VERSION ""

NS_ :

BS_:

BU_: CHUD_LS VKM_LS RCRM_LS MSM_RR_LS MSM_LR_LS CGM_LS BSM_LS VPM_LS ISRVM_LS DCAC_LS TouchPad_LS RSC_LS LVMPC_LS EOCM2B_K1_LS EOCM2A_K1_LS LCM_LS TIM_B_LS V2V_LS TCP_LS CSM_LS EOCM2B_K2_LS EOCM2A_K2_LS TIM_A_LS LVMNav_LS HFP_LS EDI_LS ARB_LS RSE_LS Dummy_LS VIS2_LS ICS_LS FCM_LS EOCM_F_LS VICM_LS AGC_LS MSM_P_LS OTIM_LS HVSM_R_LS HVSM_F_LS DVB_T_LS SBZA_R_LS PSD_R_LS PSD_L_LS UHP_Low UPA_LS STC_LS SBZA_L_LS PTM_LS ONSTAR_LS APA_LS TestTool_LS PHS_LS PDIM_LS CHM_LS RSA_LS AMP_LS HUD_LS MSM_LS HBSM_LS SCL_LS ECC_LS RadioHead_LS PEPS_LS IPC_LS AOS_LS SDM_LS TIM_LS BCM_LS

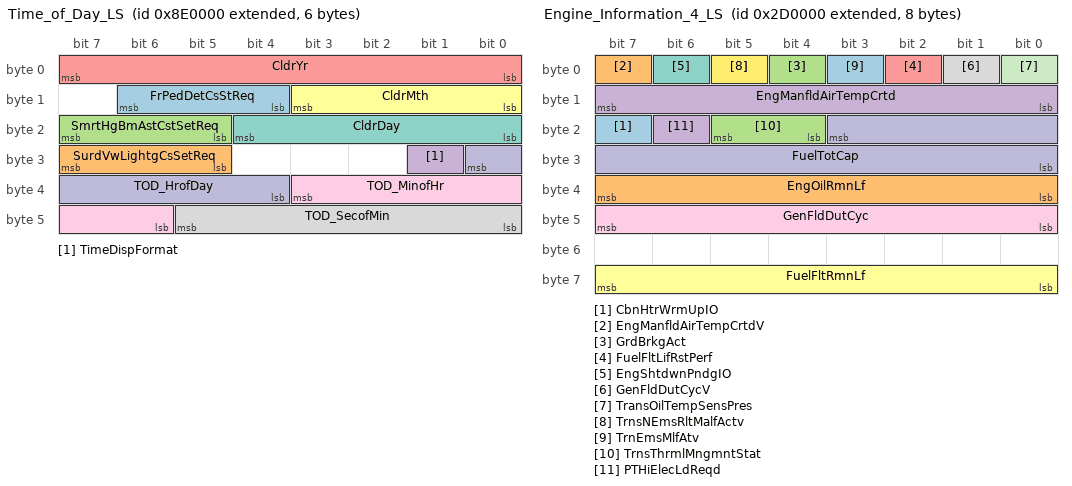
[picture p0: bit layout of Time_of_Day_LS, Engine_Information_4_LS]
BO_ 2156789760 Time_of_Day_LS: 6 RadioHead_LS
 SG_ FrPedDetCsStReq : 14|3@0+ (1,0) [0|7] ""  EOCM2B_K1_LS,EOCM2A_K1_LS,EOCM_F_LS,FCM_LS
 SG_ SurdVwLightgCsSetReq : 31|3@0+ (1,0) [0|7] ""  VPM_LS
 SG_ SmrtHgBmAstCstSetReq : 23|3@0+ (1,0) [0|7] ""  EOCM2A_K2_LS,FCM_LS,VIS2_LS
 SG_ TimeDispFormat : 25|1@0+ (1,0) [0|1] ""  RSE_LS,EOCM2B_K1_LS,EOCM2A_K1_LS,VPM_LS,LVMPC_LS,LVMNav_LS,EDI_LS,BSM_LS,VICM_LS,CHUD_LS,HUD_LS
 SG_ CldrYr : 7|8@0+ (1,2000) [2000|2255] "year"  RSE_LS,EOCM2B_K1_LS,EOCM2A_K1_LS,VPM_LS,LVMPC_LS,LVMNav_LS,EDI_LS,FCM_LS,BSM_LS,VICM_LS,EOCM_F_LS,UHP_Low,BCM_LS,CHUD_LS,HUD_LS
 SG_ CldrMth : 11|4@0+ (1,0) [0|15] ""  RSE_LS,EOCM2B_K1_LS,EOCM2A_K1_LS,VPM_LS,LVMPC_LS,LVMNav_LS,EDI_LS,FCM_LS,ECC_LS,BSM_LS,VICM_LS,EOCM_F_LS,UHP_Low,BCM_LS,CHUD_LS,HUD_LS
 SG_ CldrDay : 20|5@0+ (1,0) [0|31] "days"  RSE_LS,EOCM2B_K1_LS,EOCM2A_K1_LS,VPM_LS,LVMPC_LS,LVMNav_LS,EDI_LS,FCM_LS,ECC_LS,BSM_LS,VICM_LS,EOCM_F_LS,UHP_Low,BCM_LS,CHUD_LS,HUD_LS
 SG_ TOD_SecofMin : 45|6@0+ (1,0) [0|63] "s"  RSE_LS,EOCM2B_K1_LS,EOCM2A_K1_LS,VPM_LS,VIS2_LS,LVMPC_LS,FCM_LS,EDI_LS,LVMNav_LS,BSM_LS,VICM_LS,ECC_LS,UHP_Low,CHUD_LS,HUD_LS,BCM_LS
 SG_ TOD_MinofHr : 35|6@0+ (1,0) [0|63] "min"  RSE_LS,EOCM2B_K1_LS,EOCM2A_K1_LS,VPM_LS,VIS2_LS,LVMPC_LS,FCM_LS,EDI_LS,LVMNav_LS,BSM_LS,VICM_LS,ECC_LS,UHP_Low,CHUD_LS,HUD_LS,BCM_LS
 SG_ TOD_HrofDay : 24|5@0+ (1,0) [0|31] "hr"  RSE_LS,EOCM2B_K1_LS,EOCM2A_K1_LS,VPM_LS,VIS2_LS,LVMPC_LS,FCM_LS,EDI_LS,LVMNav_LS,BSM_LS,VICM_LS,ECC_LS,UHP_Low,CHUD_LS,HUD_LS,BCM_LS

BO_ 2155020288 Language_Selection_LS: 1 RadioHead_LS
 SG_ ChVolRq2 : 7|2@0+ (1,0) [0|3] ""  CGM_LS,CHM_LS,AMP_LS,RadioHead_LS
 SG_ LngSelExt : 5|6@0+ (1,0) [0|63] ""  CGM_LS,RSE_LS,TCP_LS,VPM_LS,RSC_LS,LVMNav_LS,RSA_LS,PDIM_LS,OTIM_LS,LVMPC_LS,UHP_Low,ONSTAR_LS,CHUD_LS,HUD_LS

BO_ 2150432768 Engine_Information_4_LS: 8 BCM_LS
 SG_ CbnHtrWrmUpIO : 23|1@0+ (1,0) [0|1] ""  IPC_LS,CGM_LS
 SG_ EngManfldAirTempCrtdV : 7|1@0+ (1,0) [0|1] ""  CGM_LS,ECC_LS
 SG_ GrdBrkgAct : 4|1@0+ (1,0) [0|1] ""  CSM_LS,RadioHead_LS,CGM_LS,IPC_LS
 SG_ EngManfldAirTempCrtd : 15|8@0+ (1,-40) [-40|215] "deg C"  CGM_LS,ECC_LS
 SG_ FuelFltLifRstPerf : 2|1@0+ (1,0) [0|1] ""  CSM_LS,CGM_LS,RadioHead_LS,IPC_LS
 SG_ FuelFltRmnLf : 63|8@0+ (0.392157,0) [0|100.000035] "%"  CSM_LS,CGM_LS,RadioHead_LS,IPC_LS
 SG_ EngShtdwnPndgIO : 6|1@0+ (1,0) [0|1] ""  CSM_LS,CGM_LS,RadioHead_LS,IPC_LS
 SG_ GenFldDutCycV : 1|1@0+ (1,0) [0|1] ""  CSM_LS,CGM_LS,RadioHead_LS,ECC_LS
 SG_ GenFldDutCyc : 47|8@0+ (0.392157,0) [0|100.000035] "%"  CSM_LS,CGM_LS,RadioHead_LS,ECC_LS
 SG_ FuelTotCap : 19|12@0+ (0.125,0) [0|511.875] "liters"  TCP_LS,CGM_LS,CSM_LS,RadioHead_LS,IPC_LS,ONSTAR_LS
 SG_ TransOilTempSensPres : 0|1@0+ (1,0) [0|1] ""  CSM_LS,CGM_LS,RadioHead_LS,IPC_LS
 SG_ TrnsNEmsRltMalfActv : 5|1@0+ (1,0) [0|1] ""  CSM_LS,CGM_LS,RadioHead_LS,IPC_LS
 SG_ TrnEmsMlfAtv : 3|1@0+ (1,0) [0|1] ""  CSM_LS,CGM_LS,RadioHead_LS,IPC_LS
 SG_ EngOilRmnLf : 39|8@0+ (0.392157,0) [0|100.000035] "%"  CSM_LS,TCP_LS,CGM_LS,RadioHead_LS,ONSTAR_LS,IPC_LS
 SG_ TrnsThrmlMngmntStat : 21|2@0+ (1,0) [0|3] ""  CSM_LS,TCP_LS,CGM_LS,RadioHead_LS,ONSTAR_LS,IPC_LS
 SG_ PTHiElecLdReqd : 22|1@0+ (1,0) [0|1] ""  CSM_LS,CGM_LS,RadioHead_LS,IPC_LS,ECC_LS

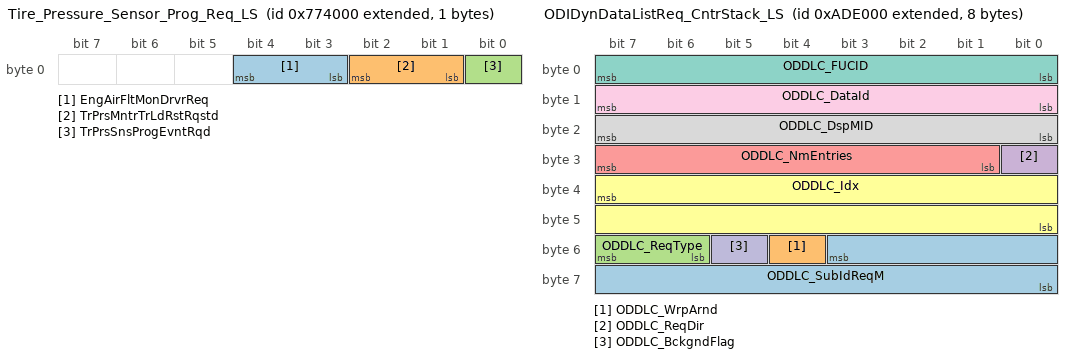
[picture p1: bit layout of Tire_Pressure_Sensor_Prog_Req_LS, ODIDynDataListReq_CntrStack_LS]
BO_ 2155298816 Tire_Pressure_Sensor_Prog_Req_LS: 1 IPC_LS
 SG_ EngAirFltMonDrvrReq : 4|2@0+ (1,0) [0|3] ""  BCM_LS
 SG_ TrPrsMntrTrLdRstRqstd : 2|2@0+ (1,0) [0|3] ""  BCM_LS
 SG_ TrPrsSnsProgEvntRqd : 0|1@0+ (1,0) [0|1] ""  BCM_LS

BO_ 2158878720 ODIDynDataListReq_CntrStack_LS: 8 RadioHead_LS
 SG_ ODDLC_SubIdReqM : 51|12@0+ (1,0) [0|4095] ""  BCM_LS,TCP_LS,VIS2_LS,FCM_LS,PDIM_LS,UHP_Low,ONSTAR_LS
 SG_ ODDLC_WrpArnd : 52|1@0+ (1,0) [0|1] ""  BCM_LS,TCP_LS,VIS2_LS,FCM_LS,PDIM_LS,UHP_Low,ONSTAR_LS
 SG_ ODDLC_ReqType : 55|2@0+ (1,0) [0|3] ""  BCM_LS,TCP_LS,VIS2_LS,FCM_LS,PDIM_LS,UHP_Low,ONSTAR_LS
 SG_ ODDLC_ReqDir : 24|1@0+ (1,0) [0|1] ""  BCM_LS,TCP_LS,VIS2_LS,FCM_LS,PDIM_LS,UHP_Low,ONSTAR_LS
 SG_ ODDLC_NmEntries : 31|7@0+ (1,0) [0|127] ""  BCM_LS,TCP_LS,VIS2_LS,FCM_LS,PDIM_LS,UHP_Low,ONSTAR_LS
 SG_ ODDLC_Idx : 39|16@0+ (1,0) [0|65535] ""  BCM_LS,TCP_LS,VIS2_LS,FCM_LS,PDIM_LS,UHP_Low,ONSTAR_LS
 SG_ ODDLC_FUCID : 7|8@0+ (1,0) [0|255] ""  BCM_LS,TCP_LS,VIS2_LS,FCM_LS,PDIM_LS,UHP_Low,ONSTAR_LS
 SG_ ODDLC_DspMID : 23|8@0+ (1,0) [0|255] ""  BCM_LS,TCP_LS,VIS2_LS,FCM_LS,PDIM_LS,UHP_Low,ONSTAR_LS
 SG_ ODDLC_DataId : 15|8@0+ (1,0) [0|255] ""  BCM_LS,TCP_LS,VIS2_LS,FCM_LS,PDIM_LS,UHP_Low,ONSTAR_LS
 SG_ ODDLC_BckgndFlag : 53|1@0+ (1,0) [0|1] ""  BCM_LS,TCP_LS,VIS2_LS,FCM_LS,PDIM_LS,UHP_Low,ONSTAR_LS

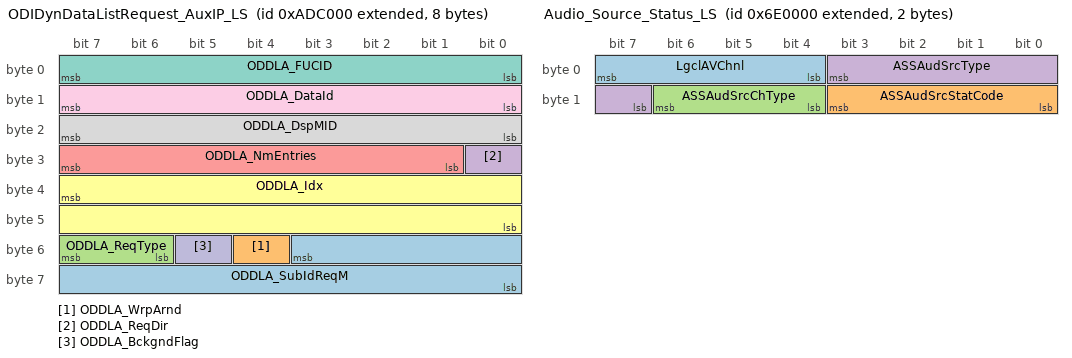
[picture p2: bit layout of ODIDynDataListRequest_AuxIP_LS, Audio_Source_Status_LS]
BO_ 2158870528 ODIDynDataListRequest_AuxIP_LS: 8 HUD_LS
 SG_ ODDLA_SubIdReqM : 51|12@0+ (1,0) [0|4095] ""  IPC_LS,VIS2_LS,FCM_LS,RadioHead_LS,UHP_Low,ONSTAR_LS
 SG_ ODDLA_WrpArnd : 52|1@0+ (1,0) [0|1] ""  IPC_LS,VIS2_LS,FCM_LS,RadioHead_LS,UHP_Low,ONSTAR_LS
 SG_ ODDLA_ReqType : 55|2@0+ (1,0) [0|3] ""  IPC_LS,VIS2_LS,FCM_LS,RadioHead_LS,UHP_Low,ONSTAR_LS
 SG_ ODDLA_ReqDir : 24|1@0+ (1,0) [0|1] ""  IPC_LS,VIS2_LS,FCM_LS,RadioHead_LS,UHP_Low,ONSTAR_LS
 SG_ ODDLA_NmEntries : 31|7@0+ (1,0) [0|127] ""  IPC_LS,VIS2_LS,FCM_LS,RadioHead_LS,UHP_Low,ONSTAR_LS
 SG_ ODDLA_Idx : 39|16@0+ (1,0) [0|65535] ""  IPC_LS,VIS2_LS,FCM_LS,RadioHead_LS,UHP_Low,ONSTAR_LS
 SG_ ODDLA_FUCID : 7|8@0+ (1,0) [0|255] ""  IPC_LS,VIS2_LS,FCM_LS,RadioHead_LS,UHP_Low,ONSTAR_LS
 SG_ ODDLA_DspMID : 23|8@0+ (1,0) [0|255] ""  IPC_LS,VIS2_LS,FCM_LS,RadioHead_LS,UHP_Low,ONSTAR_LS
 SG_ ODDLA_DataId : 15|8@0+ (1,0) [0|255] ""  IPC_LS,VIS2_LS,FCM_LS,RadioHead_LS,UHP_Low,ONSTAR_LS
 SG_ ODDLA_BckgndFlag : 53|1@0+ (1,0) [0|1] ""  IPC_LS,VIS2_LS,FCM_LS,RadioHead_LS,UHP_Low,ONSTAR_LS

BO_ 2154692608 Audio_Source_Status_LS: 2 ONSTAR_LS
 SG_ LgclAVChnl : 7|4@0+ (1,0) [0|15] ""  V2V_LS,CSM_LS,LVMNav_LS,RadioHead_LS,ISRVM_LS,HBSM_LS
 SG_ ASSAudSrcStatCode : 11|4@0+ (1,0) [0|15] ""  CSM_LS,OTIM_LS,RadioHead_LS,ECC_LS
 SG_ ASSAudSrcChType : 14|3@0+ (1,0) [0|7] ""  CSM_LS,OTIM_LS,RadioHead_LS,ECC_LS
 SG_ ASSAudSrcType : 3|5@0+ (1,0) [0|31] ""  CSM_LS,OTIM_LS,RadioHead_LS,ECC_LS

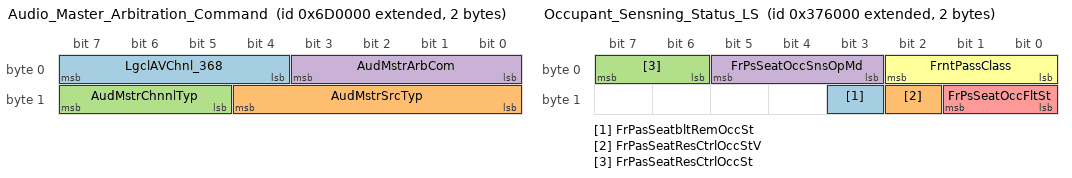
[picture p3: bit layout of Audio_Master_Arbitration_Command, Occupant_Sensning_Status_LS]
BO_ 2154627072 Audio_Master_Arbitration_Command: 2 RadioHead_LS
 SG_ LgclAVChnl_368 : 7|4@0+ (1,0) [0|15] ""  CGM_LS,TCP_LS,DVB_T_LS,UHP_Low,ONSTAR_LS
 SG_ AudMstrSrcTyp : 12|5@0+ (1,0) [0|31] ""  CGM_LS,LVMNav_LS,TCP_LS,DVB_T_LS,UHP_Low,ONSTAR_LS
 SG_ AudMstrChnnlTyp : 15|3@0+ (1,0) [0|7] ""  CGM_LS,LVMNav_LS,TCP_LS,DVB_T_LS,UHP_Low,ONSTAR_LS
 SG_ AudMstrArbCom : 3|4@0+ (1,0) [0|15] ""  CGM_LS,LVMNav_LS,TCP_LS,DVB_T_LS,UHP_Low,ONSTAR_LS

BO_ 2151112704 Occupant_Sensning_Status_LS: 2 AOS_LS
 SG_ FrPasSeatbltRemOccSt : 11|1@0+ (1,0) [0|1] ""  BCM_LS,CSM_LS,CGM_LS,RadioHead_LS,SDM_LS
 SG_ FrPasSeatResCtrlOccStV : 10|1@0+ (1,0) [0|1] ""  CSM_LS,CGM_LS,RadioHead_LS,ECC_LS,SDM_LS
 SG_ FrPasSeatResCtrlOccSt : 7|2@0+ (1,0) [0|3] ""  CSM_LS,CGM_LS,RadioHead_LS,ECC_LS,SDM_LS
 SG_ FrPsSeatOccSnsOpMd : 5|3@0+ (1,0) [0|7] "N/A"  CGM_LS,SDM_LS
 SG_ FrPsSeatOccFltSt : 9|2@0+ (1,0) [0|3] "N/A"  CSM_LS,MSM_P_LS,MSM_LS,CGM_LS,RadioHead_LS,SDM_LS
 SG_ FrntPassClass : 2|3@0+ (1,0) [0|7] ""  CSM_LS,MSM_P_LS,MSM_LS,CGM_LS,RadioHead_LS,SDM_LS

BO_ 2153938944 Remote_Reflash_Req_LS: 1 RadioHead_LS
 SG_ RmtRflshMdReqtd : 7|1@0+ (1,0) [0|1] ""  BCM_LS

BO_ 2028 USDT_Resp_From_VICM_LS: 8 VICM_LS
 SG_ DgnInf : 7|64@0+ (1,0) [0|1.84467440737096E+019] ""  CSM_LS,CGM_LS,TCP_LS,ONSTAR_LS,TestTool_LS

BO_ 2159239168 ODI_TEL_2_OTIM_LS: 8 ONSTAR_LS
 SG_ ODI_TEL2OTIM : 7|64@0+ (1,0) [0|1.84467440737096E+019] ""  CGM_LS,OTIM_LS

BO_ 2159230976 ODI_OTIM_2_TEL_LS: 8 OTIM_LS
 SG_ ODI_OTIM2TEL : 7|64@0+ (1,0) [0|1.84467440737096E+019] ""  CGM_LS,TCP_LS,ONSTAR_LS

BO_ 2159222784 ODI_PDIM_2_CenterStack_LS: 8 PDIM_LS
 SG_ ODI_PDIM2CntrStck : 7|64@0+ (1,0) [0|1.84467440737096E+019] ""  CGM_LS,CSM_LS,RadioHead_LS

BO_ 2159214592 ODI_CenterStack_2_PDIM_LS: 8 RadioHead_LS
 SG_ ODI_CntrStck2PDIM : 7|64@0+ (1,0) [0|1.84467440737096E+019] ""  CGM_LS,PDIM_LS

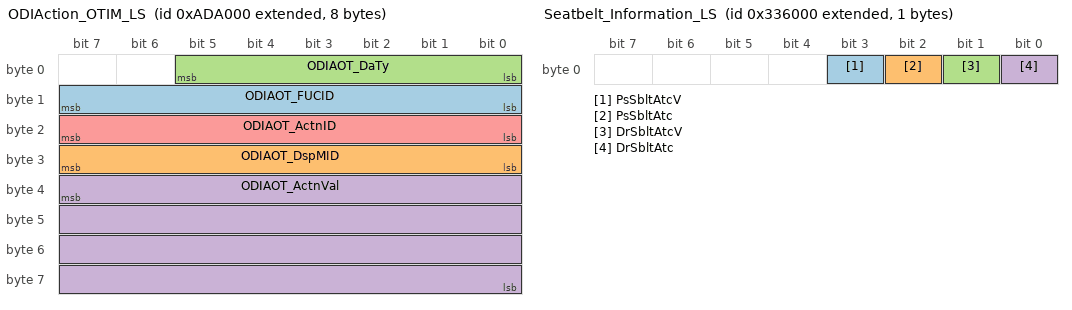
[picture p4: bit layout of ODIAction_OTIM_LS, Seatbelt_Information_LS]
BO_ 2158862336 ODIAction_OTIM_LS: 8 OTIM_LS
 SG_ ODIAOT_FUCID : 15|8@0+ (1,0) [0|255] ""  CGM_LS,TCP_LS,ONSTAR_LS
 SG_ ODIAOT_DspMID : 31|8@0+ (1,0) [0|255] ""  CGM_LS,TCP_LS,ONSTAR_LS
 SG_ ODIAOT_DaTy : 5|6@0+ (1,0) [0|63] ""  CGM_LS,TCP_LS,ONSTAR_LS
 SG_ ODIAOT_ActnVal : 39|32@0+ (1,0) [0|4294967295] ""  CGM_LS,TCP_LS,ONSTAR_LS
 SG_ ODIAOT_ActnID : 23|8@0+ (1,0) [0|255] ""  CGM_LS,TCP_LS,ONSTAR_LS

BO_ 2150662144 Environment_Id_Resp_3_LS: 3 IPC_LS
 SG_ EnvIdRsp3 : 7|16@0+ (1,0) [0|65535] ""  BCM_LS
 SG_ EnvIdRspSt3 : 17|2@0+ (1,0) [0|3] ""  BCM_LS

BO_ 2150653952 Environment_Id_Resp_2_LS: 3 ECC_LS
 SG_ EnvIdRspSt2 : 17|2@0+ (1,0) [0|3] ""  CGM_LS,BCM_LS
 SG_ EnvIdRsp2 : 7|16@0+ (1,0) [0|65535] ""  CGM_LS,BCM_LS

BO_ 2150850560 Seatbelt_Information_LS: 1 SDM_LS
 SG_ PsSbltAtcV : 3|1@0+ (1,0) [0|1] ""  EOCM2B_K1_LS,EOCM2A_K1_LS,CSM_LS,TCP_LS,V2V_LS,CGM_LS,ECC_LS,RadioHead_LS,BCM_LS,ONSTAR_LS,AOS_LS
 SG_ PsSbltAtc : 2|1@0+ (1,0) [0|1] ""  EOCM2B_K1_LS,EOCM2A_K1_LS,CSM_LS,TCP_LS,V2V_LS,CGM_LS,ECC_LS,RadioHead_LS,BCM_LS,ONSTAR_LS,AOS_LS
 SG_ DrSbltAtcV : 1|1@0+ (1,0) [0|1] ""  EOCM2B_K1_LS,EOCM2A_K1_LS,CSM_LS,TCP_LS,FCM_LS,V2V_LS,CGM_LS,RadioHead_LS,EOCM_F_LS,ONSTAR_LS,BCM_LS
 SG_ DrSbltAtc : 0|1@0+ (1,0) [0|1] ""  EOCM2B_K1_LS,EOCM2A_K1_LS,CSM_LS,TCP_LS,FCM_LS,V2V_LS,CGM_LS,RadioHead_LS,EOCM_F_LS,ONSTAR_LS,BCM_LS

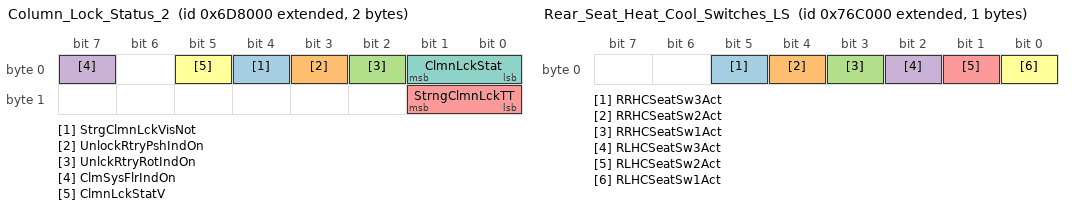
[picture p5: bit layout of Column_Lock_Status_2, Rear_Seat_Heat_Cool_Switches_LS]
BO_ 2154659840 Column_Lock_Status_2: 2 SCL_LS
 SG_ StrgClmnLckVisNot : 4|1@0+ (1,0) [0|1] ""  CGM_LS,IPC_LS
 SG_ UnlockRtryPshIndOn : 3|1@0+ (1,0) [0|1] ""  CGM_LS,IPC_LS
 SG_ UnlckRtryRotIndOn : 2|1@0+ (1,0) [0|1] ""  CGM_LS,IPC_LS
 SG_ ClmSysFlrIndOn : 7|1@0+ (1,0) [0|1] ""  CGM_LS,IPC_LS
 SG_ StrngClmnLckTT : 9|2@0+ (1,0) [0|3] ""  CGM_LS,IPC_LS
 SG_ ClmnLckStatV : 5|1@0+ (1,0) [0|1] ""  CGM_LS,BCM_LS
 SG_ ClmnLckStat : 1|2@0+ (1,0) [0|3] ""  CGM_LS,BCM_LS

BO_ 2154938368 Fob_Programming_Mode_Status_LS: 1 BCM_LS
 SG_ FobProgMdStat : 1|2@0+ (1,0) [0|3] ""  CGM_LS,IPC_LS

BO_ 2155266048 Rear_Seat_Heat_Cool_Switches_LS: 1 CGM_LS
 SG_ RRHCSeatSw3Act : 5|1@0+ (1,0) [0|1] ""  BCM_LS,HVSM_R_LS
 SG_ RRHCSeatSw2Act : 4|1@0+ (1,0) [0|1] ""  BCM_LS,HVSM_R_LS
 SG_ RRHCSeatSw1Act : 3|1@0+ (1,0) [0|1] ""  BCM_LS,HVSM_R_LS
 SG_ RLHCSeatSw3Act : 2|1@0+ (1,0) [0|1] ""  BCM_LS,HVSM_R_LS
 SG_ RLHCSeatSw2Act : 1|1@0+ (1,0) [0|1] ""  BCM_LS,HVSM_R_LS
 SG_ RLHCSeatSw1Act : 0|1@0+ (1,0) [0|1] ""  BCM_LS,HVSM_R_LS

BO_ 2155249664 Rear_Seat_Heat_Cool_Control_LS: 4 HVSM_R_LS
 SG_ RRHCSMInd3 : 8|1@0+ (1,0) [0|1] ""  CGM_LS,RSC_LS,RSA_LS,ECC_LS,BCM_LS
 SG_ RRHCSMInd2 : 9|1@0+ (1,0) [0|1] ""  CGM_LS,RSC_LS,RSA_LS,ECC_LS,BCM_LS
 SG_ RRHCSMInd1 : 10|1@0+ (1,0) [0|1] ""  CGM_LS,RSC_LS,RSA_LS,ECC_LS,BCM_LS
 SG_ RRHCSMIndReq : 12|2@0+ (1,0) [0|3] ""  CGM_LS,RSC_LS,RSA_LS,ECC_LS,BCM_LS
 SG_ RRHCSLSeatLev5 : 24|1@0+ (1,0) [0|1] ""  CGM_LS,IPC_LS,RSC_LS,RSA_LS,ECC_LS,BCM_LS
 SG_ RRHCSLSeatLev4 : 25|1@0+ (1,0) [0|1] ""  CGM_LS,IPC_LS,RSC_LS,RSA_LS,ECC_LS,BCM_LS
 SG_ RRHCSLSeatLev3 : 26|1@0+ (1,0) [0|1] ""  CGM_LS,IPC_LS,RSC_LS,RSA_LS,ECC_LS,BCM_LS
 SG_ RRHCSLSeatLev2 : 27|1@0+ (1,0) [0|1] ""  CGM_LS,IPC_LS,RSC_LS,RSA_LS,ECC_LS,BCM_LS
 SG_ RRHCSLSeatLev1 : 28|1@0+ (1,0) [0|1] ""  CGM_LS,IPC_LS,RSC_LS,RSA_LS,ECC_LS,BCM_LS
 SG_ RRHCSLIndReq : 30|2@0+ (1,0) [0|3] ""  CGM_LS,IPC_LS,RSC_LS,RSA_LS,ECC_LS,BCM_LS
 SG_ RLHCSMInd3 : 0|1@0+ (1,0) [0|1] ""  CGM_LS,RSC_LS,RSA_LS,ECC_LS,BCM_LS
 SG_ RLHCSMInd2 : 1|1@0+ (1,0) [0|1] ""  CGM_LS,RSC_LS,RSA_LS,ECC_LS,BCM_LS
 SG_ RLHCSMInd1 : 2|1@0+ (1,0) [0|1] ""  CGM_LS,RSC_LS,RSA_LS,ECC_LS,BCM_LS
 SG_ RLHCSMIndReq : 4|2@0+ (1,0) [0|3] ""  CGM_LS,RSC_LS,RSA_LS,ECC_LS,BCM_LS
 SG_ RLHCSLSeatLev5 : 16|1@0+ (1,0) [0|1] ""  CGM_LS,IPC_LS,RSC_LS,RSA_LS,ECC_LS,BCM_LS
 SG_ RLHCSLSeatLev4 : 17|1@0+ (1,0) [0|1] ""  CGM_LS,IPC_LS,RSC_LS,RSA_LS,ECC_LS,BCM_LS
 SG_ RLHCSLSeatLev3 : 18|1@0+ (1,0) [0|1] ""  CGM_LS,IPC_LS,RSC_LS,RSA_LS,ECC_LS,BCM_LS
 SG_ RLHCSLSeatLev2 : 19|1@0+ (1,0) [0|1] ""  CGM_LS,IPC_LS,RSC_LS,RSA_LS,ECC_LS,BCM_LS
 SG_ RLHCSLSeatLev1 : 20|1@0+ (1,0) [0|1] ""  CGM_LS,IPC_LS,RSC_LS,RSA_LS,ECC_LS,BCM_LS
 SG_ RLHCSLIndReq : 22|2@0+ (1,0) [0|3] ""  CGM_LS,IPC_LS,RSC_LS,RSA_LS,ECC_LS,BCM_LS

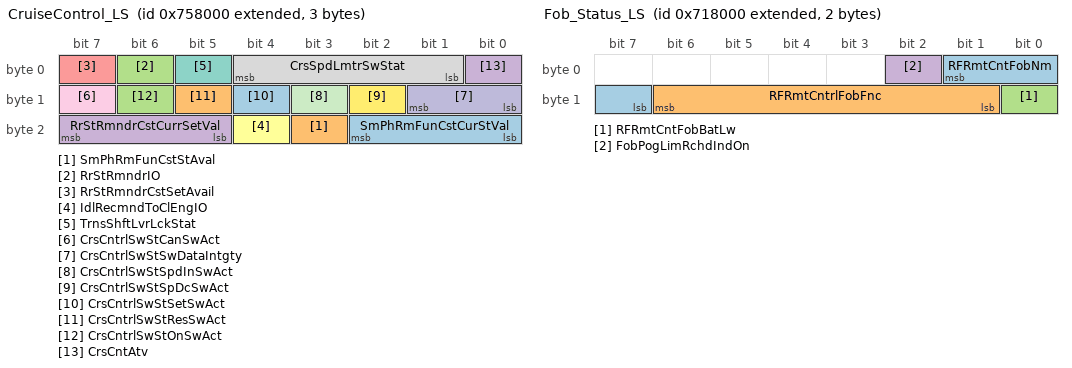
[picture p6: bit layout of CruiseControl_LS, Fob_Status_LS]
BO_ 2155184128 CruiseControl_LS: 3 BCM_LS
 SG_ SmPhRmFunCstCurStVal : 18|3@0+ (1,0) [0|7] ""  CGM_LS,CSM_LS,RadioHead_LS
 SG_ SmPhRmFunCstStAval : 19|1@0+ (1,0) [0|1] ""  CGM_LS,CSM_LS,RadioHead_LS
 SG_ RrStRmndrIO : 6|1@0+ (1,0) [0|1] ""  IPC_LS,CGM_LS
 SG_ RrStRmndrCstCurrSetVal : 23|3@0+ (1,0) [0|7] ""  CGM_LS,CSM_LS,RadioHead_LS
 SG_ RrStRmndrCstSetAvail : 7|1@0+ (1,0) [0|1] ""  CGM_LS,CSM_LS,RadioHead_LS
 SG_ IdlRecmndToClEngIO : 20|1@0+ (1,0) [0|1] ""  IPC_LS,CGM_LS
 SG_ TrnsShftLvrLckStat : 5|1@0+ (1,0) [0|1] ""  CGM_LS,CSM_LS,RadioHead_LS
 SG_ CrsSpdLmtrSwStat : 4|4@0+ (1,0) [0|15] ""  CSM_LS,CGM_LS,RadioHead_LS,SDM_LS,IPC_LS
 SG_ CrsCntrlSwStCanSwAct : 15|1@0+ (1,0) [0|1] ""  CSM_LS,CGM_LS,RadioHead_LS,FCM_LS,VPM_LS,IPC_LS,SDM_LS
 SG_ CrsCntrlSwStSwDataIntgty : 9|2@0+ (1,0) [0|3] ""  CSM_LS,CGM_LS,RadioHead_LS,FCM_LS,VPM_LS,IPC_LS,SDM_LS
 SG_ CrsCntrlSwStSpdInSwAct : 11|1@0+ (1,0) [0|1] ""  CSM_LS,CGM_LS,RadioHead_LS,FCM_LS,VPM_LS,IPC_LS,SDM_LS
 SG_ CrsCntrlSwStSpDcSwAct : 10|1@0+ (1,0) [0|1] ""  CSM_LS,CGM_LS,RadioHead_LS,FCM_LS,VPM_LS,IPC_LS,SDM_LS
 SG_ CrsCntrlSwStSetSwAct : 12|1@0+ (1,0) [0|1] ""  CSM_LS,CGM_LS,RadioHead_LS,FCM_LS,VPM_LS,IPC_LS,SDM_LS
 SG_ CrsCntrlSwStResSwAct : 13|1@0+ (1,0) [0|1] ""  CSM_LS,CGM_LS,RadioHead_LS,FCM_LS,VPM_LS,IPC_LS,SDM_LS
 SG_ CrsCntrlSwStOnSwAct : 14|1@0+ (1,0) [0|1] ""  CSM_LS,CGM_LS,RadioHead_LS,FCM_LS,VPM_LS,IPC_LS,SDM_LS
 SG_ CrsCntAtv : 0|1@0+ (1,0) [0|1] ""  CSM_LS,CGM_LS,RadioHead_LS,VIS2_LS,FCM_LS,IPC_LS,SDM_LS

BO_ 2155167744 Power_Mode_Info_LS: 3 BCM_LS
 SG_ ClsEngCmprtmtToStrtVehIO : 23|1@0+ (1,0) [0|1] ""  IPC_LS,CGM_LS
 SG_ PrsCltchPrsStrtAgnIO : 22|1@0+ (1,0) [0|1] ""  CGM_LS,IPC_LS
 SG_ PrsStrtAgnIO : 21|1@0+ (1,0) [0|1] ""  CGM_LS,IPC_LS
 SG_ AutoShtdwnDsblIO : 11|1@0+ (1,0) [0|1] ""  CGM_LS,IPC_LS
 SG_ ShftToNtrlIO : 1|1@0+ (1,0) [0|1] ""  IPC_LS,CGM_LS
 SG_ AppPrkBrkIO : 12|1@0+ (1,0) [0|1] ""  IPC_LS,CGM_LS
 SG_ NRmtDtctdRstrtAllwd : 20|1@0+ (1,0) [0|1] ""  CGM_LS,IPC_LS
 SG_ NRmtDtdPsCluRstIO : 13|1@0+ (1,0) [0|1] ""  CGM_LS,IPC_LS
 SG_ SecPwrMdPshBtnAtv : 3|1@0+ (1,0) [0|1] ""  VKM_LS,CGM_LS,PEPS_LS
 SG_ TSLgMdPwrCtOWAtv : 19|1@0+ (1,0) [0|1] ""  CGM_LS
 SG_ PrsBtnAgnTTrnEngOffIO : 18|1@0+ (1,0) [0|1] ""  CGM_LS,IPC_LS
 SG_ NRmtDtdPsBrkRstIO : 17|1@0+ (1,0) [0|1] ""  CGM_LS,IPC_LS
 SG_ NoReDetInOn : 16|1@0+ (1,0) [0|1] ""  CGM_LS,IPC_LS
 SG_ ApplyCltPdlIO : 15|1@0+ (1,0) [0|1] ""  CGM_LS,IPC_LS
 SG_ VehMovState : 10|3@0+ (1,0) [0|7] ""  RCRM_LS,PEPS_LS,ICS_LS,MSM_RR_LS,MSM_LR_LS,EOCM_F_LS,CGM_LS,VIS2_LS,VPM_LS,ISRVM_LS,LVMNav_LS,FCM_LS,SBZA_R_LS,PSD_R_LS,PSD_L_LS,SBZA_L_LS,RadioHead_LS,MSM_P_LS,MSM_LS,TCP_LS,ONSTAR_LS,UPA_LS,APA_LS
 SG_ TrStLgMdAtv : 7|1@0+ (1,0) [0|1] ""  CGM_LS,CHUD_LS,VKM_LS,RCRM_LS,MSM_RR_LS,MSM_LR_LS,VPM_LS,ISRVM_LS,DCAC_LS,TouchPad_LS,RSC_LS,LVMPC_LS,LCM_LS,TIM_B_LS,V2V_LS,TCP_LS,TIM_A_LS,LVMNav_LS,HFP_LS,ARB_LS,VIS2_LS,ICS_LS,FCM_LS,AGC_LS,MSM_P_LS,OTIM_LS,HVSM_R_LS,HVSM_F_LS,DVB_T_LS,SBZA_R_LS,PSD_R_LS,PSD_L_LS,UHP_Low,UPA_LS,STC_LS,SBZA_L_LS,PTM_LS,ONSTAR_LS,APA_LS,PDIM_LS,CHM_LS,RSA_LS,AMP_LS,HUD_LS,MSM_LS,HBSM_LS,SCL_LS,PEPS_LS,IPC_LS,AOS_LS,SDM_LS,TIM_LS,PHS_LS,ECC_LS,RadioHead_LS
 SG_ TransModInactIO : 5|1@0+ (1,0) [0|1] ""  CGM_LS,IPC_LS
 SG_ TransModActIO : 4|1@0+ (1,0) [0|1] ""  CGM_LS,IPC_LS
 SG_ ApplyBrkPdlIO : 14|1@0+ (1,0) [0|1] ""  CGM_LS,IPC_LS
 SG_ Ky_IdDevPr : 2|1@0+ (1,0) [0|1] ""  ONSTAR_LS,TCP_LS,CGM_LS,STC_LS,IPC_LS,SCL_LS,CHUD_LS,HUD_LS,MSM_P_LS,MSM_LS,RadioHead_LS
 SG_ KylsStrtUseTxPckIO : 6|1@0+ (1,0) [0|1] ""  CGM_LS,IPC_LS
 SG_ ShftPrkIO : 0|1@0+ (1,0) [0|1] ""  CGM_LS,IPC_LS

BO_ 2154921984 Fob_Status_LS: 2 BCM_LS
 SG_ RFRmtCntFobNm : 1|3@0+ (1,0) [0|7] ""  TCP_LS,CGM_LS,ARB_LS,ONSTAR_LS,PEPS_LS,PSD_R_LS,PSD_L_LS,BSM_LS,VICM_LS,STC_LS,CHUD_LS,HUD_LS,MSM_P_LS,MSM_LS,LCM_LS,PTM_LS,IPC_LS
 SG_ RFRmtCntrlFobFnc : 14|6@0+ (1,0) [0|63] ""  TCP_LS,CGM_LS,ARB_LS,ONSTAR_LS,PEPS_LS,PSD_R_LS,PSD_L_LS,BSM_LS,VICM_LS,STC_LS,CHUD_LS,HUD_LS,MSM_P_LS,MSM_LS,LCM_LS,PTM_LS,IPC_LS
 SG_ RFRmtCntFobBatLw : 8|1@0+ (1,0) [0|1] ""  TCP_LS,CGM_LS,ARB_LS,ONSTAR_LS,PEPS_LS,PSD_R_LS,PSD_L_LS,BSM_LS,VICM_LS,STC_LS,CHUD_LS,HUD_LS,MSM_P_LS,MSM_LS,LCM_LS,PTM_LS,IPC_LS
 SG_ FobPogLimRchdIndOn : 2|1@0+ (1,0) [0|1] ""  CGM_LS,IPC_LS

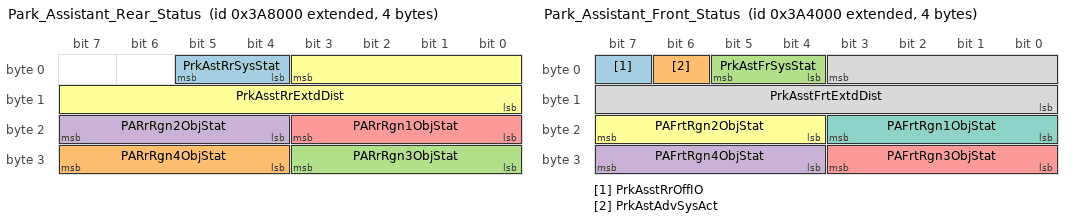
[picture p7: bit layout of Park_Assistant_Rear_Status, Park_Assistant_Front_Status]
BO_ 2151317504 Park_Assistant_Rear_Status: 4 APA_LS
 SG_ PrkAstRrSysStat : 5|2@0+ (1,0) [0|3] ""  TCP_LS,CGM_LS,VPM_LS,IPC_LS,SBZA_R_LS,SBZA_L_LS,ONSTAR_LS,CSM_LS,RadioHead_LS
 SG_ PARrRgn4ObjStat : 31|4@0+ (1,0) [0|15] ""  CGM_LS,VPM_LS,SBZA_R_LS,SBZA_L_LS,IPC_LS,CSM_LS,RadioHead_LS
 SG_ PARrRgn3ObjStat : 27|4@0+ (1,0) [0|15] ""  CGM_LS,VPM_LS,SBZA_R_LS,SBZA_L_LS,IPC_LS,CSM_LS,RadioHead_LS
 SG_ PARrRgn2ObjStat : 23|4@0+ (1,0) [0|15] ""  CGM_LS,VPM_LS,SBZA_R_LS,SBZA_L_LS,IPC_LS,CSM_LS,RadioHead_LS
 SG_ PARrRgn1ObjStat : 19|4@0+ (1,0) [0|15] ""  CGM_LS,VPM_LS,SBZA_R_LS,SBZA_L_LS,IPC_LS,CSM_LS,RadioHead_LS
 SG_ PrkAsstRrExtdDist : 3|12@0+ (0.01,0) [0|40.95] "m"  CGM_LS,SBZA_R_LS,SBZA_L_LS,IPC_LS,CSM_LS,RadioHead_LS

BO_ 2151301120 Park_Assistant_Front_Status: 4 APA_LS
 SG_ PrkAsstRrOffIO : 7|1@0+ (1,0) [0|1] ""  CGM_LS,IPC_LS
 SG_ PrkAstAdvSysAct : 6|1@0+ (1,0) [0|1] ""  FCM_LS,EOCM2B_K2_LS,EOCM2A_K2_LS,CGM_LS,BCM_LS,EOCM_F_LS
 SG_ PrkAstFrSysStat : 5|2@0+ (1,0) [0|3] ""  TCP_LS,EOCM2B_K2_LS,EOCM2A_K2_LS,CGM_LS,ONSTAR_LS,CSM_LS,RadioHead_LS,IPC_LS
 SG_ PAFrtRgn4ObjStat : 31|4@0+ (1,0) [0|15] ""  EOCM2B_K2_LS,EOCM2A_K2_LS,CGM_LS,IPC_LS,CSM_LS,RadioHead_LS
 SG_ PAFrtRgn3ObjStat : 27|4@0+ (1,0) [0|15] ""  EOCM2B_K2_LS,EOCM2A_K2_LS,CGM_LS,IPC_LS,CSM_LS,RadioHead_LS
 SG_ PAFrtRgn2ObjStat : 23|4@0+ (1,0) [0|15] ""  EOCM2B_K2_LS,EOCM2A_K2_LS,CGM_LS,IPC_LS,CSM_LS,RadioHead_LS
 SG_ PAFrtRgn1ObjStat : 19|4@0+ (1,0) [0|15] ""  EOCM2B_K2_LS,EOCM2A_K2_LS,CGM_LS,IPC_LS,CSM_LS,RadioHead_LS
 SG_ PrkAsstFrtExtdDist : 3|12@0+ (0.01,0) [0|40.95] "m"  EOCM2B_K2_LS,EOCM2A_K2_LS,CGM_LS,VPM_LS,IPC_LS,CSM_LS,RadioHead_LS

BO_ 2159083520 ODI_TEL_2_IPC_LS: 8 ONSTAR_LS
 SG_ ODI_TEL2IPC : 7|64@0+ (1,0) [0|1.84467440737096E+019] ""  CGM_LS

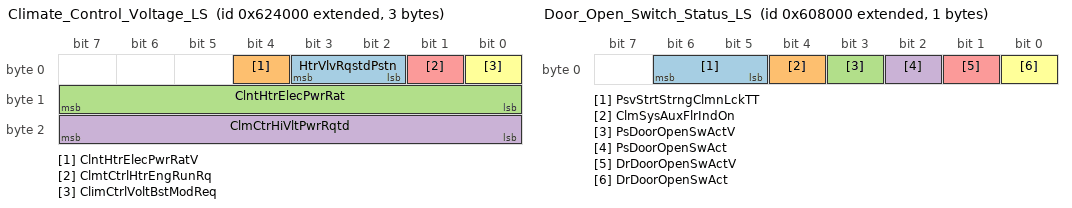
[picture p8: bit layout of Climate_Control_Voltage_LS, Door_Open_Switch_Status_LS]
BO_ 2153922560 Climate_Control_Voltage_LS: 3 ECC_LS
 SG_ HtrVlvRqstdPstn : 3|2@0+ (1,0) [0|3] ""  CGM_LS,BSM_LS,VICM_LS
 SG_ ClntHtrElecPwrRatV : 4|1@0+ (1,0) [0|1] ""  CGM_LS,BSM_LS,VICM_LS,CSM_LS,RadioHead_LS
 SG_ ClntHtrElecPwrRat : 15|8@0+ (0.04,0) [0|10.2] "kW"  CGM_LS,BSM_LS,VICM_LS,CSM_LS,RadioHead_LS
 SG_ ClmCtrHiVltPwrRqtd : 23|8@0+ (0.1,0) [0|25.5] "kW"  CGM_LS,BSM_LS,VICM_LS
 SG_ ClmtCtrlHtrEngRunRq : 1|1@0+ (1,0) [0|1] ""  CGM_LS,BCM_LS
 SG_ ClimCtrlVoltBstModReq : 0|1@0+ (1,0) [0|1] ""  CGM_LS,BCM_LS

BO_ 2153807872 Door_Open_Switch_Status_LS: 1 PEPS_LS
 SG_ PsvStrtStrngClmnLckTT : 6|2@0+ (1,0) [0|3] ""  CGM_LS,IPC_LS
 SG_ ClmSysAuxFlrIndOn : 4|1@0+ (1,0) [0|1] ""  CGM_LS,IPC_LS
 SG_ PsDoorOpenSwActV : 3|1@0+ (1,0) [0|1] ""  V2V_LS,CGM_LS,ARB_LS,BCM_LS,SCL_LS
 SG_ PsDoorOpenSwAct : 2|1@0+ (1,0) [0|1] ""  V2V_LS,CGM_LS,ARB_LS,SCL_LS,BCM_LS
 SG_ DrDoorOpenSwActV : 1|1@0+ (1,0) [0|1] ""  V2V_LS,FCM_LS,EOCM_F_LS,CGM_LS,ARB_LS,SCL_LS,BCM_LS
 SG_ DrDoorOpenSwAct : 0|1@0+ (1,0) [0|1] ""  V2V_LS,FCM_LS,EOCM_F_LS,CGM_LS,ARB_LS,SCL_LS,BCM_LS

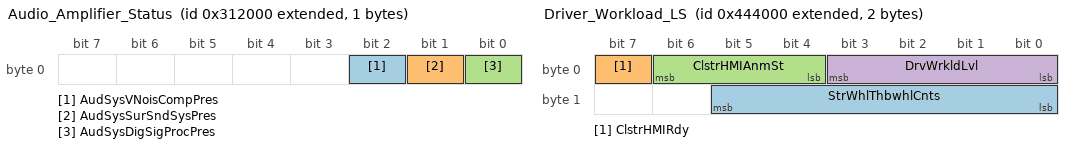
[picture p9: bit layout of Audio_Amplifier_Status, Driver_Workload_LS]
BO_ 2150703104 Audio_Amplifier_Status: 1 AMP_LS
 SG_ AudSysVNoisCompPres : 2|1@0+ (1,0) [0|1] ""  CGM_LS,RadioHead_LS
 SG_ AudSysSurSndSysPres : 1|1@0+ (1,0) [0|1] ""  CGM_LS,RadioHead_LS
 SG_ AudSysDigSigProcPres : 0|1@0+ (1,0) [0|1] ""  CGM_LS,RadioHead_LS

BO_ 2151399424 Wash_Level_LS: 1 IPC_LS
 SG_ VhlFlRngLwIO : 1|1@0+ (1,0) [0|1] "" Vector__XXX
 SG_ WshFldLw : 0|1@0+ (1,0) [0|1] ""  TCP_LS,RadioHead_LS,ONSTAR_LS,BCM_LS

BO_ 2151956480 Driver_Workload_LS: 2 IPC_LS
 SG_ StrWhlThbwhlCnts : 13|6@0- (1,0) [-32|31] "counts"  CGM_LS,RadioHead_LS
 SG_ ClstrHMIRdy : 7|1@0+ (1,0) [0|1] ""  CGM_LS
 SG_ ClstrHMIAnmSt : 6|3@0+ (1,0) [0|7] ""  CGM_LS
 SG_ DrvWrkldLvl : 3|4@0+ (1,0) [0|15] ""  CGM_LS,RadioHead_LS,CHUD_LS,HUD_LS

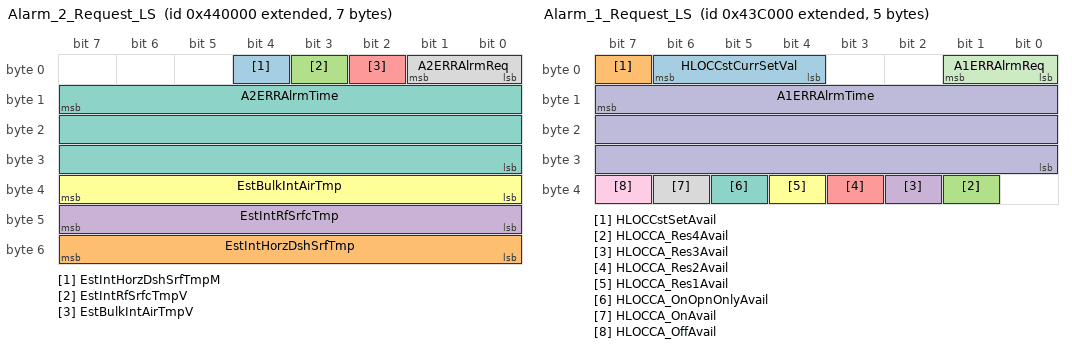
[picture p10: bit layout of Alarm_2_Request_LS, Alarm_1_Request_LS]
BO_ 2151940096 Alarm_2_Request_LS: 7 ECC_LS
 SG_ EstIntHorzDshSrfTmpM : 4|1@0+ (1,0) [0|1] ""  CGM_LS,BCM_LS
 SG_ EstIntHorzDshSrfTmp : 55|8@0+ (1,-40) [-40|215] "deg C"  CGM_LS,BCM_LS
 SG_ EstIntRfSrfcTmpV : 3|1@0+ (1,0) [0|1] ""  CGM_LS,CSM_LS,RadioHead_LS
 SG_ EstIntRfSrfcTmp : 47|8@0+ (0.5,-40) [-40|87.5] "deg C"  CGM_LS,CSM_LS,RadioHead_LS
 SG_ EstBulkIntAirTmpV : 2|1@0+ (1,0) [0|1] ""  CGM_LS,CSM_LS,RadioHead_LS
 SG_ EstBulkIntAirTmp : 39|8@0+ (0.5,-40) [-40|87.5] "deg C"  CGM_LS,CSM_LS,RadioHead_LS
 SG_ A2ERRAlrmTime : 15|24@0+ (1,0) [0|16777215] "min"  CGM_LS,BCM_LS
 SG_ A2ERRAlrmReq : 1|2@0+ (1,0) [0|3] ""  CGM_LS,BCM_LS

BO_ 2151923712 Alarm_1_Request_LS: 5 PTM_LS
 SG_ HLOCCstCurrSetVal : 6|3@0+ (1,0) [0|7] ""  PEPS_LS,CSM_LS,RadioHead_LS,CGM_LS
 SG_ HLOCCstSetAvail : 7|1@0+ (1,0) [0|1] ""  CSM_LS,RadioHead_LS,CGM_LS
 SG_ HLOCCA_Res4Avail : 33|1@0+ (1,0) [0|1] ""  CSM_LS,RadioHead_LS,CGM_LS
 SG_ HLOCCA_Res3Avail : 34|1@0+ (1,0) [0|1] ""  CSM_LS,RadioHead_LS,CGM_LS
 SG_ HLOCCA_Res2Avail : 35|1@0+ (1,0) [0|1] ""  CSM_LS,RadioHead_LS,CGM_LS
 SG_ HLOCCA_Res1Avail : 36|1@0+ (1,0) [0|1] ""  CSM_LS,RadioHead_LS,CGM_LS
 SG_ HLOCCA_OnOpnOnlyAvail : 37|1@0+ (1,0) [0|1] ""  CSM_LS,RadioHead_LS,CGM_LS
 SG_ HLOCCA_OnAvail : 38|1@0+ (1,0) [0|1] ""  CSM_LS,RadioHead_LS,CGM_LS
 SG_ HLOCCA_OffAvail : 39|1@0+ (1,0) [0|1] ""  CSM_LS,RadioHead_LS,CGM_LS
 SG_ A1ERRAlrmTime : 15|24@0+ (1,0) [0|16777215] "min"  CGM_LS,BCM_LS
 SG_ A1ERRAlrmReq : 1|2@0+ (1,0) [0|3] ""  CGM_LS,BCM_LS

BO_ 2150645760 Environment_Id_Resp_1_LS: 3 SDM_LS
 SG_ EnvIdRspSt1 : 17|2@0+ (1,0) [0|3] ""  CGM_LS,BCM_LS
 SG_ EnvIdRsp1 : 7|16@0+ (1,0) [0|65535] ""  CGM_LS,BCM_LS

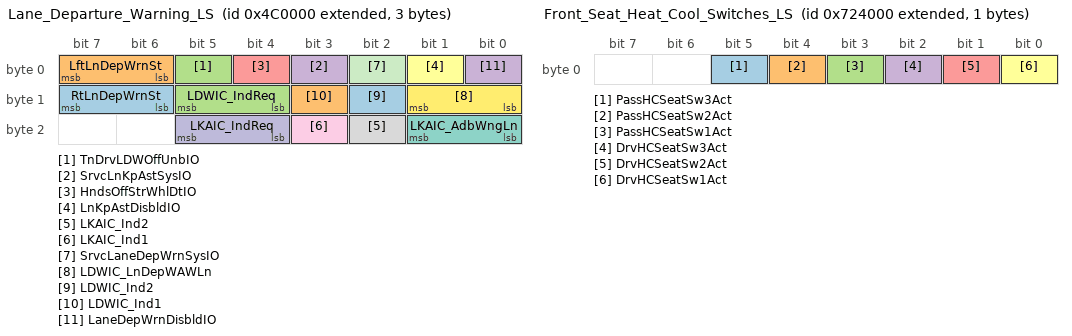
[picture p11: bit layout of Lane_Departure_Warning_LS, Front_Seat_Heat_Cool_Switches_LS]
BO_ 2152464384 Lane_Departure_Warning_LS: 3 FCM_LS
 SG_ RtLnDepWrnSt : 15|2@0+ (1,0) [0|3] ""  CSM_LS,RadioHead_LS,CGM_LS,IPC_LS
 SG_ LftLnDepWrnSt : 7|2@0+ (1,0) [0|3] ""  CSM_LS,RadioHead_LS,CGM_LS,IPC_LS
 SG_ TnDrvLDWOffUnbIO : 5|1@0+ (1,0) [0|1] ""  CGM_LS,IPC_LS
 SG_ SrvcLnKpAstSysIO : 3|1@0+ (1,0) [0|1] ""  CGM_LS,BCM_LS,IPC_LS
 SG_ HndsOffStrWhlDtIO : 4|1@0+ (1,0) [0|1] ""  CGM_LS,IPC_LS
 SG_ LnKpAstDisbldIO : 1|1@0+ (1,0) [0|1] ""  CGM_LS,IPC_LS
 SG_ LKAIC_AdbWngLn : 17|2@0+ (1,0) [0|3] ""  CSM_LS,RadioHead_LS,CGM_LS,BCM_LS,IPC_LS
 SG_ LKAIC_Ind2 : 18|1@0+ (1,0) [0|1] ""  CSM_LS,RadioHead_LS,CGM_LS,BCM_LS,IPC_LS
 SG_ LKAIC_Ind1 : 19|1@0+ (1,0) [0|1] ""  CSM_LS,RadioHead_LS,CGM_LS,BCM_LS,IPC_LS
 SG_ LKAIC_IndReq : 21|2@0+ (1,0) [0|3] ""  CSM_LS,RadioHead_LS,CGM_LS,BCM_LS,IPC_LS
 SG_ SrvcLaneDepWrnSysIO : 2|1@0+ (1,0) [0|1] ""  CGM_LS,BCM_LS,IPC_LS
 SG_ LDWIC_LnDepWAWLn : 9|2@0+ (1,0) [0|3] ""  CSM_LS,RadioHead_LS,CGM_LS,BCM_LS,IPC_LS
 SG_ LDWIC_Ind2 : 10|1@0+ (1,0) [0|1] ""  CSM_LS,RadioHead_LS,CGM_LS,BCM_LS,IPC_LS
 SG_ LDWIC_Ind1 : 11|1@0+ (1,0) [0|1] ""  CSM_LS,RadioHead_LS,CGM_LS,BCM_LS,IPC_LS
 SG_ LDWIC_IndReq : 13|2@0+ (1,0) [0|3] ""  CSM_LS,RadioHead_LS,CGM_LS,BCM_LS,IPC_LS
 SG_ LaneDepWrnDisbldIO : 0|1@0+ (1,0) [0|1] ""  CGM_LS,IPC_LS

BO_ 2154971136 Front_Seat_Heat_Cool_Switches_LS: 1 ECC_LS
 SG_ PassHCSeatSw3Act : 5|1@0+ (1,0) [0|1] ""  BCM_LS,MSM_P_LS,HVSM_F_LS,MSM_LS
 SG_ PassHCSeatSw2Act : 4|1@0+ (1,0) [0|1] ""  BCM_LS,MSM_P_LS,HVSM_F_LS,MSM_LS
 SG_ PassHCSeatSw1Act : 3|1@0+ (1,0) [0|1] ""  BCM_LS,MSM_P_LS,HVSM_F_LS,MSM_LS
 SG_ DrvHCSeatSw3Act : 2|1@0+ (1,0) [0|1] ""  BCM_LS,MSM_P_LS,HVSM_F_LS,MSM_LS
 SG_ DrvHCSeatSw2Act : 1|1@0+ (1,0) [0|1] ""  BCM_LS,MSM_P_LS,HVSM_F_LS,MSM_LS
 SG_ DrvHCSeatSw1Act : 0|1@0+ (1,0) [0|1] ""  BCM_LS,MSM_P_LS,HVSM_F_LS,MSM_LS

BO_ 2154962944 Front_Seat_Heat_Cool_Control_LS: 4 MSM_LS
 SG_ PassHCSMInd3 : 8|1@0+ (1,0) [0|1] ""  CSM_LS,ONSTAR_LS,CGM_LS,ICS_LS,ECC_LS
 SG_ PassHCSMInd2 : 9|1@0+ (1,0) [0|1] ""  CSM_LS,ONSTAR_LS,CGM_LS,ICS_LS,ECC_LS
 SG_ PassHCSMInd1 : 10|1@0+ (1,0) [0|1] ""  CSM_LS,ONSTAR_LS,CGM_LS,ICS_LS,ECC_LS
 SG_ PassHCSMIndReq : 12|2@0+ (1,0) [0|3] ""  CSM_LS,ONSTAR_LS,CGM_LS,ICS_LS,ECC_LS
 SG_ PassHCSLSeatLev5 : 24|1@0+ (1,0) [0|1] ""  CSM_LS,ONSTAR_LS,CGM_LS,IPC_LS,ICS_LS,ECC_LS
 SG_ PassHCSLSeatLev4 : 25|1@0+ (1,0) [0|1] ""  CSM_LS,ONSTAR_LS,CGM_LS,IPC_LS,ICS_LS,ECC_LS
 SG_ PassHCSLSeatLev3 : 26|1@0+ (1,0) [0|1] ""  CSM_LS,ONSTAR_LS,CGM_LS,IPC_LS,ICS_LS,ECC_LS
 SG_ PassHCSLSeatLev2 : 27|1@0+ (1,0) [0|1] ""  CSM_LS,ONSTAR_LS,CGM_LS,IPC_LS,ICS_LS,ECC_LS
 SG_ PassHCSLSeatLev1 : 28|1@0+ (1,0) [0|1] ""  CSM_LS,ONSTAR_LS,CGM_LS,IPC_LS,ICS_LS,ECC_LS
 SG_ PassHCSLIndReq : 30|2@0+ (1,0) [0|3] ""  CSM_LS,ONSTAR_LS,CGM_LS,IPC_LS,ICS_LS,ECC_LS
 SG_ DrvHCSMInd1 : 2|1@0+ (1,0) [0|1] ""  CSM_LS,ONSTAR_LS,CGM_LS,ICS_LS,ECC_LS
 SG_ DrvHCSMIndReq : 4|2@0+ (1,0) [0|3] ""  CSM_LS,ONSTAR_LS,CGM_LS,ICS_LS,ECC_LS
 SG_ DrvHCSMInd3 : 0|1@0+ (1,0) [0|1] ""  CSM_LS,ONSTAR_LS,CGM_LS,ICS_LS,ECC_LS
 SG_ DrvHCSMInd2 : 1|1@0+ (1,0) [0|1] ""  CSM_LS,ONSTAR_LS,CGM_LS,ICS_LS,ECC_LS
 SG_ DrvHCSLSeatLev5 : 16|1@0+ (1,0) [0|1] ""  CSM_LS,ONSTAR_LS,CGM_LS,IPC_LS,ICS_LS,ECC_LS
 SG_ DrvHCSLSeatLev4 : 17|1@0+ (1,0) [0|1] ""  CSM_LS,ONSTAR_LS,CGM_LS,IPC_LS,ICS_LS,ECC_LS
 SG_ DrvHCSLSeatLev3 : 18|1@0+ (1,0) [0|1] ""  CSM_LS,ONSTAR_LS,CGM_LS,IPC_LS,ICS_LS,ECC_LS
 SG_ DrvHCSLSeatLev2 : 19|1@0+ (1,0) [0|1] ""  CSM_LS,ONSTAR_LS,CGM_LS,IPC_LS,ICS_LS,ECC_LS
 SG_ DrvHCSLSeatLev1 : 20|1@0+ (1,0) [0|1] ""  CSM_LS,ONSTAR_LS,CGM_LS,IPC_LS,ICS_LS,ECC_LS
 SG_ DrvHCSLIndReq : 22|2@0+ (1,0) [0|3] ""  CSM_LS,ONSTAR_LS,CGM_LS,IPC_LS,ICS_LS,ECC_LS

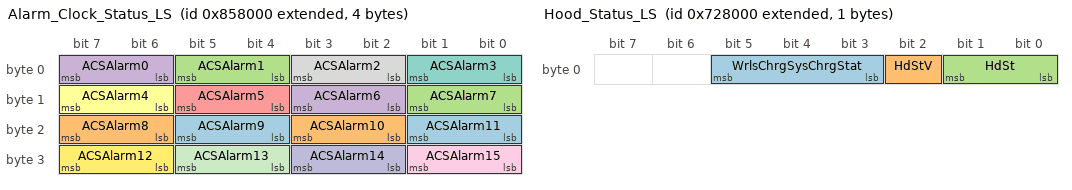
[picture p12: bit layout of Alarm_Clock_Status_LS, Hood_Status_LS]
BO_ 2156232704 Alarm_Clock_Status_LS: 4 BCM_LS
 SG_ ACSAlarm9 : 21|2@0+ (1,0) [0|3] ""  CGM_LS,ECC_LS,LCM_LS,PTM_LS
 SG_ ACSAlarm8 : 23|2@0+ (1,0) [0|3] ""  CGM_LS,ECC_LS,LCM_LS,PTM_LS
 SG_ ACSAlarm7 : 9|2@0+ (1,0) [0|3] ""  CGM_LS,ECC_LS,LCM_LS,PTM_LS
 SG_ ACSAlarm6 : 11|2@0+ (1,0) [0|3] ""  CGM_LS,ECC_LS,LCM_LS,PTM_LS
 SG_ ACSAlarm5 : 13|2@0+ (1,0) [0|3] ""  CGM_LS,ECC_LS,LCM_LS,PTM_LS
 SG_ ACSAlarm4 : 15|2@0+ (1,0) [0|3] ""  CGM_LS,ECC_LS,LCM_LS,PTM_LS
 SG_ ACSAlarm3 : 1|2@0+ (1,0) [0|3] ""  CGM_LS,ECC_LS,LCM_LS,PTM_LS
 SG_ ACSAlarm2 : 3|2@0+ (1,0) [0|3] ""  CGM_LS,ECC_LS,LCM_LS,PTM_LS
 SG_ ACSAlarm15 : 25|2@0+ (1,0) [0|3] ""  CGM_LS,ECC_LS,LCM_LS,PTM_LS
 SG_ ACSAlarm14 : 27|2@0+ (1,0) [0|3] ""  CGM_LS,ECC_LS,LCM_LS,PTM_LS
 SG_ ACSAlarm13 : 29|2@0+ (1,0) [0|3] ""  CGM_LS,ECC_LS,LCM_LS,PTM_LS
 SG_ ACSAlarm12 : 31|2@0+ (1,0) [0|3] ""  CGM_LS,ECC_LS,LCM_LS,PTM_LS
 SG_ ACSAlarm11 : 17|2@0+ (1,0) [0|3] ""  CGM_LS,ECC_LS,LCM_LS,PTM_LS
 SG_ ACSAlarm10 : 19|2@0+ (1,0) [0|3] ""  CGM_LS,ECC_LS,LCM_LS,PTM_LS
 SG_ ACSAlarm1 : 5|2@0+ (1,0) [0|3] ""  CGM_LS,ECC_LS,LCM_LS,PTM_LS
 SG_ ACSAlarm0 : 7|2@0+ (1,0) [0|3] ""  CGM_LS,ECC_LS,LCM_LS,PTM_LS

BO_ 2154987520 Hood_Status_LS: 1 BCM_LS
 SG_ WrlsChrgSysChrgStat : 5|3@0+ (1,0) [0|7] ""  CGM_LS,CSM_LS,RadioHead_LS
 SG_ HdStV : 2|1@0+ (1,0) [0|1] ""  CSM_LS,V2V_LS,CGM_LS,RadioHead_LS,IPC_LS
 SG_ HdSt : 1|2@0+ (1,0) [0|3] ""  VKM_LS,CSM_LS,V2V_LS,CGM_LS,VPM_LS,RadioHead_LS,IPC_LS

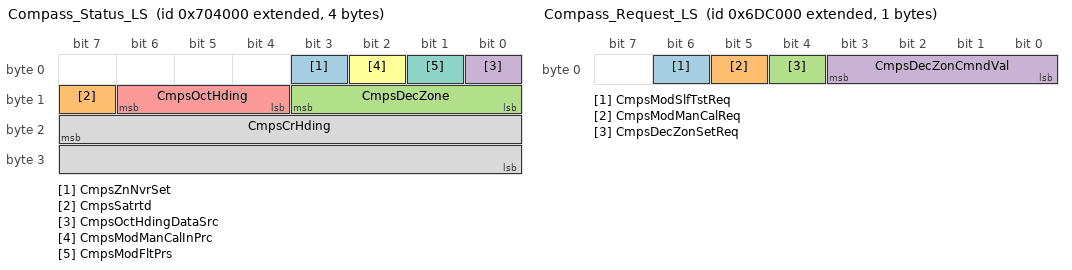
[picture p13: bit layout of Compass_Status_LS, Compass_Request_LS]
BO_ 2154840064 Compass_Status_LS: 4 BCM_LS
 SG_ CmpsZnNvrSet : 3|1@0+ (1,0) [0|1] ""  CGM_LS,ISRVM_LS,RadioHead_LS
 SG_ CmpsSatrtd : 15|1@0+ (1,0) [0|1] ""  CGM_LS,ISRVM_LS,RadioHead_LS
 SG_ CmpsDecZone : 11|4@0+ (1,0) [0|15] ""  CGM_LS,ISRVM_LS,RadioHead_LS
 SG_ CmpsOctHdingDataSrc : 0|1@0+ (1,0) [0|1] ""  CGM_LS,ISRVM_LS,RadioHead_LS
 SG_ CmpsOctHding : 14|3@0+ (1,0) [0|7] ""  CGM_LS,ISRVM_LS,RadioHead_LS
 SG_ CmpsModManCalInPrc : 2|1@0+ (1,0) [0|1] ""  CGM_LS,ISRVM_LS,RadioHead_LS
 SG_ CmpsModFltPrs : 1|1@0+ (1,0) [0|1] ""  CGM_LS,ISRVM_LS,RadioHead_LS
 SG_ CmpsCrHding : 23|16@0+ (0.0054932,0) [0|359.996862] "deg"  CGM_LS,ISRVM_LS,RadioHead_LS

BO_ 2154676224 Compass_Request_LS: 1 IPC_LS
 SG_ CmpsModSlfTstReq : 6|1@0+ (1,0) [0|1] ""  BCM_LS
 SG_ CmpsModManCalReq : 5|1@0+ (1,0) [0|1] ""  BCM_LS
 SG_ CmpsDecZonSetReq : 4|1@0+ (1,0) [0|1] ""  BCM_LS
 SG_ CmpsDecZonCmndVal : 3|4@0+ (1,0) [0|15] ""  BCM_LS

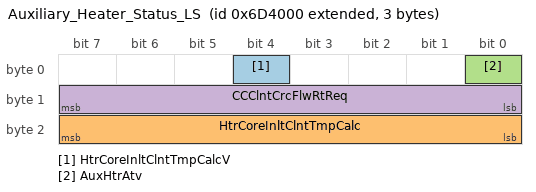
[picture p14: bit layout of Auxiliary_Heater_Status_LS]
BO_ 2154643456 Auxiliary_Heater_Status_LS: 3 ECC_LS
 SG_ HtrCoreInltClntTmpCalcV : 4|1@0+ (1,0) [0|1] ""  CSM_LS,CGM_LS,RadioHead_LS,BSM_LS,VICM_LS
 SG_ HtrCoreInltClntTmpCalc : 23|8@0+ (1,-40) [-40|215] "deg C"  CSM_LS,CGM_LS,RadioHead_LS,BSM_LS,VICM_LS
 SG_ AuxHtrAtv : 0|1@0+ (1,0) [0|1] ""  CSM_LS,CGM_LS,RadioHead_LS,BCM_LS,ECC_LS
 SG_ CCClntCrcFlwRtReq : 15|8@0+ (0.392157,0) [0|100.000035] "%"  CGM_LS,BSM_LS,VICM_LS,BCM_LS

BO_TX_BU_ 2156789760 : CGM_LS,CSM_LS,RadioHead_LS;
BO_TX_BU_ 2155020288 : CSM_LS,RadioHead_LS;
BO_TX_BU_ 2155298816 : CGM_LS,IPC_LS;
BO_TX_BU_ 2158878720 : CSM_LS,CGM_LS,RadioHead_LS;
BO_TX_BU_ 2158870528 : CGM_LS,CHUD_LS,HUD_LS;
BO_TX_BU_ 2154692608 : CGM_LS,TCP_LS,DVB_T_LS,UHP_Low,ONSTAR_LS;
BO_TX_BU_ 2154627072 : CSM_LS,RadioHead_LS;
BO_TX_BU_ 2153938944 : CGM_LS,CSM_LS,RadioHead_LS;
BO_TX_BU_ 2028 : BSM_LS,VICM_LS;
BO_TX_BU_ 2159239168 : TCP_LS,ONSTAR_LS;
BO_TX_BU_ 2159214592 : CSM_LS,RadioHead_LS;
BO_TX_BU_ 2150662144 : CGM_LS,IPC_LS;
BO_TX_BU_ 2155266048 : CGM_LS,BCM_LS,RSC_LS,RSA_LS,ECC_LS;
BO_TX_BU_ 2155249664 : BCM_LS,HVSM_R_LS;
BO_TX_BU_ 2151317504 : EOCM2A_K2_LS,EOCM_F_LS,UPA_LS,APA_LS;
BO_TX_BU_ 2151301120 : UPA_LS,APA_LS;
BO_TX_BU_ 2159083520 : CSM_LS,TCP_LS,RadioHead_LS,UHP_Low,ONSTAR_LS;
BO_TX_BU_ 2151399424 : CGM_LS,IPC_LS;
BO_TX_BU_ 2151923712 : LCM_LS,PTM_LS;
BO_TX_BU_ 2152464384 : EOCM2A_K2_LS,EOCM_F_LS,FCM_LS;
BO_TX_BU_ 2154971136 : CGM_LS,ICS_LS,ECC_LS;
BO_TX_BU_ 2154962944 : BCM_LS,MSM_P_LS,HVSM_F_LS,MSM_LS;
BO_TX_BU_ 2154840064 : TCP_LS,CSM_LS,CGM_LS,ONSTAR_LS,BCM_LS;
BO_TX_BU_ 2154676224 : CGM_LS,IPC_LS;
CM_ BO_ 2158878720 "LAP: Signalerna är inte riktigt kodade!!!        ODI";
CM_ SG_ 2158878720 ODDLC_SubIdReqM "ODI-The number of list entries, starting at the Index, to send";
CM_ SG_ 2158878720 ODDLC_WrpArnd "ODI-Boolean that shall be set to true if the list shall wrap around.";
CM_ SG_ 2158878720 ODDLC_ReqType "ODI - Type of Request";
CM_ SG_ 2158878720 ODDLC_ReqDir "ODI-Boolean that shall be set to true if req down, set to false if set to up";
CM_ SG_ 2158878720 ODDLC_NmEntries "ODI-The number of list entries, starting at the Index, to send";
CM_ SG_ 2158878720 ODDLC_Idx "ODI-The index within the remote FU’s list at which to start sending data";
CM_ SG_ 2158878720 ODDLC_FUCID "ODI - Primary ID of Functional Unit in FU Database";
CM_ SG_ 2158878720 ODDLC_DspMID "ODI - ID that identifies the display requesting the data.  See detailed requirements in ODI GMLAN Protocol.";
CM_ SG_ 2158878720 ODDLC_DataId "ODI-Data Id for the dynamic list";
CM_ SG_ 2158878720 ODDLC_BckgndFlag "ODI-Informs FU as to priority of response.
Applies to all DataIds in the message.
$0=Immediate response required
$1=Background response";
CM_ SG_ 2158870528 ODDLA_SubIdReqM "ODI-The number of list entries, starting at the Index, to send";
CM_ SG_ 2158870528 ODDLA_WrpArnd "ODI-Boolean that shall be set to true if the list shall wrap around.";
CM_ SG_ 2158870528 ODDLA_ReqType "ODI - Type of Request";
CM_ SG_ 2158870528 ODDLA_ReqDir "ODI-Boolean that shall be set to true if req down, set to false if set to up";
CM_ SG_ 2158870528 ODDLA_NmEntries "ODI-The number of list entries, starting at the Index, to send";
CM_ SG_ 2158870528 ODDLA_Idx "ODI-The index within the remote FU’s list at which to start sending data";
CM_ SG_ 2158870528 ODDLA_FUCID "ODI - Primary ID of Functional Unit in FU Database";
CM_ SG_ 2158870528 ODDLA_DspMID "ODI - ID that identifies the display requesting the data.  See detailed requirements in ODI GMLAN Protocol.";
CM_ SG_ 2158870528 ODDLA_DataId "ODI-Data Id for the dynamic list";
CM_ SG_ 2158870528 ODDLA_BckgndFlag "ODI-Informs FU as to priority of response.
Applies to all DataIds in the message.
$0=Immediate response required
$1=Background response";
CM_ SG_ 2151112704 FrPsSeatOccSnsOpMd "TBD";
CM_ SG_ 2151112704 FrPsSeatOccFltSt "TBD";
CM_ SG_ 2158862336 ODIAOT_FUCID "ODI - Primary ID of Functional Unit in FU Database";
CM_ SG_ 2158862336 ODIAOT_DspMID "ODI - ID that identifies the display requesting the data.  See detailed requirements in ODI GMLAN Protocol.";
CM_ SG_ 2158862336 ODIAOT_ActnVal "ODI-Integer value for Actions with values.
FUDatabase definition of Action includes ActionDataType that defines whether or not Action has a value. 
For Actions without a value, this field is always sent as 0.";
CM_ SG_ 2158862336 ODIAOT_ActnID "ODI-ActionId within the FUClass";
CM_ SG_ 2155167744 NRmtDtdPsBrkRstIO "Used to display notification to the driver that they do not have the fob in the vehicle when they pressed the off button.  Gives the driver a chance to obtain the fob before shutting off the car.";
CM_ SG_ 2151317504 PARrRgn4ObjStat "Regions are segments across the width of the vehicle (X coordinate).  Zones are distances from the vehicle (Y coordinate).";
CM_ SG_ 2151317504 PARrRgn3ObjStat "Regions are segments across the width of the vehicle (X coordinate).  Zones are distances from the vehicle (Y coordinate).";
CM_ SG_ 2151317504 PARrRgn2ObjStat "Regions are segments across the width of the vehicle (X coordinate).  Zones are distances from the vehicle (Y coordinate).";
CM_ SG_ 2151317504 PARrRgn1ObjStat "Regions are segments across the width of the vehicle (X coordinate).  Zones are distances from the vehicle (Y coordinate).";
CM_ SG_ 2151301120 PAFrtRgn4ObjStat "Regions are segments across the width of the vehicle (X coordinate).  Zones are distances from the vehicle (Y coordinate).";
CM_ SG_ 2151301120 PAFrtRgn3ObjStat "Regions are segments across the width of the vehicle (X coordinate).  Zones are distances from the vehicle (Y coordinate).";
CM_ SG_ 2151301120 PAFrtRgn2ObjStat "Regions are segments across the width of the vehicle (X coordinate).  Zones are distances from the vehicle (Y coordinate).";
CM_ SG_ 2151301120 PAFrtRgn1ObjStat "Regions are segments across the width of the vehicle (X coordinate).  Zones are distances from the vehicle (Y coordinate).";
CM_ BO_ 2153807872 "LAP: Open Switch ???";
CM_ BO_ 2154987520 "LAP: Är det rätt Tx??? passar i frame0x130??";
CM_ SG_ 2154840064 CmpsCrHding "i.e., adjusted for declination zone, hysterisis, and filtering)";
CM_ SG_ 2154643456 AuxHtrAtv "Auxiliary Heater shall be used to denote a heater function that uses some kind of power, electrical or mechanical,  that was generated by the engine.";
BA_DEF_ SG_  "VNSigPrimaryTriggering" ENUM  "No","Yes","DLCLS","DLCHS","DLCCE","DLCFO";
BA_DEF_ SG_  "VNSigRemoteDiagnostics" ENUM  "No","Yes","DLCLS","DLCHS","DLCCE","DLCFO";
BA_DEF_ SG_  "VNSigInfotainment" ENUM  "No","Yes","DLCLS","DLCHS","DLCCE","DLCFO";
BA_DEF_ SG_  "VNSigParkedVehicle" ENUM  "No","Yes","DLCLS","DLCHS","DLCCE","DLCFO";
BA_DEF_ SG_  "VNSigIntermediate" ENUM  "No","Yes","DLCLS","DLCHS","DLCCE","DLCFO";
BA_DEF_ SG_  "VNSigUnused_4" ENUM  "No","Yes","DLCLS","DLCHS","DLCCE","DLCFO";
BA_DEF_ SG_  "SignalType" STRING ;
BA_DEF_ SG_  "PacketOrder" INT 0 65535;
BA_DEF_ SG_  "SignalLongName" STRING ;
BA_DEF_ SG_  "GenSigStartValue" INT 0 65535;
BA_DEF_ SG_  "VNSigDiagnostic" ENUM  "No","Yes","DLCLS","DLCHS","DLCCE","DLCFO";
BA_DEF_ SG_  "VNSigAllNodes" ENUM  "No","Yes","DLCLS","DLCHS","DLCCE","DLCFO";
BA_DEF_ SG_  "GenSigDeltaValue" INT 0 0;
BA_DEF_ SG_  "GenSigInactiveValue" INT 0 0;
BA_DEF_ SG_  "GenSigSendType" ENUM  "not used","not used","not used","not used","not used","not used","not used","NoSigSendType","not used","not used","OnAnyChange","OnChangeIfActive","OnDelta","DLCLS","DLCHS","DLCCE","DLCFO";
BA_DEF_ SG_  "GenSigSendOnInit" ENUM  "Not Initialized","Application","Handler","DLCLS","DLCHS","DLCCE","DLCFO";
BA_DEF_ BO_  "AppGenMsgCycleTime" INT 0 0;
BA_DEF_ BO_  "TpTxIndex" INT 0 99;
BA_DEF_ BO_  "GenMsgILSupport" ENUM  "No","Yes","DLCLS","DLCHS","DLCCE","DLCFO";
BA_DEF_ BO_  "TpApplType" STRING ;
BA_DEF_ BO_  "Prio" INT 0 7;
BA_DEF_ BO_  "MessageSubnet" ENUM  "LS","MS","HS","CE","PE","HV","FO","S1","HE","LE","HE2","DLCLS","DLCHS","DLCCE","DLCFO";
BA_DEF_ BO_  "GenMsgMandatoryToSupervision" ENUM  "No","Yes","DLCLS","DLCHS","DLCCE","DLCFO";
BA_DEF_ BO_  "DiagState" ENUM  "No","Yes","DLCLS","DLCHS","DLCCE","DLCFO";
BA_DEF_ BO_  "GenMsgStartDelayTime" INT 0 100000;
BA_DEF_ BO_  "GenMsgDelayTime" INT 0 100000;
BA_DEF_ BO_  "GenMsgCycleTime" INT 0 100000;
BA_DEF_ BO_  "GenMsgSendType" ENUM  "cyclicX","spontanX","cyclicIfActiveX","spontanWithDelay","cyclicAndSpontanX","cyclicAndSpontanWithDelay","spontanWithRepitition","cyclicIfActiveAndSpontanWD","DLCLS","DLCHS","DLCCE","DLCFO";
BA_DEF_ BO_  "DiagResponse" ENUM  "No","Yes","DLCLS","DLCHS","DLCCE","DLCFO";
BA_DEF_ BO_  "DiagRequest" ENUM  "No","Yes","DLCLS","DLCHS","DLCCE","DLCFO";
BA_DEF_ BO_  "NmMessage" ENUM  "No","Yes","DLCLS","DLCHS","DLCCE","DLCFO";
BA_DEF_REL_ BU_SG_REL_  "GenSigSuprvRespComment" STRING ;
BA_DEF_REL_ BU_SG_REL_  "GenSigVBitResp" ENUM  "No","Yes","DLCLS","DLCHS","DLCCE","DLCFO";
BA_DEF_REL_ BU_SG_REL_  "GenSigVBitRespComment" STRING ;
BA_DEF_REL_ BU_SG_REL_  "GenSigVDAFailComment" STRING ;
BA_DEF_REL_ BU_SG_REL_  "GenSigVDAFailResp" ENUM  "No","Yes","DLCLS","DLCHS","DLCCE","DLCFO";
BA_DEF_REL_ BU_SG_REL_  "GenSigRxStartValue" STRING ;
BA_DEF_REL_ BU_SG_REL_  "GenSigSuprvRespSubValue" INT 0 65535;
BA_DEF_REL_ BU_SG_REL_  "GenSigSuprvResp" ENUM  "None","Notify App","Substitute Default","DLCLS","DLCHS","DLCCE","DLCFO";
BA_DEF_REL_ BU_SG_REL_  "GenSigTimeoutMsg" HEX -2147483648 268435455;
BA_DEF_REL_ BU_SG_REL_  "GenSigTimeoutTime" INT 0 15000;
BA_DEF_DEF_  "VNSigPrimaryTriggering" "No";
BA_DEF_DEF_  "VNSigRemoteDiagnostics" "No";
BA_DEF_DEF_  "VNSigInfotainment" "No";
BA_DEF_DEF_  "VNSigParkedVehicle" "No";
BA_DEF_DEF_  "VNSigIntermediate" "No";
BA_DEF_DEF_  "VNSigUnused_4" "No";
BA_DEF_DEF_  "SignalType" "";
BA_DEF_DEF_  "PacketOrder" 0;
BA_DEF_DEF_  "SignalLongName" "";
BA_DEF_DEF_  "GenSigStartValue" 0;
BA_DEF_DEF_  "VNSigDiagnostic" "No";
BA_DEF_DEF_  "VNSigAllNodes" "No";
BA_DEF_DEF_  "GenSigDeltaValue" 0;
BA_DEF_DEF_  "GenSigInactiveValue" 0;
BA_DEF_DEF_  "GenSigSendType" "NoSigSendType";
BA_DEF_DEF_  "GenSigSendOnInit" "Not Initialized";
BA_DEF_DEF_  "AppGenMsgCycleTime" 0;
BA_DEF_DEF_  "TpTxIndex" 0;
BA_DEF_DEF_  "GenMsgILSupport" "Yes";
BA_DEF_DEF_  "TpApplType" "";
BA_DEF_DEF_  "Prio" 4;
BA_DEF_DEF_  "MessageSubnet" "FO";
BA_DEF_DEF_  "GenMsgMandatoryToSupervision" "No";
BA_DEF_DEF_  "DiagState" "No";
BA_DEF_DEF_  "GenMsgStartDelayTime" 0;
BA_DEF_DEF_  "GenMsgDelayTime" 0;
BA_DEF_DEF_  "GenMsgCycleTime" 0;
BA_DEF_DEF_  "GenMsgSendType" "spontanX";
BA_DEF_DEF_  "DiagResponse" "No";
BA_DEF_DEF_  "DiagRequest" "No";
BA_DEF_DEF_  "NmMessage" "No";
BA_DEF_DEF_REL_ "GenSigSuprvRespComment" "";
BA_DEF_DEF_REL_ "GenSigVBitResp" "No";
BA_DEF_DEF_REL_ "GenSigVBitRespComment" "";
BA_DEF_DEF_REL_ "GenSigVDAFailComment" "";
BA_DEF_DEF_REL_ "GenSigVDAFailResp" "No";
BA_DEF_DEF_REL_ "GenSigRxStartValue" "";
BA_DEF_DEF_REL_ "GenSigSuprvRespSubValue" 0;
BA_DEF_DEF_REL_ "GenSigSuprvResp" "None";
BA_DEF_DEF_REL_ "GenSigTimeoutMsg" 0;
BA_DEF_DEF_REL_ "GenSigTimeoutTime" 0;
BA_ "MessageSubnet" BO_ 2156789760 0;
BA_ "GenMsgDelayTime" BO_ 2156789760 100;
BA_ "MessageSubnet" BO_ 2155020288 0;
BA_ "GenMsgDelayTime" BO_ 2155020288 100;
BA_ "MessageSubnet" BO_ 2150432768 0;
BA_ "GenMsgStartDelayTime" BO_ 2150432768 150;
BA_ "GenMsgCycleTime" BO_ 2150432768 500;
BA_ "GenMsgSendType" BO_ 2150432768 0;
BA_ "MessageSubnet" BO_ 2155298816 0;
BA_ "GenMsgDelayTime" BO_ 2155298816 100;
BA_ "MessageSubnet" BO_ 2158878720 0;
BA_ "GenMsgDelayTime" BO_ 2158878720 20;
BA_ "MessageSubnet" BO_ 2158870528 0;
BA_ "GenMsgDelayTime" BO_ 2158870528 20;
BA_ "MessageSubnet" BO_ 2154692608 0;
BA_ "GenMsgDelayTime" BO_ 2154692608 10;
BA_ "GenMsgCycleTime" BO_ 2154692608 1200;
BA_ "GenMsgSendType" BO_ 2154692608 0;
BA_ "MessageSubnet" BO_ 2154627072 0;
BA_ "GenMsgDelayTime" BO_ 2154627072 100;
BA_ "GenMsgCycleTime" BO_ 2154627072 1200;
BA_ "GenMsgSendType" BO_ 2154627072 0;
BA_ "MessageSubnet" BO_ 2151112704 0;
BA_ "GenMsgDelayTime" BO_ 2151112704 100;
BA_ "MessageSubnet" BO_ 2153938944 0;
BA_ "GenMsgDelayTime" BO_ 2153938944 100;
BA_ "Prio" BO_ 2028 0;
BA_ "MessageSubnet" BO_ 2028 0;
BA_ "DiagResponse" BO_ 2028 1;
BA_ "MessageSubnet" BO_ 2159239168 0;
BA_ "GenMsgDelayTime" BO_ 2159239168 10;
BA_ "MessageSubnet" BO_ 2159230976 0;
BA_ "GenMsgDelayTime" BO_ 2159230976 10;
BA_ "MessageSubnet" BO_ 2159222784 0;
BA_ "GenMsgDelayTime" BO_ 2159222784 10;
BA_ "MessageSubnet" BO_ 2159214592 0;
BA_ "GenMsgDelayTime" BO_ 2159214592 10;
BA_ "MessageSubnet" BO_ 2158862336 0;
BA_ "GenMsgDelayTime" BO_ 2158862336 20;
BA_ "MessageSubnet" BO_ 2150662144 0;
BA_ "GenMsgDelayTime" BO_ 2150662144 100;
BA_ "MessageSubnet" BO_ 2150653952 0;
BA_ "GenMsgDelayTime" BO_ 2150653952 100;
BA_ "MessageSubnet" BO_ 2150850560 0;
BA_ "GenMsgDelayTime" BO_ 2150850560 100;
BA_ "MessageSubnet" BO_ 2154659840 0;
BA_ "GenMsgDelayTime" BO_ 2154659840 100;
BA_ "MessageSubnet" BO_ 2154938368 0;
BA_ "GenMsgDelayTime" BO_ 2154938368 100;
BA_ "MessageSubnet" BO_ 2155266048 0;
BA_ "GenMsgDelayTime" BO_ 2155266048 100;
BA_ "MessageSubnet" BO_ 2155249664 0;
BA_ "GenMsgDelayTime" BO_ 2155249664 100;
BA_ "MessageSubnet" BO_ 2155184128 0;
BA_ "GenMsgDelayTime" BO_ 2155184128 100;
BA_ "MessageSubnet" BO_ 2155167744 0;
BA_ "GenMsgDelayTime" BO_ 2155167744 100;
BA_ "Prio" BO_ 2154921984 3;
BA_ "MessageSubnet" BO_ 2154921984 0;
BA_ "GenMsgDelayTime" BO_ 2154921984 100;
BA_ "MessageSubnet" BO_ 2151317504 0;
BA_ "GenMsgDelayTime" BO_ 2151317504 100;
BA_ "MessageSubnet" BO_ 2151301120 0;
BA_ "GenMsgDelayTime" BO_ 2151301120 100;
BA_ "MessageSubnet" BO_ 2159083520 0;
BA_ "GenMsgDelayTime" BO_ 2159083520 10;
BA_ "MessageSubnet" BO_ 2153922560 0;
BA_ "GenMsgDelayTime" BO_ 2153922560 100;
BA_ "Prio" BO_ 2153807872 3;
BA_ "MessageSubnet" BO_ 2153807872 0;
BA_ "GenMsgDelayTime" BO_ 2153807872 100;
BA_ "MessageSubnet" BO_ 2150703104 0;
BA_ "GenMsgDelayTime" BO_ 2150703104 100;
BA_ "MessageSubnet" BO_ 2151399424 0;
BA_ "GenMsgDelayTime" BO_ 2151399424 100;
BA_ "MessageSubnet" BO_ 2151956480 0;
BA_ "GenMsgDelayTime" BO_ 2151956480 20;
BA_ "MessageSubnet" BO_ 2151940096 0;
BA_ "GenMsgDelayTime" BO_ 2151940096 100;
BA_ "MessageSubnet" BO_ 2151923712 0;
BA_ "GenMsgDelayTime" BO_ 2151923712 100;
BA_ "MessageSubnet" BO_ 2150645760 0;
BA_ "GenMsgDelayTime" BO_ 2150645760 100;
BA_ "MessageSubnet" BO_ 2152464384 0;
BA_ "GenMsgDelayTime" BO_ 2152464384 100;
BA_ "MessageSubnet" BO_ 2154971136 0;
BA_ "GenMsgDelayTime" BO_ 2154971136 100;
BA_ "MessageSubnet" BO_ 2154962944 0;
BA_ "GenMsgDelayTime" BO_ 2154962944 100;
BA_ "MessageSubnet" BO_ 2156232704 0;
BA_ "GenMsgDelayTime" BO_ 2156232704 100;
BA_ "MessageSubnet" BO_ 2154987520 0;
BA_ "GenMsgDelayTime" BO_ 2154987520 100;
BA_ "MessageSubnet" BO_ 2154840064 0;
BA_ "GenMsgDelayTime" BO_ 2154840064 100;
BA_ "MessageSubnet" BO_ 2154676224 0;
BA_ "GenMsgDelayTime" BO_ 2154676224 100;
BA_ "MessageSubnet" BO_ 2154643456 0;
BA_ "GenMsgDelayTime" BO_ 2154643456 100;
BA_ "GenSigSendType" SG_ 2156789760 FrPedDetCsStReq 10;
BA_ "SignalType" SG_ 2156789760 FrPedDetCsStReq "ENM";
BA_ "SignalLongName" SG_ 2156789760 FrPedDetCsStReq "Front Pedestrian Detection Customization Setting Request";
BA_ "VNSigAllNodes" SG_ 2156789760 FrPedDetCsStReq 1;
BA_ "GenSigSendType" SG_ 2156789760 SurdVwLightgCsSetReq 10;
BA_ "SignalType" SG_ 2156789760 SurdVwLightgCsSetReq "ENM";
BA_ "SignalLongName" SG_ 2156789760 SurdVwLightgCsSetReq "Surround View Lighting Customization Setting Request";
BA_ "VNSigAllNodes" SG_ 2156789760 SurdVwLightgCsSetReq 1;
BA_ "GenSigSendType" SG_ 2156789760 SmrtHgBmAstCstSetReq 10;
BA_ "SignalType" SG_ 2156789760 SmrtHgBmAstCstSetReq "ENM";
BA_ "SignalLongName" SG_ 2156789760 SmrtHgBmAstCstSetReq "Smart High Beam Assist Customization Setting Request";
BA_ "VNSigAllNodes" SG_ 2156789760 SmrtHgBmAstCstSetReq 1;
BA_ "GenSigSendType" SG_ 2156789760 TimeDispFormat 10;
BA_ "GenSigSendOnInit" SG_ 2156789760 TimeDispFormat 1;
BA_ "VNSigInfotainment" SG_ 2156789760 TimeDispFormat 1;
BA_ "SignalType" SG_ 2156789760 TimeDispFormat "ENM";
BA_ "SignalLongName" SG_ 2156789760 TimeDispFormat "Time Display Format";
BA_ "VNSigAllNodes" SG_ 2156789760 TimeDispFormat 1;
BA_ "GenSigDeltaValue" SG_ 2156789760 CldrYr 1;
BA_ "GenSigSendType" SG_ 2156789760 CldrYr 12;
BA_ "GenSigSendOnInit" SG_ 2156789760 CldrYr 1;
BA_ "VNSigInfotainment" SG_ 2156789760 CldrYr 1;
BA_ "SignalType" SG_ 2156789760 CldrYr "UNM";
BA_ "SignalLongName" SG_ 2156789760 CldrYr "Calendar Year";
BA_ "VNSigAllNodes" SG_ 2156789760 CldrYr 1;
BA_ "GenSigSendType" SG_ 2156789760 CldrMth 10;
BA_ "GenSigSendOnInit" SG_ 2156789760 CldrMth 1;
BA_ "VNSigInfotainment" SG_ 2156789760 CldrMth 1;
BA_ "SignalType" SG_ 2156789760 CldrMth "ENM";
BA_ "SignalLongName" SG_ 2156789760 CldrMth "Calendar Month";
BA_ "VNSigAllNodes" SG_ 2156789760 CldrMth 1;
BA_ "GenSigDeltaValue" SG_ 2156789760 CldrDay 1;
BA_ "GenSigSendType" SG_ 2156789760 CldrDay 12;
BA_ "GenSigSendOnInit" SG_ 2156789760 CldrDay 1;
BA_ "VNSigInfotainment" SG_ 2156789760 CldrDay 1;
BA_ "SignalType" SG_ 2156789760 CldrDay "UNM";
BA_ "SignalLongName" SG_ 2156789760 CldrDay "Calendar Day";
BA_ "VNSigAllNodes" SG_ 2156789760 CldrDay 1;
BA_ "GenSigDeltaValue" SG_ 2156789760 TOD_SecofMin 1;
BA_ "GenSigSendType" SG_ 2156789760 TOD_SecofMin 12;
BA_ "GenSigSendOnInit" SG_ 2156789760 TOD_SecofMin 1;
BA_ "VNSigInfotainment" SG_ 2156789760 TOD_SecofMin 1;
BA_ "SignalType" SG_ 2156789760 TOD_SecofMin "UNM";
BA_ "PacketOrder" SG_ 2156789760 TOD_SecofMin 3;
BA_ "SignalLongName" SG_ 2156789760 TOD_SecofMin "Time of Day : Seconds of Minute";
BA_ "VNSigAllNodes" SG_ 2156789760 TOD_SecofMin 1;
BA_ "GenSigDeltaValue" SG_ 2156789760 TOD_MinofHr 1;
BA_ "GenSigSendType" SG_ 2156789760 TOD_MinofHr 12;
BA_ "GenSigSendOnInit" SG_ 2156789760 TOD_MinofHr 1;
BA_ "VNSigInfotainment" SG_ 2156789760 TOD_MinofHr 1;
BA_ "SignalType" SG_ 2156789760 TOD_MinofHr "UNM";
BA_ "PacketOrder" SG_ 2156789760 TOD_MinofHr 2;
BA_ "SignalLongName" SG_ 2156789760 TOD_MinofHr "Time of Day : Minute of Hour";
BA_ "VNSigAllNodes" SG_ 2156789760 TOD_MinofHr 1;
BA_ "GenSigDeltaValue" SG_ 2156789760 TOD_HrofDay 1;
BA_ "GenSigSendType" SG_ 2156789760 TOD_HrofDay 12;
BA_ "GenSigSendOnInit" SG_ 2156789760 TOD_HrofDay 1;
BA_ "VNSigInfotainment" SG_ 2156789760 TOD_HrofDay 1;
BA_ "SignalType" SG_ 2156789760 TOD_HrofDay "UNM";
BA_ "PacketOrder" SG_ 2156789760 TOD_HrofDay 1;
BA_ "SignalLongName" SG_ 2156789760 TOD_HrofDay "Time of Day : Hour of Day";
BA_ "VNSigAllNodes" SG_ 2156789760 TOD_HrofDay 1;
BA_ "GenSigSendType" SG_ 2155020288 ChVolRq2 10;
BA_ "SignalType" SG_ 2155020288 ChVolRq2 "ENM";
BA_ "SignalLongName" SG_ 2155020288 ChVolRq2 "Chime Volume Request 2";
BA_ "VNSigAllNodes" SG_ 2155020288 ChVolRq2 1;
BA_ "GenSigSendType" SG_ 2155020288 LngSelExt 10;
BA_ "GenSigSendOnInit" SG_ 2155020288 LngSelExt 1;
BA_ "VNSigInfotainment" SG_ 2155020288 LngSelExt 1;
BA_ "SignalType" SG_ 2155020288 LngSelExt "ENM";
BA_ "SignalLongName" SG_ 2155020288 LngSelExt "Language Selection Extended";
BA_ "VNSigAllNodes" SG_ 2155020288 LngSelExt 1;
BA_ "SignalType" SG_ 2150432768 CbnHtrWrmUpIO "BLN";
BA_ "SignalLongName" SG_ 2150432768 CbnHtrWrmUpIO "Cabin Heater Warm Up Indication On";
BA_ "VNSigAllNodes" SG_ 2150432768 CbnHtrWrmUpIO 1;
BA_ "SignalType" SG_ 2150432768 EngManfldAirTempCrtdV "ENM";
BA_ "SignalLongName" SG_ 2150432768 EngManfldAirTempCrtdV "Engine Manifold Air Temperature Corrected Validity";
BA_ "VNSigAllNodes" SG_ 2150432768 EngManfldAirTempCrtdV 1;
BA_ "SignalType" SG_ 2150432768 GrdBrkgAct "BLN";
BA_ "SignalLongName" SG_ 2150432768 GrdBrkgAct "Grade Braking Active";
BA_ "VNSigAllNodes" SG_ 2150432768 GrdBrkgAct 1;
BA_ "SignalType" SG_ 2150432768 EngManfldAirTempCrtd "UNM";
BA_ "SignalLongName" SG_ 2150432768 EngManfldAirTempCrtd "Engine Manifold Air Temperature Corrected";
BA_ "VNSigAllNodes" SG_ 2150432768 EngManfldAirTempCrtd 1;
BA_ "SignalType" SG_ 2150432768 FuelFltLifRstPerf "BLN";
BA_ "SignalLongName" SG_ 2150432768 FuelFltLifRstPerf "Fuel Filter Life Reset Performed";
BA_ "VNSigAllNodes" SG_ 2150432768 FuelFltLifRstPerf 1;
BA_ "SignalType" SG_ 2150432768 FuelFltRmnLf "UNM";
BA_ "SignalLongName" SG_ 2150432768 FuelFltRmnLf "Fuel Filter Remaining Life";
BA_ "VNSigAllNodes" SG_ 2150432768 FuelFltRmnLf 1;
BA_ "SignalType" SG_ 2150432768 EngShtdwnPndgIO "BLN";
BA_ "SignalLongName" SG_ 2150432768 EngShtdwnPndgIO "Engine Shutdown Pending Indication On";
BA_ "VNSigAllNodes" SG_ 2150432768 EngShtdwnPndgIO 1;
BA_ "SignalType" SG_ 2150432768 GenFldDutCycV "ENM";
BA_ "SignalLongName" SG_ 2150432768 GenFldDutCycV "Generator Field Duty Cycle Validity";
BA_ "VNSigAllNodes" SG_ 2150432768 GenFldDutCycV 1;
BA_ "SignalType" SG_ 2150432768 GenFldDutCyc "UNM";
BA_ "SignalLongName" SG_ 2150432768 GenFldDutCyc "Generator Field Duty Cycle";
BA_ "VNSigAllNodes" SG_ 2150432768 GenFldDutCyc 1;
BA_ "GenSigSendOnInit" SG_ 2150432768 FuelTotCap 1;
BA_ "SignalType" SG_ 2150432768 FuelTotCap "UNM";
BA_ "SignalLongName" SG_ 2150432768 FuelTotCap "Fuel Total Capacity";
BA_ "VNSigAllNodes" SG_ 2150432768 FuelTotCap 1;
BA_ "SignalType" SG_ 2150432768 TransOilTempSensPres "BLN";
BA_ "SignalLongName" SG_ 2150432768 TransOilTempSensPres "Transmission Oil Temperature Sensor Present";
BA_ "VNSigAllNodes" SG_ 2150432768 TransOilTempSensPres 1;
BA_ "SignalType" SG_ 2150432768 TrnsNEmsRltMalfActv "BLN";
BA_ "SignalLongName" SG_ 2150432768 TrnsNEmsRltMalfActv "Transmission Non Emissions Related Malfunction Active";
BA_ "VNSigAllNodes" SG_ 2150432768 TrnsNEmsRltMalfActv 1;
BA_ "SignalType" SG_ 2150432768 TrnEmsMlfAtv "BLN";
BA_ "SignalLongName" SG_ 2150432768 TrnEmsMlfAtv "Transmission Emissions Related Malfunction Active";
BA_ "VNSigAllNodes" SG_ 2150432768 TrnEmsMlfAtv 1;
BA_ "SignalType" SG_ 2150432768 EngOilRmnLf "UNM";
BA_ "SignalLongName" SG_ 2150432768 EngOilRmnLf "Engine Oil Remaining Life";
BA_ "VNSigAllNodes" SG_ 2150432768 EngOilRmnLf 1;
BA_ "SignalType" SG_ 2150432768 TrnsThrmlMngmntStat "ENM";
BA_ "SignalLongName" SG_ 2150432768 TrnsThrmlMngmntStat "Transmission Thermal Management Status";
BA_ "VNSigAllNodes" SG_ 2150432768 TrnsThrmlMngmntStat 1;
BA_ "SignalType" SG_ 2150432768 PTHiElecLdReqd "BLN";
BA_ "SignalLongName" SG_ 2150432768 PTHiElecLdReqd "Powertrain High Electrical Load Requested";
BA_ "VNSigAllNodes" SG_ 2150432768 PTHiElecLdReqd 1;
BA_ "GenSigSendType" SG_ 2155298816 EngAirFltMonDrvrReq 10;
BA_ "SignalType" SG_ 2155298816 EngAirFltMonDrvrReq "ENM";
BA_ "SignalLongName" SG_ 2155298816 EngAirFltMonDrvrReq "Engine Air Filter Monitor Driver Request";
BA_ "VNSigAllNodes" SG_ 2155298816 EngAirFltMonDrvrReq 1;
BA_ "GenSigSendType" SG_ 2155298816 TrPrsMntrTrLdRstRqstd 10;
BA_ "SignalType" SG_ 2155298816 TrPrsMntrTrLdRstRqstd "ENM";
BA_ "SignalLongName" SG_ 2155298816 TrPrsMntrTrLdRstRqstd "Tire Pressure Monitoring Tire Loading Reset Requested";
BA_ "VNSigAllNodes" SG_ 2155298816 TrPrsMntrTrLdRstRqstd 1;
BA_ "GenSigSendType" SG_ 2155298816 TrPrsSnsProgEvntRqd 10;
BA_ "GenSigSendOnInit" SG_ 2155298816 TrPrsSnsProgEvntRqd 2;
BA_ "SignalType" SG_ 2155298816 TrPrsSnsProgEvntRqd "BLN";
BA_ "SignalLongName" SG_ 2155298816 TrPrsSnsProgEvntRqd "Tire Pressure Sensor Programming Event Requested";
BA_ "VNSigAllNodes" SG_ 2155298816 TrPrsSnsProgEvntRqd 1;
BA_ "GenSigDeltaValue" SG_ 2158878720 ODDLC_SubIdReqM 1;
BA_ "GenSigSendType" SG_ 2158878720 ODDLC_SubIdReqM 12;
BA_ "VNSigInfotainment" SG_ 2158878720 ODDLC_SubIdReqM 1;
BA_ "SignalType" SG_ 2158878720 ODDLC_SubIdReqM "UNM";
BA_ "PacketOrder" SG_ 2158878720 ODDLC_SubIdReqM 10;
BA_ "SignalLongName" SG_ 2158878720 ODDLC_SubIdReqM "Open Display Interface Dynamic Data List Request CenterStack : Sub Id Request Mask";
BA_ "VNSigAllNodes" SG_ 2158878720 ODDLC_SubIdReqM 1;
BA_ "GenSigSendType" SG_ 2158878720 ODDLC_WrpArnd 10;
BA_ "VNSigInfotainment" SG_ 2158878720 ODDLC_WrpArnd 1;
BA_ "SignalType" SG_ 2158878720 ODDLC_WrpArnd "BLN";
BA_ "PacketOrder" SG_ 2158878720 ODDLC_WrpArnd 9;
BA_ "SignalLongName" SG_ 2158878720 ODDLC_WrpArnd "Open Display Interface Dynamic Data List Request CenterStack : Wrap Around";
BA_ "VNSigAllNodes" SG_ 2158878720 ODDLC_WrpArnd 1;
BA_ "GenSigSendType" SG_ 2158878720 ODDLC_ReqType 10;
BA_ "VNSigInfotainment" SG_ 2158878720 ODDLC_ReqType 1;
BA_ "SignalType" SG_ 2158878720 ODDLC_ReqType "ENM";
BA_ "PacketOrder" SG_ 2158878720 ODDLC_ReqType 7;
BA_ "SignalLongName" SG_ 2158878720 ODDLC_ReqType "Open Display Interface Dynamic Data List Request CenterStack : Request Type";
BA_ "VNSigAllNodes" SG_ 2158878720 ODDLC_ReqType 1;
BA_ "GenSigSendType" SG_ 2158878720 ODDLC_ReqDir 10;
BA_ "VNSigInfotainment" SG_ 2158878720 ODDLC_ReqDir 1;
BA_ "SignalType" SG_ 2158878720 ODDLC_ReqDir "BLN";
BA_ "PacketOrder" SG_ 2158878720 ODDLC_ReqDir 5;
BA_ "SignalLongName" SG_ 2158878720 ODDLC_ReqDir "Open Display Interface Dynamic Data List Request CenterStack : Req Direction";
BA_ "VNSigAllNodes" SG_ 2158878720 ODDLC_ReqDir 1;
BA_ "GenSigDeltaValue" SG_ 2158878720 ODDLC_NmEntries 1;
BA_ "GenSigSendType" SG_ 2158878720 ODDLC_NmEntries 12;
BA_ "VNSigInfotainment" SG_ 2158878720 ODDLC_NmEntries 1;
BA_ "SignalType" SG_ 2158878720 ODDLC_NmEntries "UNM";
BA_ "PacketOrder" SG_ 2158878720 ODDLC_NmEntries 4;
BA_ "SignalLongName" SG_ 2158878720 ODDLC_NmEntries "Open Display Interface Dynamic Data List Request CenterStack : Num Entries";
BA_ "VNSigAllNodes" SG_ 2158878720 ODDLC_NmEntries 1;
BA_ "GenSigDeltaValue" SG_ 2158878720 ODDLC_Idx 1;
BA_ "GenSigSendType" SG_ 2158878720 ODDLC_Idx 12;
BA_ "VNSigInfotainment" SG_ 2158878720 ODDLC_Idx 1;
BA_ "SignalType" SG_ 2158878720 ODDLC_Idx "UNM";
BA_ "PacketOrder" SG_ 2158878720 ODDLC_Idx 6;
BA_ "SignalLongName" SG_ 2158878720 ODDLC_Idx "Open Display Interface Dynamic Data List Request CenterStack : Index";
BA_ "VNSigAllNodes" SG_ 2158878720 ODDLC_Idx 1;
BA_ "GenSigDeltaValue" SG_ 2158878720 ODDLC_FUCID 1;
BA_ "GenSigSendType" SG_ 2158878720 ODDLC_FUCID 12;
BA_ "VNSigInfotainment" SG_ 2158878720 ODDLC_FUCID 1;
BA_ "SignalType" SG_ 2158878720 ODDLC_FUCID "UNM";
BA_ "PacketOrder" SG_ 2158878720 ODDLC_FUCID 1;
BA_ "SignalLongName" SG_ 2158878720 ODDLC_FUCID "Open Display Interface Dynamic Data List Request CenterStack : Functional Unit Class ID";
BA_ "VNSigAllNodes" SG_ 2158878720 ODDLC_FUCID 1;
BA_ "GenSigSendType" SG_ 2158878720 ODDLC_DspMID 10;
BA_ "VNSigInfotainment" SG_ 2158878720 ODDLC_DspMID 1;
BA_ "SignalType" SG_ 2158878720 ODDLC_DspMID "ENM";
BA_ "PacketOrder" SG_ 2158878720 ODDLC_DspMID 3;
BA_ "SignalLongName" SG_ 2158878720 ODDLC_DspMID "Open Display Interface Dynamic Data List Request CenterStack : Display Mask Id";
BA_ "VNSigAllNodes" SG_ 2158878720 ODDLC_DspMID 1;
BA_ "GenSigDeltaValue" SG_ 2158878720 ODDLC_DataId 1;
BA_ "GenSigSendType" SG_ 2158878720 ODDLC_DataId 12;
BA_ "VNSigInfotainment" SG_ 2158878720 ODDLC_DataId 1;
BA_ "SignalType" SG_ 2158878720 ODDLC_DataId "UNM";
BA_ "PacketOrder" SG_ 2158878720 ODDLC_DataId 2;
BA_ "SignalLongName" SG_ 2158878720 ODDLC_DataId "Open Display Interface Dynamic Data List Request CenterStack : Data Id";
BA_ "VNSigAllNodes" SG_ 2158878720 ODDLC_DataId 1;
BA_ "GenSigSendType" SG_ 2158878720 ODDLC_BckgndFlag 10;
BA_ "VNSigInfotainment" SG_ 2158878720 ODDLC_BckgndFlag 1;
BA_ "SignalType" SG_ 2158878720 ODDLC_BckgndFlag "ENM";
BA_ "PacketOrder" SG_ 2158878720 ODDLC_BckgndFlag 8;
BA_ "SignalLongName" SG_ 2158878720 ODDLC_BckgndFlag "Open Display Interface Dynamic Data List Request CenterStack : Background Flag";
BA_ "VNSigAllNodes" SG_ 2158878720 ODDLC_BckgndFlag 1;
BA_ "GenSigDeltaValue" SG_ 2158870528 ODDLA_SubIdReqM 1;
BA_ "GenSigSendType" SG_ 2158870528 ODDLA_SubIdReqM 12;
BA_ "VNSigInfotainment" SG_ 2158870528 ODDLA_SubIdReqM 1;
BA_ "SignalType" SG_ 2158870528 ODDLA_SubIdReqM "UNM";
BA_ "PacketOrder" SG_ 2158870528 ODDLA_SubIdReqM 10;
BA_ "SignalLongName" SG_ 2158870528 ODDLA_SubIdReqM "Open Display Interface Dynamic Data List Request Auxiliary IP : Sub Id Request Mask";
BA_ "VNSigAllNodes" SG_ 2158870528 ODDLA_SubIdReqM 1;
BA_ "GenSigSendType" SG_ 2158870528 ODDLA_WrpArnd 10;
BA_ "VNSigInfotainment" SG_ 2158870528 ODDLA_WrpArnd 1;
BA_ "SignalType" SG_ 2158870528 ODDLA_WrpArnd "BLN";
BA_ "PacketOrder" SG_ 2158870528 ODDLA_WrpArnd 9;
BA_ "SignalLongName" SG_ 2158870528 ODDLA_WrpArnd "Open Display Interface Dynamic Data List Request Auxiliary IP : Wrap Around";
BA_ "VNSigAllNodes" SG_ 2158870528 ODDLA_WrpArnd 1;
BA_ "GenSigSendType" SG_ 2158870528 ODDLA_ReqType 10;
BA_ "VNSigInfotainment" SG_ 2158870528 ODDLA_ReqType 1;
BA_ "SignalType" SG_ 2158870528 ODDLA_ReqType "ENM";
BA_ "PacketOrder" SG_ 2158870528 ODDLA_ReqType 7;
BA_ "SignalLongName" SG_ 2158870528 ODDLA_ReqType "Open Display Interface Dynamic Data List Request Auxiliary IP : Request Type";
BA_ "VNSigAllNodes" SG_ 2158870528 ODDLA_ReqType 1;
BA_ "GenSigSendType" SG_ 2158870528 ODDLA_ReqDir 10;
BA_ "VNSigInfotainment" SG_ 2158870528 ODDLA_ReqDir 1;
BA_ "SignalType" SG_ 2158870528 ODDLA_ReqDir "BLN";
BA_ "PacketOrder" SG_ 2158870528 ODDLA_ReqDir 5;
BA_ "SignalLongName" SG_ 2158870528 ODDLA_ReqDir "Open Display Interface Dynamic Data List Request Auxiliary IP : Req Direction";
BA_ "VNSigAllNodes" SG_ 2158870528 ODDLA_ReqDir 1;
BA_ "GenSigDeltaValue" SG_ 2158870528 ODDLA_NmEntries 1;
BA_ "GenSigSendType" SG_ 2158870528 ODDLA_NmEntries 12;
BA_ "VNSigInfotainment" SG_ 2158870528 ODDLA_NmEntries 1;
BA_ "SignalType" SG_ 2158870528 ODDLA_NmEntries "UNM";
BA_ "PacketOrder" SG_ 2158870528 ODDLA_NmEntries 4;
BA_ "SignalLongName" SG_ 2158870528 ODDLA_NmEntries "Open Display Interface Dynamic Data List Request Auxiliary IP : Num Entries";
BA_ "VNSigAllNodes" SG_ 2158870528 ODDLA_NmEntries 1;
BA_ "GenSigDeltaValue" SG_ 2158870528 ODDLA_Idx 1;
BA_ "GenSigSendType" SG_ 2158870528 ODDLA_Idx 12;
BA_ "VNSigInfotainment" SG_ 2158870528 ODDLA_Idx 1;
BA_ "SignalType" SG_ 2158870528 ODDLA_Idx "UNM";
BA_ "PacketOrder" SG_ 2158870528 ODDLA_Idx 6;
BA_ "SignalLongName" SG_ 2158870528 ODDLA_Idx "Open Display Interface Dynamic Data List Request Auxiliary IP : Index";
BA_ "VNSigAllNodes" SG_ 2158870528 ODDLA_Idx 1;
BA_ "GenSigDeltaValue" SG_ 2158870528 ODDLA_FUCID 1;
BA_ "GenSigSendType" SG_ 2158870528 ODDLA_FUCID 12;
BA_ "VNSigInfotainment" SG_ 2158870528 ODDLA_FUCID 1;
BA_ "SignalType" SG_ 2158870528 ODDLA_FUCID "UNM";
BA_ "PacketOrder" SG_ 2158870528 ODDLA_FUCID 1;
BA_ "SignalLongName" SG_ 2158870528 ODDLA_FUCID "Open Display Interface Dynamic Data List Request Auxiliary IP : Functional Unit Class ID";
BA_ "VNSigAllNodes" SG_ 2158870528 ODDLA_FUCID 1;
BA_ "GenSigSendType" SG_ 2158870528 ODDLA_DspMID 10;
BA_ "VNSigInfotainment" SG_ 2158870528 ODDLA_DspMID 1;
BA_ "SignalType" SG_ 2158870528 ODDLA_DspMID "ENM";
BA_ "PacketOrder" SG_ 2158870528 ODDLA_DspMID 3;
BA_ "SignalLongName" SG_ 2158870528 ODDLA_DspMID "Open Display Interface Dynamic Data List Request Auxiliary IP : Display Mask Id";
BA_ "VNSigAllNodes" SG_ 2158870528 ODDLA_DspMID 1;
BA_ "GenSigDeltaValue" SG_ 2158870528 ODDLA_DataId 1;
BA_ "GenSigSendType" SG_ 2158870528 ODDLA_DataId 12;
BA_ "VNSigInfotainment" SG_ 2158870528 ODDLA_DataId 1;
BA_ "SignalType" SG_ 2158870528 ODDLA_DataId "UNM";
BA_ "PacketOrder" SG_ 2158870528 ODDLA_DataId 2;
BA_ "SignalLongName" SG_ 2158870528 ODDLA_DataId "Open Display Interface Dynamic Data List Request Auxiliary IP : Data Id";
BA_ "VNSigAllNodes" SG_ 2158870528 ODDLA_DataId 1;
BA_ "GenSigSendType" SG_ 2158870528 ODDLA_BckgndFlag 10;
BA_ "VNSigInfotainment" SG_ 2158870528 ODDLA_BckgndFlag 1;
BA_ "SignalType" SG_ 2158870528 ODDLA_BckgndFlag "ENM";
BA_ "PacketOrder" SG_ 2158870528 ODDLA_BckgndFlag 8;
BA_ "SignalLongName" SG_ 2158870528 ODDLA_BckgndFlag "Open Display Interface Dynamic Data List Request Auxiliary IP : Background Flag";
BA_ "VNSigAllNodes" SG_ 2158870528 ODDLA_BckgndFlag 1;
BA_ "GenSigSendType" SG_ 2154692608 LgclAVChnl 10;
BA_ "SignalType" SG_ 2154692608 LgclAVChnl "ENM";
BA_ "SignalLongName" SG_ 2154692608 LgclAVChnl "Logical AV Channel";
BA_ "VNSigAllNodes" SG_ 2154692608 LgclAVChnl 1;
BA_ "GenSigSendType" SG_ 2154692608 ASSAudSrcStatCode 10;
BA_ "VNSigInfotainment" SG_ 2154692608 ASSAudSrcStatCode 1;
BA_ "SignalType" SG_ 2154692608 ASSAudSrcStatCode "ENM";
BA_ "PacketOrder" SG_ 2154692608 ASSAudSrcStatCode 3;
BA_ "SignalLongName" SG_ 2154692608 ASSAudSrcStatCode "Audio Source Status : Audio Source Status Code";
BA_ "VNSigAllNodes" SG_ 2154692608 ASSAudSrcStatCode 1;
BA_ "GenSigSendType" SG_ 2154692608 ASSAudSrcChType 10;
BA_ "VNSigInfotainment" SG_ 2154692608 ASSAudSrcChType 1;
BA_ "SignalType" SG_ 2154692608 ASSAudSrcChType "ENM";
BA_ "PacketOrder" SG_ 2154692608 ASSAudSrcChType 2;
BA_ "SignalLongName" SG_ 2154692608 ASSAudSrcChType "Audio Source Status : Audio Source Channel Type";
BA_ "VNSigAllNodes" SG_ 2154692608 ASSAudSrcChType 1;
BA_ "GenSigSendType" SG_ 2154692608 ASSAudSrcType 10;
BA_ "VNSigInfotainment" SG_ 2154692608 ASSAudSrcType 1;
BA_ "SignalType" SG_ 2154692608 ASSAudSrcType "ENM";
BA_ "PacketOrder" SG_ 2154692608 ASSAudSrcType 1;
BA_ "SignalLongName" SG_ 2154692608 ASSAudSrcType "Audio Source Status : Audio Source Type";
BA_ "VNSigAllNodes" SG_ 2154692608 ASSAudSrcType 1;
BA_ "GenSigSendType" SG_ 2154627072 LgclAVChnl_368 10;
BA_ "SignalType" SG_ 2154627072 LgclAVChnl_368 "ENM";
BA_ "SignalLongName" SG_ 2154627072 LgclAVChnl_368 "Logical AV Channel";
BA_ "VNSigAllNodes" SG_ 2154627072 LgclAVChnl_368 1;
BA_ "GenSigSendType" SG_ 2154627072 AudMstrSrcTyp 10;
BA_ "VNSigInfotainment" SG_ 2154627072 AudMstrSrcTyp 1;
BA_ "SignalType" SG_ 2154627072 AudMstrSrcTyp "ENM";
BA_ "SignalLongName" SG_ 2154627072 AudMstrSrcTyp "Audio Master Source Type";
BA_ "VNSigAllNodes" SG_ 2154627072 AudMstrSrcTyp 1;
BA_ "GenSigSendType" SG_ 2154627072 AudMstrChnnlTyp 10;
BA_ "VNSigInfotainment" SG_ 2154627072 AudMstrChnnlTyp 1;
BA_ "SignalType" SG_ 2154627072 AudMstrChnnlTyp "ENM";
BA_ "SignalLongName" SG_ 2154627072 AudMstrChnnlTyp "Audio Master Channel Type";
BA_ "VNSigAllNodes" SG_ 2154627072 AudMstrChnnlTyp 1;
BA_ "GenSigSendType" SG_ 2154627072 AudMstrArbCom 10;
BA_ "VNSigInfotainment" SG_ 2154627072 AudMstrArbCom 1;
BA_ "SignalType" SG_ 2154627072 AudMstrArbCom "ENM";
BA_ "SignalLongName" SG_ 2154627072 AudMstrArbCom "Audio Master Arbitration Command";
BA_ "VNSigAllNodes" SG_ 2154627072 AudMstrArbCom 1;
BA_ "GenSigSendType" SG_ 2151112704 FrPasSeatbltRemOccSt 10;
BA_ "GenSigSendOnInit" SG_ 2151112704 FrPasSeatbltRemOccSt 2;
BA_ "SignalType" SG_ 2151112704 FrPasSeatbltRemOccSt "ENM";
BA_ "SignalLongName" SG_ 2151112704 FrPasSeatbltRemOccSt "Front Passenger Seatbelt Reminder Occupancy Status";
BA_ "VNSigAllNodes" SG_ 2151112704 FrPasSeatbltRemOccSt 1;
BA_ "GenSigSendType" SG_ 2151112704 FrPasSeatResCtrlOccStV 10;
BA_ "GenSigSendOnInit" SG_ 2151112704 FrPasSeatResCtrlOccStV 2;
BA_ "SignalType" SG_ 2151112704 FrPasSeatResCtrlOccStV "ENM";
BA_ "SignalLongName" SG_ 2151112704 FrPasSeatResCtrlOccStV "Front Passenger Seat Restraint Control Occupancy Status Validity";
BA_ "VNSigAllNodes" SG_ 2151112704 FrPasSeatResCtrlOccStV 1;
BA_ "GenSigSendType" SG_ 2151112704 FrPasSeatResCtrlOccSt 10;
BA_ "GenSigSendOnInit" SG_ 2151112704 FrPasSeatResCtrlOccSt 2;
BA_ "SignalType" SG_ 2151112704 FrPasSeatResCtrlOccSt "ENM";
BA_ "SignalLongName" SG_ 2151112704 FrPasSeatResCtrlOccSt "Front Passenger Seat Restraint Control Occupancy Status";
BA_ "VNSigAllNodes" SG_ 2151112704 FrPasSeatResCtrlOccSt 1;
BA_ "GenSigSendType" SG_ 2151112704 FrPsSeatOccSnsOpMd 10;
BA_ "GenSigSendOnInit" SG_ 2151112704 FrPsSeatOccSnsOpMd 2;
BA_ "SignalType" SG_ 2151112704 FrPsSeatOccSnsOpMd "ENM";
BA_ "SignalLongName" SG_ 2151112704 FrPsSeatOccSnsOpMd "Front Passenger Seat Occupancy Sensing Operating Mode";
BA_ "VNSigAllNodes" SG_ 2151112704 FrPsSeatOccSnsOpMd 1;
BA_ "GenSigSendType" SG_ 2151112704 FrPsSeatOccFltSt 10;
BA_ "GenSigSendOnInit" SG_ 2151112704 FrPsSeatOccFltSt 2;
BA_ "SignalType" SG_ 2151112704 FrPsSeatOccFltSt "ENM";
BA_ "SignalLongName" SG_ 2151112704 FrPsSeatOccFltSt "Front Passenger Seat Occupancy Fault Status";
BA_ "VNSigAllNodes" SG_ 2151112704 FrPsSeatOccFltSt 1;
BA_ "GenSigSendType" SG_ 2151112704 FrntPassClass 10;
BA_ "GenSigSendOnInit" SG_ 2151112704 FrntPassClass 2;
BA_ "SignalType" SG_ 2151112704 FrntPassClass "ENM";
BA_ "SignalLongName" SG_ 2151112704 FrntPassClass "Front Passenger Classification";
BA_ "VNSigAllNodes" SG_ 2151112704 FrntPassClass 1;
BA_ "GenSigSendType" SG_ 2153938944 RmtRflshMdReqtd 10;
BA_ "VNSigRemoteDiagnostics" SG_ 2153938944 RmtRflshMdReqtd 1;
BA_ "SignalType" SG_ 2153938944 RmtRflshMdReqtd "BLN";
BA_ "SignalLongName" SG_ 2153938944 RmtRflshMdReqtd "Remote Reflash Mode Requested";
BA_ "SignalType" SG_ 2028 DgnInf "UNM";
BA_ "SignalLongName" SG_ 2028 DgnInf "Diagnostic Information";
BA_ "VNSigDiagnostic" SG_ 2028 DgnInf 1;
BA_ "VNSigAllNodes" SG_ 2028 DgnInf 1;
BA_ "GenSigDeltaValue" SG_ 2159239168 ODI_TEL2OTIM 1;
BA_ "GenSigSendType" SG_ 2159239168 ODI_TEL2OTIM 12;
BA_ "VNSigInfotainment" SG_ 2159239168 ODI_TEL2OTIM 1;
BA_ "SignalType" SG_ 2159239168 ODI_TEL2OTIM "UNM";
BA_ "SignalLongName" SG_ 2159239168 ODI_TEL2OTIM "Open Display Interface TEL 2 OTIM";
BA_ "VNSigAllNodes" SG_ 2159239168 ODI_TEL2OTIM 1;
BA_ "GenSigDeltaValue" SG_ 2159230976 ODI_OTIM2TEL 1;
BA_ "GenSigSendType" SG_ 2159230976 ODI_OTIM2TEL 12;
BA_ "VNSigInfotainment" SG_ 2159230976 ODI_OTIM2TEL 1;
BA_ "SignalType" SG_ 2159230976 ODI_OTIM2TEL "UNM";
BA_ "SignalLongName" SG_ 2159230976 ODI_OTIM2TEL "Open Display Interface OTIM 2 TEL";
BA_ "VNSigAllNodes" SG_ 2159230976 ODI_OTIM2TEL 1;
BA_ "GenSigDeltaValue" SG_ 2159222784 ODI_PDIM2CntrStck 1;
BA_ "GenSigSendType" SG_ 2159222784 ODI_PDIM2CntrStck 12;
BA_ "VNSigInfotainment" SG_ 2159222784 ODI_PDIM2CntrStck 1;
BA_ "SignalType" SG_ 2159222784 ODI_PDIM2CntrStck "UNM";
BA_ "SignalLongName" SG_ 2159222784 ODI_PDIM2CntrStck "Open Display Interface PDIM 2 Centerstack";
BA_ "VNSigAllNodes" SG_ 2159222784 ODI_PDIM2CntrStck 1;
BA_ "GenSigDeltaValue" SG_ 2159214592 ODI_CntrStck2PDIM 1;
BA_ "GenSigSendType" SG_ 2159214592 ODI_CntrStck2PDIM 12;
BA_ "VNSigInfotainment" SG_ 2159214592 ODI_CntrStck2PDIM 1;
BA_ "SignalType" SG_ 2159214592 ODI_CntrStck2PDIM "UNM";
BA_ "SignalLongName" SG_ 2159214592 ODI_CntrStck2PDIM "Open Display Interface Centerstack 2 PDIM";
BA_ "VNSigAllNodes" SG_ 2159214592 ODI_CntrStck2PDIM 1;
BA_ "GenSigSendType" SG_ 2158862336 ODIAOT_FUCID 12;
BA_ "VNSigInfotainment" SG_ 2158862336 ODIAOT_FUCID 1;
BA_ "SignalType" SG_ 2158862336 ODIAOT_FUCID "UNM";
BA_ "PacketOrder" SG_ 2158862336 ODIAOT_FUCID 2;
BA_ "SignalLongName" SG_ 2158862336 ODIAOT_FUCID "Open Display Interface Action OTIM : FU Class ID";
BA_ "VNSigAllNodes" SG_ 2158862336 ODIAOT_FUCID 1;
BA_ "GenSigSendType" SG_ 2158862336 ODIAOT_DspMID 10;
BA_ "VNSigInfotainment" SG_ 2158862336 ODIAOT_DspMID 1;
BA_ "SignalType" SG_ 2158862336 ODIAOT_DspMID "ENM";
BA_ "PacketOrder" SG_ 2158862336 ODIAOT_DspMID 4;
BA_ "SignalLongName" SG_ 2158862336 ODIAOT_DspMID "Open Display Interface Action OTIM : Display Mask ID";
BA_ "VNSigAllNodes" SG_ 2158862336 ODIAOT_DspMID 1;
BA_ "GenSigSendType" SG_ 2158862336 ODIAOT_DaTy 10;
BA_ "VNSigInfotainment" SG_ 2158862336 ODIAOT_DaTy 1;
BA_ "SignalType" SG_ 2158862336 ODIAOT_DaTy "ENM";
BA_ "PacketOrder" SG_ 2158862336 ODIAOT_DaTy 1;
BA_ "SignalLongName" SG_ 2158862336 ODIAOT_DaTy "Open Display Interface Action OTIM : DataType";
BA_ "VNSigAllNodes" SG_ 2158862336 ODIAOT_DaTy 1;
BA_ "GenSigSendType" SG_ 2158862336 ODIAOT_ActnVal 12;
BA_ "VNSigInfotainment" SG_ 2158862336 ODIAOT_ActnVal 1;
BA_ "SignalType" SG_ 2158862336 ODIAOT_ActnVal "UNM";
BA_ "PacketOrder" SG_ 2158862336 ODIAOT_ActnVal 5;
BA_ "SignalLongName" SG_ 2158862336 ODIAOT_ActnVal "Open Display Interface Action OTIM : Action Value";
BA_ "VNSigAllNodes" SG_ 2158862336 ODIAOT_ActnVal 1;
BA_ "GenSigSendType" SG_ 2158862336 ODIAOT_ActnID 12;
BA_ "VNSigInfotainment" SG_ 2158862336 ODIAOT_ActnID 1;
BA_ "SignalType" SG_ 2158862336 ODIAOT_ActnID "UNM";
BA_ "PacketOrder" SG_ 2158862336 ODIAOT_ActnID 3;
BA_ "SignalLongName" SG_ 2158862336 ODIAOT_ActnID "Open Display Interface Action OTIM : Action ID";
BA_ "VNSigAllNodes" SG_ 2158862336 ODIAOT_ActnID 1;
BA_ "GenSigDeltaValue" SG_ 2150662144 EnvIdRsp3 1;
BA_ "GenSigSendType" SG_ 2150662144 EnvIdRsp3 12;
BA_ "SignalType" SG_ 2150662144 EnvIdRsp3 "UNM";
BA_ "SignalLongName" SG_ 2150662144 EnvIdRsp3 "Environment Identification Response 3";
BA_ "VNSigAllNodes" SG_ 2150662144 EnvIdRsp3 1;
BA_ "GenSigSendType" SG_ 2150662144 EnvIdRspSt3 10;
BA_ "SignalType" SG_ 2150662144 EnvIdRspSt3 "ENM";
BA_ "SignalLongName" SG_ 2150662144 EnvIdRspSt3 "Environment Identification Response Status 3";
BA_ "VNSigAllNodes" SG_ 2150662144 EnvIdRspSt3 1;
BA_ "GenSigSendType" SG_ 2150653952 EnvIdRspSt2 10;
BA_ "SignalType" SG_ 2150653952 EnvIdRspSt2 "ENM";
BA_ "SignalLongName" SG_ 2150653952 EnvIdRspSt2 "Environment Identification Response Status 2";
BA_ "VNSigAllNodes" SG_ 2150653952 EnvIdRspSt2 1;
BA_ "GenSigDeltaValue" SG_ 2150653952 EnvIdRsp2 1;
BA_ "GenSigSendType" SG_ 2150653952 EnvIdRsp2 12;
BA_ "SignalType" SG_ 2150653952 EnvIdRsp2 "UNM";
BA_ "SignalLongName" SG_ 2150653952 EnvIdRsp2 "Environment Identification Response 2";
BA_ "VNSigAllNodes" SG_ 2150653952 EnvIdRsp2 1;
BA_ "GenSigSendType" SG_ 2150850560 PsSbltAtcV 10;
BA_ "GenSigSendOnInit" SG_ 2150850560 PsSbltAtcV 2;
BA_ "SignalType" SG_ 2150850560 PsSbltAtcV "ENM";
BA_ "SignalLongName" SG_ 2150850560 PsSbltAtcV "Passenger Seatbelt Attached Validity";
BA_ "VNSigAllNodes" SG_ 2150850560 PsSbltAtcV 1;
BA_ "GenSigSendType" SG_ 2150850560 PsSbltAtc 10;
BA_ "GenSigSendOnInit" SG_ 2150850560 PsSbltAtc 2;
BA_ "SignalType" SG_ 2150850560 PsSbltAtc "BLN";
BA_ "SignalLongName" SG_ 2150850560 PsSbltAtc "Passenger Seatbelt Attached";
BA_ "VNSigAllNodes" SG_ 2150850560 PsSbltAtc 1;
BA_ "GenSigSendType" SG_ 2150850560 DrSbltAtcV 10;
BA_ "SignalType" SG_ 2150850560 DrSbltAtcV "ENM";
BA_ "SignalLongName" SG_ 2150850560 DrSbltAtcV "Driver Seatbelt Attached Validity";
BA_ "VNSigAllNodes" SG_ 2150850560 DrSbltAtcV 1;
BA_ "GenSigSendType" SG_ 2150850560 DrSbltAtc 10;
BA_ "SignalType" SG_ 2150850560 DrSbltAtc "BLN";
BA_ "SignalLongName" SG_ 2150850560 DrSbltAtc "Driver Seatbelt Attached";
BA_ "VNSigAllNodes" SG_ 2150850560 DrSbltAtc 1;
BA_ "GenSigSendType" SG_ 2154659840 StrgClmnLckVisNot 10;
BA_ "SignalType" SG_ 2154659840 StrgClmnLckVisNot "BLN";
BA_ "SignalLongName" SG_ 2154659840 StrgClmnLckVisNot "Steering Column Locked Visual Notify";
BA_ "VNSigAllNodes" SG_ 2154659840 StrgClmnLckVisNot 1;
BA_ "GenSigSendType" SG_ 2154659840 UnlockRtryPshIndOn 10;
BA_ "SignalType" SG_ 2154659840 UnlockRtryPshIndOn "BLN";
BA_ "SignalLongName" SG_ 2154659840 UnlockRtryPshIndOn "Unlock Retry Push Indication On";
BA_ "VNSigAllNodes" SG_ 2154659840 UnlockRtryPshIndOn 1;
BA_ "GenSigSendType" SG_ 2154659840 UnlckRtryRotIndOn 10;
BA_ "SignalType" SG_ 2154659840 UnlckRtryRotIndOn "BLN";
BA_ "SignalLongName" SG_ 2154659840 UnlckRtryRotIndOn "Unlock Retry Rotation Indication On";
BA_ "VNSigAllNodes" SG_ 2154659840 UnlckRtryRotIndOn 1;
BA_ "GenSigSendType" SG_ 2154659840 ClmSysFlrIndOn 10;
BA_ "SignalType" SG_ 2154659840 ClmSysFlrIndOn "BLN";
BA_ "SignalLongName" SG_ 2154659840 ClmSysFlrIndOn "Column System Failure Indication On";
BA_ "VNSigAllNodes" SG_ 2154659840 ClmSysFlrIndOn 1;
BA_ "GenSigSendType" SG_ 2154659840 StrngClmnLckTT 10;
BA_ "SignalType" SG_ 2154659840 StrngClmnLckTT "ENM";
BA_ "SignalLongName" SG_ 2154659840 StrngClmnLckTT "Steering Column Lock Telltale";
BA_ "VNSigAllNodes" SG_ 2154659840 StrngClmnLckTT 1;
BA_ "GenSigSendType" SG_ 2154659840 ClmnLckStatV 10;
BA_ "SignalType" SG_ 2154659840 ClmnLckStatV "ENM";
BA_ "SignalLongName" SG_ 2154659840 ClmnLckStatV "Column Lock Status Validity";
BA_ "VNSigAllNodes" SG_ 2154659840 ClmnLckStatV 1;
BA_ "GenSigSendType" SG_ 2154659840 ClmnLckStat 10;
BA_ "GenSigSendOnInit" SG_ 2154659840 ClmnLckStat 2;
BA_ "SignalType" SG_ 2154659840 ClmnLckStat "ENM";
BA_ "SignalLongName" SG_ 2154659840 ClmnLckStat "Column Lock Status";
BA_ "VNSigAllNodes" SG_ 2154659840 ClmnLckStat 1;
BA_ "GenSigSendType" SG_ 2154938368 FobProgMdStat 10;
BA_ "SignalType" SG_ 2154938368 FobProgMdStat "ENM";
BA_ "SignalLongName" SG_ 2154938368 FobProgMdStat "Fob Programming Mode Status";
BA_ "VNSigAllNodes" SG_ 2154938368 FobProgMdStat 1;
BA_ "GenSigSendType" SG_ 2155266048 RRHCSeatSw3Act 10;
BA_ "GenSigSendOnInit" SG_ 2155266048 RRHCSeatSw3Act 2;
BA_ "SignalType" SG_ 2155266048 RRHCSeatSw3Act "BLN";
BA_ "SignalLongName" SG_ 2155266048 RRHCSeatSw3Act "Rear Right Heated/Cooled Seat Switch #3 Active";
BA_ "VNSigAllNodes" SG_ 2155266048 RRHCSeatSw3Act 1;
BA_ "GenSigSendType" SG_ 2155266048 RRHCSeatSw2Act 10;
BA_ "GenSigSendOnInit" SG_ 2155266048 RRHCSeatSw2Act 2;
BA_ "SignalType" SG_ 2155266048 RRHCSeatSw2Act "BLN";
BA_ "SignalLongName" SG_ 2155266048 RRHCSeatSw2Act "Rear Right Heated/Cooled Seat Switch #2 Active";
BA_ "VNSigAllNodes" SG_ 2155266048 RRHCSeatSw2Act 1;
BA_ "GenSigSendType" SG_ 2155266048 RRHCSeatSw1Act 10;
BA_ "GenSigSendOnInit" SG_ 2155266048 RRHCSeatSw1Act 2;
BA_ "SignalType" SG_ 2155266048 RRHCSeatSw1Act "BLN";
BA_ "SignalLongName" SG_ 2155266048 RRHCSeatSw1Act "Rear Right Heated/Cooled Seat Switch #1 Active";
BA_ "VNSigAllNodes" SG_ 2155266048 RRHCSeatSw1Act 1;
BA_ "GenSigSendType" SG_ 2155266048 RLHCSeatSw3Act 10;
BA_ "GenSigSendOnInit" SG_ 2155266048 RLHCSeatSw3Act 2;
BA_ "SignalType" SG_ 2155266048 RLHCSeatSw3Act "BLN";
BA_ "SignalLongName" SG_ 2155266048 RLHCSeatSw3Act "Rear Left Heated/Cooled Seat Switch #3 Active";
BA_ "VNSigAllNodes" SG_ 2155266048 RLHCSeatSw3Act 1;
BA_ "GenSigSendType" SG_ 2155266048 RLHCSeatSw2Act 10;
BA_ "GenSigSendOnInit" SG_ 2155266048 RLHCSeatSw2Act 2;
BA_ "SignalType" SG_ 2155266048 RLHCSeatSw2Act "BLN";
BA_ "SignalLongName" SG_ 2155266048 RLHCSeatSw2Act "Rear Left Heated/Cooled Seat Switch #2 Active";
BA_ "VNSigAllNodes" SG_ 2155266048 RLHCSeatSw2Act 1;
BA_ "GenSigSendType" SG_ 2155266048 RLHCSeatSw1Act 10;
BA_ "GenSigSendOnInit" SG_ 2155266048 RLHCSeatSw1Act 2;
BA_ "SignalType" SG_ 2155266048 RLHCSeatSw1Act "BLN";
BA_ "SignalLongName" SG_ 2155266048 RLHCSeatSw1Act "Rear Left Heated/Cooled Seat Switch #1 Active";
BA_ "VNSigAllNodes" SG_ 2155266048 RLHCSeatSw1Act 1;
BA_ "GenSigSendType" SG_ 2155249664 RRHCSMInd3 10;
BA_ "GenSigSendOnInit" SG_ 2155249664 RRHCSMInd3 1;
BA_ "SignalType" SG_ 2155249664 RRHCSMInd3 "BLN";
BA_ "PacketOrder" SG_ 2155249664 RRHCSMInd3 4;
BA_ "SignalLongName" SG_ 2155249664 RRHCSMInd3 "Rear Right Heated/Cooled Seat Mode Indication Control : Seat Mode Indication 3";
BA_ "VNSigAllNodes" SG_ 2155249664 RRHCSMInd3 1;
BA_ "GenSigSendType" SG_ 2155249664 RRHCSMInd2 10;
BA_ "GenSigSendOnInit" SG_ 2155249664 RRHCSMInd2 1;
BA_ "SignalType" SG_ 2155249664 RRHCSMInd2 "BLN";
BA_ "PacketOrder" SG_ 2155249664 RRHCSMInd2 3;
BA_ "SignalLongName" SG_ 2155249664 RRHCSMInd2 "Rear Right Heated/Cooled Seat Mode Indication Control : Seat Mode Indication 2";
BA_ "VNSigAllNodes" SG_ 2155249664 RRHCSMInd2 1;
BA_ "GenSigSendType" SG_ 2155249664 RRHCSMInd1 10;
BA_ "GenSigSendOnInit" SG_ 2155249664 RRHCSMInd1 1;
BA_ "SignalType" SG_ 2155249664 RRHCSMInd1 "BLN";
BA_ "PacketOrder" SG_ 2155249664 RRHCSMInd1 2;
BA_ "SignalLongName" SG_ 2155249664 RRHCSMInd1 "Rear Right Heated/Cooled Seat Mode Indication Control : Seat Mode Indication 1";
BA_ "VNSigAllNodes" SG_ 2155249664 RRHCSMInd1 1;
BA_ "GenSigSendType" SG_ 2155249664 RRHCSMIndReq 10;
BA_ "GenSigSendOnInit" SG_ 2155249664 RRHCSMIndReq 1;
BA_ "SignalType" SG_ 2155249664 RRHCSMIndReq "ENM";
BA_ "PacketOrder" SG_ 2155249664 RRHCSMIndReq 1;
BA_ "SignalLongName" SG_ 2155249664 RRHCSMIndReq "Rear Right Heated/Cooled Seat Mode Indication Control : Indication Request";
BA_ "VNSigAllNodes" SG_ 2155249664 RRHCSMIndReq 1;
BA_ "GenSigSendType" SG_ 2155249664 RRHCSLSeatLev5 10;
BA_ "GenSigSendOnInit" SG_ 2155249664 RRHCSLSeatLev5 1;
BA_ "SignalType" SG_ 2155249664 RRHCSLSeatLev5 "BLN";
BA_ "PacketOrder" SG_ 2155249664 RRHCSLSeatLev5 6;
BA_ "SignalLongName" SG_ 2155249664 RRHCSLSeatLev5 "Rear Right Heated/Cooled Seat Level Indication Control : Seat Level 5";
BA_ "VNSigAllNodes" SG_ 2155249664 RRHCSLSeatLev5 1;
BA_ "GenSigSendType" SG_ 2155249664 RRHCSLSeatLev4 10;
BA_ "GenSigSendOnInit" SG_ 2155249664 RRHCSLSeatLev4 1;
BA_ "SignalType" SG_ 2155249664 RRHCSLSeatLev4 "BLN";
BA_ "PacketOrder" SG_ 2155249664 RRHCSLSeatLev4 5;
BA_ "SignalLongName" SG_ 2155249664 RRHCSLSeatLev4 "Rear Right Heated/Cooled Seat Level Indication Control : Seat Level 4";
BA_ "VNSigAllNodes" SG_ 2155249664 RRHCSLSeatLev4 1;
BA_ "GenSigSendType" SG_ 2155249664 RRHCSLSeatLev3 10;
BA_ "GenSigSendOnInit" SG_ 2155249664 RRHCSLSeatLev3 1;
BA_ "SignalType" SG_ 2155249664 RRHCSLSeatLev3 "BLN";
BA_ "PacketOrder" SG_ 2155249664 RRHCSLSeatLev3 4;
BA_ "SignalLongName" SG_ 2155249664 RRHCSLSeatLev3 "Rear Right Heated/Cooled Seat Level Indication Control : Seat Level 3";
BA_ "VNSigAllNodes" SG_ 2155249664 RRHCSLSeatLev3 1;
BA_ "GenSigSendType" SG_ 2155249664 RRHCSLSeatLev2 10;
BA_ "GenSigSendOnInit" SG_ 2155249664 RRHCSLSeatLev2 1;
BA_ "SignalType" SG_ 2155249664 RRHCSLSeatLev2 "BLN";
BA_ "PacketOrder" SG_ 2155249664 RRHCSLSeatLev2 3;
BA_ "SignalLongName" SG_ 2155249664 RRHCSLSeatLev2 "Rear Right Heated/Cooled Seat Level Indication Control : Seat Level 2";
BA_ "VNSigAllNodes" SG_ 2155249664 RRHCSLSeatLev2 1;
BA_ "GenSigSendType" SG_ 2155249664 RRHCSLSeatLev1 10;
BA_ "GenSigSendOnInit" SG_ 2155249664 RRHCSLSeatLev1 1;
BA_ "SignalType" SG_ 2155249664 RRHCSLSeatLev1 "BLN";
BA_ "PacketOrder" SG_ 2155249664 RRHCSLSeatLev1 2;
BA_ "SignalLongName" SG_ 2155249664 RRHCSLSeatLev1 "Rear Right Heated/Cooled Seat Level Indication Control : Seat Level 1";
BA_ "VNSigAllNodes" SG_ 2155249664 RRHCSLSeatLev1 1;
BA_ "GenSigSendType" SG_ 2155249664 RRHCSLIndReq 10;
BA_ "GenSigSendOnInit" SG_ 2155249664 RRHCSLIndReq 1;
BA_ "SignalType" SG_ 2155249664 RRHCSLIndReq "ENM";
BA_ "PacketOrder" SG_ 2155249664 RRHCSLIndReq 1;
BA_ "SignalLongName" SG_ 2155249664 RRHCSLIndReq "Rear Right Heated/Cooled Seat Level Indication Control : Indication Request";
BA_ "VNSigAllNodes" SG_ 2155249664 RRHCSLIndReq 1;
BA_ "GenSigSendType" SG_ 2155249664 RLHCSMInd3 10;
BA_ "GenSigSendOnInit" SG_ 2155249664 RLHCSMInd3 1;
BA_ "SignalType" SG_ 2155249664 RLHCSMInd3 "BLN";
BA_ "PacketOrder" SG_ 2155249664 RLHCSMInd3 4;
BA_ "SignalLongName" SG_ 2155249664 RLHCSMInd3 "Rear Left Heated/Cooled Seat Mode Indication Control : Seat Mode Indication 3";
BA_ "VNSigAllNodes" SG_ 2155249664 RLHCSMInd3 1;
BA_ "GenSigSendType" SG_ 2155249664 RLHCSMInd2 10;
BA_ "GenSigSendOnInit" SG_ 2155249664 RLHCSMInd2 1;
BA_ "SignalType" SG_ 2155249664 RLHCSMInd2 "BLN";
BA_ "PacketOrder" SG_ 2155249664 RLHCSMInd2 3;
BA_ "SignalLongName" SG_ 2155249664 RLHCSMInd2 "Rear Left Heated/Cooled Seat Mode Indication Control : Seat Mode Indication 2";
BA_ "VNSigAllNodes" SG_ 2155249664 RLHCSMInd2 1;
BA_ "GenSigSendType" SG_ 2155249664 RLHCSMInd1 10;
BA_ "GenSigSendOnInit" SG_ 2155249664 RLHCSMInd1 1;
BA_ "SignalType" SG_ 2155249664 RLHCSMInd1 "BLN";
BA_ "PacketOrder" SG_ 2155249664 RLHCSMInd1 2;
BA_ "SignalLongName" SG_ 2155249664 RLHCSMInd1 "Rear Left Heated/Cooled Seat Mode Indication Control : Seat Mode Indication 1";
BA_ "VNSigAllNodes" SG_ 2155249664 RLHCSMInd1 1;
BA_ "GenSigSendType" SG_ 2155249664 RLHCSMIndReq 10;
BA_ "GenSigSendOnInit" SG_ 2155249664 RLHCSMIndReq 1;
BA_ "SignalType" SG_ 2155249664 RLHCSMIndReq "ENM";
BA_ "PacketOrder" SG_ 2155249664 RLHCSMIndReq 1;
BA_ "SignalLongName" SG_ 2155249664 RLHCSMIndReq "Rear Left Heated/Cooled Seat Mode Indication Control : Indication Request";
BA_ "VNSigAllNodes" SG_ 2155249664 RLHCSMIndReq 1;
BA_ "GenSigSendType" SG_ 2155249664 RLHCSLSeatLev5 10;
BA_ "GenSigSendOnInit" SG_ 2155249664 RLHCSLSeatLev5 1;
BA_ "SignalType" SG_ 2155249664 RLHCSLSeatLev5 "BLN";
BA_ "PacketOrder" SG_ 2155249664 RLHCSLSeatLev5 6;
BA_ "SignalLongName" SG_ 2155249664 RLHCSLSeatLev5 "Rear Left Heated/Cooled Seat Level Indication Control : Seat Level 5";
BA_ "VNSigAllNodes" SG_ 2155249664 RLHCSLSeatLev5 1;
BA_ "GenSigSendType" SG_ 2155249664 RLHCSLSeatLev4 10;
BA_ "GenSigSendOnInit" SG_ 2155249664 RLHCSLSeatLev4 1;
BA_ "SignalType" SG_ 2155249664 RLHCSLSeatLev4 "BLN";
BA_ "PacketOrder" SG_ 2155249664 RLHCSLSeatLev4 5;
BA_ "SignalLongName" SG_ 2155249664 RLHCSLSeatLev4 "Rear Left Heated/Cooled Seat Level Indication Control : Seat Level 4";
BA_ "VNSigAllNodes" SG_ 2155249664 RLHCSLSeatLev4 1;
BA_ "GenSigSendType" SG_ 2155249664 RLHCSLSeatLev3 10;
BA_ "GenSigSendOnInit" SG_ 2155249664 RLHCSLSeatLev3 1;
BA_ "SignalType" SG_ 2155249664 RLHCSLSeatLev3 "BLN";
BA_ "PacketOrder" SG_ 2155249664 RLHCSLSeatLev3 4;
BA_ "SignalLongName" SG_ 2155249664 RLHCSLSeatLev3 "Rear Left Heated/Cooled Seat Level Indication Control : Seat Level 3";
BA_ "VNSigAllNodes" SG_ 2155249664 RLHCSLSeatLev3 1;
BA_ "GenSigSendType" SG_ 2155249664 RLHCSLSeatLev2 10;
BA_ "GenSigSendOnInit" SG_ 2155249664 RLHCSLSeatLev2 1;
BA_ "SignalType" SG_ 2155249664 RLHCSLSeatLev2 "BLN";
BA_ "PacketOrder" SG_ 2155249664 RLHCSLSeatLev2 3;
BA_ "SignalLongName" SG_ 2155249664 RLHCSLSeatLev2 "Rear Left Heated/Cooled Seat Level Indication Control : Seat Level 2";
BA_ "VNSigAllNodes" SG_ 2155249664 RLHCSLSeatLev2 1;
BA_ "GenSigSendType" SG_ 2155249664 RLHCSLSeatLev1 10;
BA_ "GenSigSendOnInit" SG_ 2155249664 RLHCSLSeatLev1 1;
BA_ "SignalType" SG_ 2155249664 RLHCSLSeatLev1 "BLN";
BA_ "PacketOrder" SG_ 2155249664 RLHCSLSeatLev1 2;
BA_ "SignalLongName" SG_ 2155249664 RLHCSLSeatLev1 "Rear Left Heated/Cooled Seat Level Indication Control : Seat Level 1";
BA_ "VNSigAllNodes" SG_ 2155249664 RLHCSLSeatLev1 1;
BA_ "GenSigSendType" SG_ 2155249664 RLHCSLIndReq 10;
BA_ "GenSigSendOnInit" SG_ 2155249664 RLHCSLIndReq 1;
BA_ "SignalType" SG_ 2155249664 RLHCSLIndReq "ENM";
BA_ "PacketOrder" SG_ 2155249664 RLHCSLIndReq 1;
BA_ "SignalLongName" SG_ 2155249664 RLHCSLIndReq "Rear Left Heated/Cooled Seat Level Indication Control : Indication Request";
BA_ "VNSigAllNodes" SG_ 2155249664 RLHCSLIndReq 1;
BA_ "GenSigSendType" SG_ 2155184128 SmPhRmFunCstCurStVal 10;
BA_ "GenSigSendOnInit" SG_ 2155184128 SmPhRmFunCstCurStVal 2;
BA_ "VNSigInfotainment" SG_ 2155184128 SmPhRmFunCstCurStVal 1;
BA_ "SignalType" SG_ 2155184128 SmPhRmFunCstCurStVal "ENM";
BA_ "SignalLongName" SG_ 2155184128 SmPhRmFunCstCurStVal "Smart Phone Remote Function Customization Current Setting Value";
BA_ "VNSigAllNodes" SG_ 2155184128 SmPhRmFunCstCurStVal 1;
BA_ "GenSigSendType" SG_ 2155184128 SmPhRmFunCstStAval 10;
BA_ "GenSigSendOnInit" SG_ 2155184128 SmPhRmFunCstStAval 2;
BA_ "VNSigInfotainment" SG_ 2155184128 SmPhRmFunCstStAval 1;
BA_ "SignalType" SG_ 2155184128 SmPhRmFunCstStAval "BLN";
BA_ "SignalLongName" SG_ 2155184128 SmPhRmFunCstStAval "Smart Phone Remote Function Customization Setting Available";
BA_ "VNSigAllNodes" SG_ 2155184128 SmPhRmFunCstStAval 1;
BA_ "GenSigSendType" SG_ 2155184128 RrStRmndrIO 10;
BA_ "GenSigSendOnInit" SG_ 2155184128 RrStRmndrIO 2;
BA_ "SignalType" SG_ 2155184128 RrStRmndrIO "BLN";
BA_ "SignalLongName" SG_ 2155184128 RrStRmndrIO "Rear Seat Reminder Indication On";
BA_ "VNSigAllNodes" SG_ 2155184128 RrStRmndrIO 1;
BA_ "GenSigSendType" SG_ 2155184128 RrStRmndrCstCurrSetVal 10;
BA_ "GenSigSendOnInit" SG_ 2155184128 RrStRmndrCstCurrSetVal 2;
BA_ "SignalType" SG_ 2155184128 RrStRmndrCstCurrSetVal "ENM";
BA_ "SignalLongName" SG_ 2155184128 RrStRmndrCstCurrSetVal "Rear Seat Reminder Customization Current Setting Value";
BA_ "VNSigAllNodes" SG_ 2155184128 RrStRmndrCstCurrSetVal 1;
BA_ "GenSigSendType" SG_ 2155184128 RrStRmndrCstSetAvail 10;
BA_ "GenSigSendOnInit" SG_ 2155184128 RrStRmndrCstSetAvail 2;
BA_ "SignalType" SG_ 2155184128 RrStRmndrCstSetAvail "BLN";
BA_ "SignalLongName" SG_ 2155184128 RrStRmndrCstSetAvail "Rear Seat Reminder Customization Setting Available";
BA_ "VNSigAllNodes" SG_ 2155184128 RrStRmndrCstSetAvail 1;
BA_ "GenSigSendType" SG_ 2155184128 IdlRecmndToClEngIO 10;
BA_ "SignalType" SG_ 2155184128 IdlRecmndToClEngIO "BLN";
BA_ "SignalLongName" SG_ 2155184128 IdlRecmndToClEngIO "Idle Recommended to Cool Engine Indication On";
BA_ "VNSigAllNodes" SG_ 2155184128 IdlRecmndToClEngIO 1;
BA_ "GenSigSendType" SG_ 2155184128 TrnsShftLvrLckStat 10;
BA_ "SignalType" SG_ 2155184128 TrnsShftLvrLckStat "ENM";
BA_ "SignalLongName" SG_ 2155184128 TrnsShftLvrLckStat "Transmission Shift Lever Lock Status";
BA_ "VNSigAllNodes" SG_ 2155184128 TrnsShftLvrLckStat 1;
BA_ "GenSigSendType" SG_ 2155184128 CrsSpdLmtrSwStat 10;
BA_ "SignalType" SG_ 2155184128 CrsSpdLmtrSwStat "ENM";
BA_ "SignalLongName" SG_ 2155184128 CrsSpdLmtrSwStat "Cruise and Speed Limiter Switch Status";
BA_ "VNSigAllNodes" SG_ 2155184128 CrsSpdLmtrSwStat 1;
BA_ "GenSigSendType" SG_ 2155184128 CrsCntrlSwStCanSwAct 10;
BA_ "GenSigSendOnInit" SG_ 2155184128 CrsCntrlSwStCanSwAct 2;
BA_ "SignalType" SG_ 2155184128 CrsCntrlSwStCanSwAct "BLN";
BA_ "PacketOrder" SG_ 2155184128 CrsCntrlSwStCanSwAct 1;
BA_ "SignalLongName" SG_ 2155184128 CrsCntrlSwStCanSwAct "Cruise Control Switch Status : Cancel Switch Active";
BA_ "VNSigAllNodes" SG_ 2155184128 CrsCntrlSwStCanSwAct 1;
BA_ "GenSigSendType" SG_ 2155184128 CrsCntrlSwStSwDataIntgty 10;
BA_ "GenSigSendOnInit" SG_ 2155184128 CrsCntrlSwStSwDataIntgty 2;
BA_ "SignalType" SG_ 2155184128 CrsCntrlSwStSwDataIntgty "ENM";
BA_ "PacketOrder" SG_ 2155184128 CrsCntrlSwStSwDataIntgty 7;
BA_ "SignalLongName" SG_ 2155184128 CrsCntrlSwStSwDataIntgty "Cruise Control Switch Status : Switch Data Integrity";
BA_ "VNSigAllNodes" SG_ 2155184128 CrsCntrlSwStSwDataIntgty 1;
BA_ "GenSigSendType" SG_ 2155184128 CrsCntrlSwStSpdInSwAct 10;
BA_ "GenSigSendOnInit" SG_ 2155184128 CrsCntrlSwStSpdInSwAct 2;
BA_ "SignalType" SG_ 2155184128 CrsCntrlSwStSpdInSwAct "BLN";
BA_ "PacketOrder" SG_ 2155184128 CrsCntrlSwStSpdInSwAct 5;
BA_ "SignalLongName" SG_ 2155184128 CrsCntrlSwStSpdInSwAct "Cruise Control Switch Status : Speed Increase Switch Active";
BA_ "VNSigAllNodes" SG_ 2155184128 CrsCntrlSwStSpdInSwAct 1;
BA_ "GenSigSendType" SG_ 2155184128 CrsCntrlSwStSpDcSwAct 10;
BA_ "GenSigSendOnInit" SG_ 2155184128 CrsCntrlSwStSpDcSwAct 2;
BA_ "SignalType" SG_ 2155184128 CrsCntrlSwStSpDcSwAct "BLN";
BA_ "PacketOrder" SG_ 2155184128 CrsCntrlSwStSpDcSwAct 6;
BA_ "SignalLongName" SG_ 2155184128 CrsCntrlSwStSpDcSwAct "Cruise Control Switch Status : Speed Decrease Switch Active";
BA_ "VNSigAllNodes" SG_ 2155184128 CrsCntrlSwStSpDcSwAct 1;
BA_ "GenSigSendType" SG_ 2155184128 CrsCntrlSwStSetSwAct 10;
BA_ "GenSigSendOnInit" SG_ 2155184128 CrsCntrlSwStSetSwAct 2;
BA_ "SignalType" SG_ 2155184128 CrsCntrlSwStSetSwAct "BLN";
BA_ "PacketOrder" SG_ 2155184128 CrsCntrlSwStSetSwAct 4;
BA_ "SignalLongName" SG_ 2155184128 CrsCntrlSwStSetSwAct "Cruise Control Switch Status : Set Switch Active";
BA_ "VNSigAllNodes" SG_ 2155184128 CrsCntrlSwStSetSwAct 1;
BA_ "GenSigSendType" SG_ 2155184128 CrsCntrlSwStResSwAct 10;
BA_ "GenSigSendOnInit" SG_ 2155184128 CrsCntrlSwStResSwAct 2;
BA_ "SignalType" SG_ 2155184128 CrsCntrlSwStResSwAct "BLN";
BA_ "PacketOrder" SG_ 2155184128 CrsCntrlSwStResSwAct 3;
BA_ "SignalLongName" SG_ 2155184128 CrsCntrlSwStResSwAct "Cruise Control Switch Status : Resume Switch Active";
BA_ "VNSigAllNodes" SG_ 2155184128 CrsCntrlSwStResSwAct 1;
BA_ "GenSigSendType" SG_ 2155184128 CrsCntrlSwStOnSwAct 10;
BA_ "GenSigSendOnInit" SG_ 2155184128 CrsCntrlSwStOnSwAct 2;
BA_ "SignalType" SG_ 2155184128 CrsCntrlSwStOnSwAct "BLN";
BA_ "PacketOrder" SG_ 2155184128 CrsCntrlSwStOnSwAct 2;
BA_ "SignalLongName" SG_ 2155184128 CrsCntrlSwStOnSwAct "Cruise Control Switch Status : On Switch Active";
BA_ "VNSigAllNodes" SG_ 2155184128 CrsCntrlSwStOnSwAct 1;
BA_ "GenSigSendType" SG_ 2155184128 CrsCntAtv 10;
BA_ "GenSigSendOnInit" SG_ 2155184128 CrsCntAtv 2;
BA_ "SignalType" SG_ 2155184128 CrsCntAtv "BLN";
BA_ "SignalLongName" SG_ 2155184128 CrsCntAtv "Cruise Control Active";
BA_ "VNSigAllNodes" SG_ 2155184128 CrsCntAtv 1;
BA_ "GenSigSendType" SG_ 2155167744 ClsEngCmprtmtToStrtVehIO 10;
BA_ "SignalType" SG_ 2155167744 ClsEngCmprtmtToStrtVehIO "BLN";
BA_ "SignalLongName" SG_ 2155167744 ClsEngCmprtmtToStrtVehIO "Close Engine Compartment To Start Vehicle Indication On";
BA_ "VNSigAllNodes" SG_ 2155167744 ClsEngCmprtmtToStrtVehIO 1;
BA_ "GenSigSendType" SG_ 2155167744 PrsCltchPrsStrtAgnIO 10;
BA_ "SignalType" SG_ 2155167744 PrsCltchPrsStrtAgnIO "BLN";
BA_ "SignalLongName" SG_ 2155167744 PrsCltchPrsStrtAgnIO "Press Clutch and Press Start Again Indication On";
BA_ "VNSigAllNodes" SG_ 2155167744 PrsCltchPrsStrtAgnIO 1;
BA_ "GenSigSendType" SG_ 2155167744 PrsStrtAgnIO 10;
BA_ "SignalType" SG_ 2155167744 PrsStrtAgnIO "BLN";
BA_ "SignalLongName" SG_ 2155167744 PrsStrtAgnIO "Press Start Again Indication On";
BA_ "VNSigAllNodes" SG_ 2155167744 PrsStrtAgnIO 1;
BA_ "GenSigSendType" SG_ 2155167744 AutoShtdwnDsblIO 10;
BA_ "SignalType" SG_ 2155167744 AutoShtdwnDsblIO "BLN";
BA_ "SignalLongName" SG_ 2155167744 AutoShtdwnDsblIO "Automatic Shutdown Disabled Indication On";
BA_ "VNSigAllNodes" SG_ 2155167744 AutoShtdwnDsblIO 1;
BA_ "GenSigSendType" SG_ 2155167744 ShftToNtrlIO 10;
BA_ "SignalType" SG_ 2155167744 ShftToNtrlIO "BLN";
BA_ "SignalLongName" SG_ 2155167744 ShftToNtrlIO "Shift to Neutral Indication On";
BA_ "VNSigAllNodes" SG_ 2155167744 ShftToNtrlIO 1;
BA_ "GenSigSendType" SG_ 2155167744 AppPrkBrkIO 10;
BA_ "SignalType" SG_ 2155167744 AppPrkBrkIO "BLN";
BA_ "SignalLongName" SG_ 2155167744 AppPrkBrkIO "Apply Park Brake Indication On";
BA_ "VNSigAllNodes" SG_ 2155167744 AppPrkBrkIO 1;
BA_ "GenSigSendType" SG_ 2155167744 NRmtDtctdRstrtAllwd 10;
BA_ "SignalType" SG_ 2155167744 NRmtDtctdRstrtAllwd "BLN";
BA_ "SignalLongName" SG_ 2155167744 NRmtDtctdRstrtAllwd "No Remote Detected Restart Allowed";
BA_ "VNSigAllNodes" SG_ 2155167744 NRmtDtctdRstrtAllwd 1;
BA_ "GenSigSendType" SG_ 2155167744 NRmtDtdPsCluRstIO 10;
BA_ "SignalType" SG_ 2155167744 NRmtDtdPsCluRstIO "BLN";
BA_ "SignalLongName" SG_ 2155167744 NRmtDtdPsCluRstIO "No Remote Detected Press Clutch to Restart Indicator On";
BA_ "VNSigAllNodes" SG_ 2155167744 NRmtDtdPsCluRstIO 1;
BA_ "GenSigSendType" SG_ 2155167744 SecPwrMdPshBtnAtv 10;
BA_ "SignalType" SG_ 2155167744 SecPwrMdPshBtnAtv "BLN";
BA_ "SignalLongName" SG_ 2155167744 SecPwrMdPshBtnAtv "Secondary Power Mode Pushbutton Active";
BA_ "VNSigAllNodes" SG_ 2155167744 SecPwrMdPshBtnAtv 1;
BA_ "GenSigSendType" SG_ 2155167744 TSLgMdPwrCtOWAtv 10;
BA_ "SignalType" SG_ 2155167744 TSLgMdPwrCtOWAtv "BLN";
BA_ "SignalLongName" SG_ 2155167744 TSLgMdPwrCtOWAtv "Transport Storage Logistic Mode Power Cut Off Warning Active";
BA_ "VNSigAllNodes" SG_ 2155167744 TSLgMdPwrCtOWAtv 1;
BA_ "GenSigSendType" SG_ 2155167744 PrsBtnAgnTTrnEngOffIO 10;
BA_ "SignalType" SG_ 2155167744 PrsBtnAgnTTrnEngOffIO "BLN";
BA_ "SignalLongName" SG_ 2155167744 PrsBtnAgnTTrnEngOffIO "Press Button Again to Turn Engine Off Indicator On";
BA_ "VNSigAllNodes" SG_ 2155167744 PrsBtnAgnTTrnEngOffIO 1;
BA_ "GenSigSendType" SG_ 2155167744 NRmtDtdPsBrkRstIO 10;
BA_ "SignalType" SG_ 2155167744 NRmtDtdPsBrkRstIO "BLN";
BA_ "SignalLongName" SG_ 2155167744 NRmtDtdPsBrkRstIO "No Remote Detected Press Brake to Restart Indicator On";
BA_ "VNSigAllNodes" SG_ 2155167744 NRmtDtdPsBrkRstIO 1;
BA_ "GenSigSendType" SG_ 2155167744 NoReDetInOn 10;
BA_ "SignalType" SG_ 2155167744 NoReDetInOn "BLN";
BA_ "SignalLongName" SG_ 2155167744 NoReDetInOn "No Remote Detected Indication On";
BA_ "VNSigAllNodes" SG_ 2155167744 NoReDetInOn 1;
BA_ "GenSigSendType" SG_ 2155167744 ApplyCltPdlIO 10;
BA_ "SignalType" SG_ 2155167744 ApplyCltPdlIO "BLN";
BA_ "SignalLongName" SG_ 2155167744 ApplyCltPdlIO "Apply Clutch Pedal Indication On";
BA_ "VNSigAllNodes" SG_ 2155167744 ApplyCltPdlIO 1;
BA_ "GenSigSendType" SG_ 2155167744 VehMovState 10;
BA_ "GenSigSendOnInit" SG_ 2155167744 VehMovState 1;
BA_ "SignalType" SG_ 2155167744 VehMovState "ENM";
BA_ "SignalLongName" SG_ 2155167744 VehMovState "Vehicle Movement State";
BA_ "VNSigAllNodes" SG_ 2155167744 VehMovState 1;
BA_ "GenSigSendType" SG_ 2155167744 TrStLgMdAtv 10;
BA_ "GenSigSendOnInit" SG_ 2155167744 TrStLgMdAtv 1;
BA_ "VNSigInfotainment" SG_ 2155167744 TrStLgMdAtv 1;
BA_ "SignalType" SG_ 2155167744 TrStLgMdAtv "BLN";
BA_ "SignalLongName" SG_ 2155167744 TrStLgMdAtv "Transport Storage Logistic Mode Active";
BA_ "VNSigAllNodes" SG_ 2155167744 TrStLgMdAtv 1;
BA_ "GenSigSendType" SG_ 2155167744 TransModInactIO 10;
BA_ "SignalType" SG_ 2155167744 TransModInactIO "BLN";
BA_ "SignalLongName" SG_ 2155167744 TransModInactIO "Transport Mode Inactive Indication On";
BA_ "VNSigAllNodes" SG_ 2155167744 TransModInactIO 1;
BA_ "GenSigSendType" SG_ 2155167744 TransModActIO 10;
BA_ "SignalType" SG_ 2155167744 TransModActIO "BLN";
BA_ "SignalLongName" SG_ 2155167744 TransModActIO "Transport Mode Active Indication On";
BA_ "VNSigAllNodes" SG_ 2155167744 TransModActIO 1;
BA_ "GenSigSendType" SG_ 2155167744 ApplyBrkPdlIO 10;
BA_ "SignalType" SG_ 2155167744 ApplyBrkPdlIO "BLN";
BA_ "SignalLongName" SG_ 2155167744 ApplyBrkPdlIO "Apply Brake Pedal Indication On";
BA_ "VNSigAllNodes" SG_ 2155167744 ApplyBrkPdlIO 1;
BA_ "GenSigSendType" SG_ 2155167744 Ky_IdDevPr 10;
BA_ "GenSigSendOnInit" SG_ 2155167744 Ky_IdDevPr 1;
BA_ "VNSigInfotainment" SG_ 2155167744 Ky_IdDevPr 1;
BA_ "VNSigIntermediate" SG_ 2155167744 Ky_IdDevPr 1;
BA_ "SignalType" SG_ 2155167744 Ky_IdDevPr "BLN";
BA_ "SignalLongName" SG_ 2155167744 Ky_IdDevPr "Key / Identification Device Present";
BA_ "VNSigAllNodes" SG_ 2155167744 Ky_IdDevPr 1;
BA_ "GenSigSendType" SG_ 2155167744 KylsStrtUseTxPckIO 10;
BA_ "SignalType" SG_ 2155167744 KylsStrtUseTxPckIO "BLN";
BA_ "SignalLongName" SG_ 2155167744 KylsStrtUseTxPckIO "Keyless Start Use Transmitter Pocket Indication On";
BA_ "VNSigAllNodes" SG_ 2155167744 KylsStrtUseTxPckIO 1;
BA_ "GenSigSendType" SG_ 2155167744 ShftPrkIO 10;
BA_ "SignalType" SG_ 2155167744 ShftPrkIO "BLN";
BA_ "SignalLongName" SG_ 2155167744 ShftPrkIO "Shift to Park Indication On";
BA_ "VNSigAllNodes" SG_ 2155167744 ShftPrkIO 1;
BA_ "GenSigSendType" SG_ 2154921984 RFRmtCntFobNm 10;
BA_ "SignalType" SG_ 2154921984 RFRmtCntFobNm "ENM";
BA_ "PacketOrder" SG_ 2154921984 RFRmtCntFobNm 1;
BA_ "SignalLongName" SG_ 2154921984 RFRmtCntFobNm "RFA Function : Remote Control Fob Number";
BA_ "VNSigAllNodes" SG_ 2154921984 RFRmtCntFobNm 1;
BA_ "GenSigSendType" SG_ 2154921984 RFRmtCntrlFobFnc 10;
BA_ "SignalType" SG_ 2154921984 RFRmtCntrlFobFnc "ENM";
BA_ "PacketOrder" SG_ 2154921984 RFRmtCntrlFobFnc 2;
BA_ "SignalLongName" SG_ 2154921984 RFRmtCntrlFobFnc "RFA Function : Remote Control Fob Function";
BA_ "VNSigAllNodes" SG_ 2154921984 RFRmtCntrlFobFnc 1;
BA_ "GenSigSendType" SG_ 2154921984 RFRmtCntFobBatLw 10;
BA_ "SignalType" SG_ 2154921984 RFRmtCntFobBatLw "BLN";
BA_ "PacketOrder" SG_ 2154921984 RFRmtCntFobBatLw 3;
BA_ "SignalLongName" SG_ 2154921984 RFRmtCntFobBatLw "RFA Function : Remote Control Fob Battery Low";
BA_ "VNSigAllNodes" SG_ 2154921984 RFRmtCntFobBatLw 1;
BA_ "GenSigSendType" SG_ 2154921984 FobPogLimRchdIndOn 10;
BA_ "SignalType" SG_ 2154921984 FobPogLimRchdIndOn "BLN";
BA_ "SignalLongName" SG_ 2154921984 FobPogLimRchdIndOn "Fob Programming Limit Reached Indication On";
BA_ "VNSigAllNodes" SG_ 2154921984 FobPogLimRchdIndOn 1;
BA_ "GenSigSendType" SG_ 2151317504 PrkAstRrSysStat 10;
BA_ "SignalType" SG_ 2151317504 PrkAstRrSysStat "ENM";
BA_ "SignalLongName" SG_ 2151317504 PrkAstRrSysStat "Parking Assistance Rear System Status";
BA_ "VNSigAllNodes" SG_ 2151317504 PrkAstRrSysStat 1;
BA_ "GenSigSendType" SG_ 2151317504 PARrRgn4ObjStat 10;
BA_ "SignalType" SG_ 2151317504 PARrRgn4ObjStat "ENM";
BA_ "SignalLongName" SG_ 2151317504 PARrRgn4ObjStat "Parking Assistance Rear Region 4 Object Status";
BA_ "VNSigAllNodes" SG_ 2151317504 PARrRgn4ObjStat 1;
BA_ "GenSigSendType" SG_ 2151317504 PARrRgn3ObjStat 10;
BA_ "SignalType" SG_ 2151317504 PARrRgn3ObjStat "ENM";
BA_ "SignalLongName" SG_ 2151317504 PARrRgn3ObjStat "Parking Assistance Rear Region 3 Object Status";
BA_ "VNSigAllNodes" SG_ 2151317504 PARrRgn3ObjStat 1;
BA_ "GenSigSendType" SG_ 2151317504 PARrRgn2ObjStat 10;
BA_ "SignalType" SG_ 2151317504 PARrRgn2ObjStat "ENM";
BA_ "SignalLongName" SG_ 2151317504 PARrRgn2ObjStat "Parking Assistance Rear Region 2 Object Status";
BA_ "VNSigAllNodes" SG_ 2151317504 PARrRgn2ObjStat 1;
BA_ "GenSigSendType" SG_ 2151317504 PARrRgn1ObjStat 10;
BA_ "SignalType" SG_ 2151317504 PARrRgn1ObjStat "ENM";
BA_ "SignalLongName" SG_ 2151317504 PARrRgn1ObjStat "Parking Assistance Rear Region 1 Object Status";
BA_ "VNSigAllNodes" SG_ 2151317504 PARrRgn1ObjStat 1;
BA_ "GenSigDeltaValue" SG_ 2151317504 PrkAsstRrExtdDist 1;
BA_ "GenSigSendType" SG_ 2151317504 PrkAsstRrExtdDist 12;
BA_ "SignalType" SG_ 2151317504 PrkAsstRrExtdDist "UNM";
BA_ "SignalLongName" SG_ 2151317504 PrkAsstRrExtdDist "Parking Assistance Rear Extended Distance";
BA_ "VNSigAllNodes" SG_ 2151317504 PrkAsstRrExtdDist 1;
BA_ "GenSigSendType" SG_ 2151301120 PrkAsstRrOffIO 10;
BA_ "SignalType" SG_ 2151301120 PrkAsstRrOffIO "BLN";
BA_ "SignalLongName" SG_ 2151301120 PrkAsstRrOffIO "Parking Assistance Rear Off Indication On";
BA_ "VNSigAllNodes" SG_ 2151301120 PrkAsstRrOffIO 1;
BA_ "GenSigSendType" SG_ 2151301120 PrkAstAdvSysAct 10;
BA_ "SignalType" SG_ 2151301120 PrkAstAdvSysAct "BLN";
BA_ "SignalLongName" SG_ 2151301120 PrkAstAdvSysAct "Parking Assistance Advanced  System Active";
BA_ "VNSigAllNodes" SG_ 2151301120 PrkAstAdvSysAct 1;
BA_ "GenSigSendType" SG_ 2151301120 PrkAstFrSysStat 10;
BA_ "GenSigSendOnInit" SG_ 2151301120 PrkAstFrSysStat 2;
BA_ "SignalType" SG_ 2151301120 PrkAstFrSysStat "ENM";
BA_ "SignalLongName" SG_ 2151301120 PrkAstFrSysStat "Parking Assistance Front System Status";
BA_ "VNSigAllNodes" SG_ 2151301120 PrkAstFrSysStat 1;
BA_ "GenSigSendType" SG_ 2151301120 PAFrtRgn4ObjStat 10;
BA_ "SignalType" SG_ 2151301120 PAFrtRgn4ObjStat "ENM";
BA_ "SignalLongName" SG_ 2151301120 PAFrtRgn4ObjStat "Parking Assistance Front Region 4 Object Status";
BA_ "VNSigAllNodes" SG_ 2151301120 PAFrtRgn4ObjStat 1;
BA_ "GenSigSendType" SG_ 2151301120 PAFrtRgn3ObjStat 10;
BA_ "SignalType" SG_ 2151301120 PAFrtRgn3ObjStat "ENM";
BA_ "SignalLongName" SG_ 2151301120 PAFrtRgn3ObjStat "Parking Assistance Front Region 3 Object Status";
BA_ "VNSigAllNodes" SG_ 2151301120 PAFrtRgn3ObjStat 1;
BA_ "GenSigSendType" SG_ 2151301120 PAFrtRgn2ObjStat 10;
BA_ "SignalType" SG_ 2151301120 PAFrtRgn2ObjStat "ENM";
BA_ "SignalLongName" SG_ 2151301120 PAFrtRgn2ObjStat "Parking Assistance Front Region 2 Object Status";
BA_ "VNSigAllNodes" SG_ 2151301120 PAFrtRgn2ObjStat 1;
BA_ "GenSigSendType" SG_ 2151301120 PAFrtRgn1ObjStat 10;
BA_ "SignalType" SG_ 2151301120 PAFrtRgn1ObjStat "ENM";
BA_ "SignalLongName" SG_ 2151301120 PAFrtRgn1ObjStat "Parking Assistance Front Region 1 Object Status";
BA_ "VNSigAllNodes" SG_ 2151301120 PAFrtRgn1ObjStat 1;
BA_ "GenSigDeltaValue" SG_ 2151301120 PrkAsstFrtExtdDist 1;
BA_ "GenSigSendType" SG_ 2151301120 PrkAsstFrtExtdDist 12;
BA_ "SignalType" SG_ 2151301120 PrkAsstFrtExtdDist "UNM";
BA_ "SignalLongName" SG_ 2151301120 PrkAsstFrtExtdDist "Parking Assistance Front Extended Distance";
BA_ "VNSigAllNodes" SG_ 2151301120 PrkAsstFrtExtdDist 1;
BA_ "GenSigDeltaValue" SG_ 2159083520 ODI_TEL2IPC 1;
BA_ "GenSigSendType" SG_ 2159083520 ODI_TEL2IPC 12;
BA_ "VNSigInfotainment" SG_ 2159083520 ODI_TEL2IPC 1;
BA_ "SignalType" SG_ 2159083520 ODI_TEL2IPC "UNM";
BA_ "SignalLongName" SG_ 2159083520 ODI_TEL2IPC "Open Display Interface TEL 2 IPC";
BA_ "VNSigAllNodes" SG_ 2159083520 ODI_TEL2IPC 1;
BA_ "GenSigSendType" SG_ 2153922560 HtrVlvRqstdPstn 10;
BA_ "SignalType" SG_ 2153922560 HtrVlvRqstdPstn "ENM";
BA_ "SignalLongName" SG_ 2153922560 HtrVlvRqstdPstn "Heater Valve Requested Position";
BA_ "VNSigAllNodes" SG_ 2153922560 HtrVlvRqstdPstn 1;
BA_ "GenSigSendType" SG_ 2153922560 ClntHtrElecPwrRatV 10;
BA_ "SignalType" SG_ 2153922560 ClntHtrElecPwrRatV "ENM";
BA_ "SignalLongName" SG_ 2153922560 ClntHtrElecPwrRatV "Coolant Heater Electrical Power Rationalized Validity";
BA_ "VNSigAllNodes" SG_ 2153922560 ClntHtrElecPwrRatV 1;
BA_ "GenSigDeltaValue" SG_ 2153922560 ClntHtrElecPwrRat 1;
BA_ "GenSigSendType" SG_ 2153922560 ClntHtrElecPwrRat 12;
BA_ "SignalType" SG_ 2153922560 ClntHtrElecPwrRat "UNM";
BA_ "SignalLongName" SG_ 2153922560 ClntHtrElecPwrRat "Coolant Heater Electrical Power Rationalized";
BA_ "VNSigAllNodes" SG_ 2153922560 ClntHtrElecPwrRat 1;
BA_ "GenSigDeltaValue" SG_ 2153922560 ClmCtrHiVltPwrRqtd 1;
BA_ "GenSigSendType" SG_ 2153922560 ClmCtrHiVltPwrRqtd 12;
BA_ "GenSigSendOnInit" SG_ 2153922560 ClmCtrHiVltPwrRqtd 1;
BA_ "SignalType" SG_ 2153922560 ClmCtrHiVltPwrRqtd "UNM";
BA_ "SignalLongName" SG_ 2153922560 ClmCtrHiVltPwrRqtd "Climate Control High Voltage Power Requested";
BA_ "VNSigAllNodes" SG_ 2153922560 ClmCtrHiVltPwrRqtd 1;
BA_ "GenSigSendType" SG_ 2153922560 ClmtCtrlHtrEngRunRq 10;
BA_ "SignalType" SG_ 2153922560 ClmtCtrlHtrEngRunRq "ENM";
BA_ "SignalLongName" SG_ 2153922560 ClmtCtrlHtrEngRunRq "Climate Control Heater Engine Run Request";
BA_ "VNSigAllNodes" SG_ 2153922560 ClmtCtrlHtrEngRunRq 1;
BA_ "GenSigSendType" SG_ 2153922560 ClimCtrlVoltBstModReq 10;
BA_ "GenSigSendOnInit" SG_ 2153922560 ClimCtrlVoltBstModReq 1;
BA_ "SignalType" SG_ 2153922560 ClimCtrlVoltBstModReq "BLN";
BA_ "SignalLongName" SG_ 2153922560 ClimCtrlVoltBstModReq "Climate Control Voltage Boost Mode Requested";
BA_ "VNSigAllNodes" SG_ 2153922560 ClimCtrlVoltBstModReq 1;
BA_ "GenSigSendType" SG_ 2153807872 PsvStrtStrngClmnLckTT 10;
BA_ "SignalType" SG_ 2153807872 PsvStrtStrngClmnLckTT "ENM";
BA_ "SignalLongName" SG_ 2153807872 PsvStrtStrngClmnLckTT "Passive Start Steering Column Lock Telltale";
BA_ "VNSigAllNodes" SG_ 2153807872 PsvStrtStrngClmnLckTT 1;
BA_ "GenSigSendType" SG_ 2153807872 ClmSysAuxFlrIndOn 10;
BA_ "SignalType" SG_ 2153807872 ClmSysAuxFlrIndOn "BLN";
BA_ "SignalLongName" SG_ 2153807872 ClmSysAuxFlrIndOn "Column System Auxiliary Failure Indication On";
BA_ "VNSigAllNodes" SG_ 2153807872 ClmSysAuxFlrIndOn 1;
BA_ "GenSigSendType" SG_ 2153807872 PsDoorOpenSwActV 10;
BA_ "SignalType" SG_ 2153807872 PsDoorOpenSwActV "ENM";
BA_ "SignalLongName" SG_ 2153807872 PsDoorOpenSwActV "Passenger Door Open Switch Active Validity";
BA_ "VNSigAllNodes" SG_ 2153807872 PsDoorOpenSwActV 1;
BA_ "GenSigSendType" SG_ 2153807872 PsDoorOpenSwAct 10;
BA_ "GenSigSendOnInit" SG_ 2153807872 PsDoorOpenSwAct 1;
BA_ "SignalType" SG_ 2153807872 PsDoorOpenSwAct "BLN";
BA_ "SignalLongName" SG_ 2153807872 PsDoorOpenSwAct "Passenger Door Open Switch Active";
BA_ "VNSigAllNodes" SG_ 2153807872 PsDoorOpenSwAct 1;
BA_ "GenSigSendType" SG_ 2153807872 DrDoorOpenSwActV 10;
BA_ "SignalType" SG_ 2153807872 DrDoorOpenSwActV "ENM";
BA_ "SignalLongName" SG_ 2153807872 DrDoorOpenSwActV "Driver Door Open Switch Active Validity";
BA_ "VNSigAllNodes" SG_ 2153807872 DrDoorOpenSwActV 1;
BA_ "GenSigSendType" SG_ 2153807872 DrDoorOpenSwAct 10;
BA_ "GenSigSendOnInit" SG_ 2153807872 DrDoorOpenSwAct 1;
BA_ "SignalType" SG_ 2153807872 DrDoorOpenSwAct "BLN";
BA_ "SignalLongName" SG_ 2153807872 DrDoorOpenSwAct "Driver Door Open Switch Active";
BA_ "VNSigAllNodes" SG_ 2153807872 DrDoorOpenSwAct 1;
BA_ "GenSigSendType" SG_ 2150703104 AudSysVNoisCompPres 10;
BA_ "GenSigSendOnInit" SG_ 2150703104 AudSysVNoisCompPres 1;
BA_ "VNSigInfotainment" SG_ 2150703104 AudSysVNoisCompPres 1;
BA_ "SignalType" SG_ 2150703104 AudSysVNoisCompPres "BLN";
BA_ "SignalLongName" SG_ 2150703104 AudSysVNoisCompPres "Audio System Vehicle Noise Compression Present";
BA_ "VNSigAllNodes" SG_ 2150703104 AudSysVNoisCompPres 1;
BA_ "GenSigSendType" SG_ 2150703104 AudSysSurSndSysPres 10;
BA_ "GenSigSendOnInit" SG_ 2150703104 AudSysSurSndSysPres 1;
BA_ "VNSigInfotainment" SG_ 2150703104 AudSysSurSndSysPres 1;
BA_ "SignalType" SG_ 2150703104 AudSysSurSndSysPres "BLN";
BA_ "SignalLongName" SG_ 2150703104 AudSysSurSndSysPres "Audio System Surround Sound System Present";
BA_ "VNSigAllNodes" SG_ 2150703104 AudSysSurSndSysPres 1;
BA_ "GenSigSendType" SG_ 2150703104 AudSysDigSigProcPres 10;
BA_ "GenSigSendOnInit" SG_ 2150703104 AudSysDigSigProcPres 1;
BA_ "VNSigInfotainment" SG_ 2150703104 AudSysDigSigProcPres 1;
BA_ "SignalType" SG_ 2150703104 AudSysDigSigProcPres "BLN";
BA_ "SignalLongName" SG_ 2150703104 AudSysDigSigProcPres "Audio System Digital Signal Processing Present";
BA_ "VNSigAllNodes" SG_ 2150703104 AudSysDigSigProcPres 1;
BA_ "GenSigSendType" SG_ 2151399424 VhlFlRngLwIO 10;
BA_ "GenSigSendOnInit" SG_ 2151399424 VhlFlRngLwIO 2;
BA_ "SignalType" SG_ 2151399424 VhlFlRngLwIO "BLN";
BA_ "SignalLongName" SG_ 2151399424 VhlFlRngLwIO "Vehicle Fuel Range Low Indication On";
BA_ "VNSigAllNodes" SG_ 2151399424 VhlFlRngLwIO 1;
BA_ "GenSigSendType" SG_ 2151399424 WshFldLw 10;
BA_ "GenSigSendOnInit" SG_ 2151399424 WshFldLw 1;
BA_ "SignalType" SG_ 2151399424 WshFldLw "BLN";
BA_ "SignalLongName" SG_ 2151399424 WshFldLw "Washer Fluid Low";
BA_ "VNSigAllNodes" SG_ 2151399424 WshFldLw 1;
BA_ "GenSigDeltaValue" SG_ 2151956480 StrWhlThbwhlCnts 1;
BA_ "GenSigSendType" SG_ 2151956480 StrWhlThbwhlCnts 12;
BA_ "VNSigInfotainment" SG_ 2151956480 StrWhlThbwhlCnts 1;
BA_ "SignalType" SG_ 2151956480 StrWhlThbwhlCnts "SNM";
BA_ "SignalLongName" SG_ 2151956480 StrWhlThbwhlCnts "Steering Wheel Thumbwheel Counts";
BA_ "VNSigAllNodes" SG_ 2151956480 StrWhlThbwhlCnts 1;
BA_ "GenSigSendType" SG_ 2151956480 ClstrHMIRdy 10;
BA_ "GenSigSendOnInit" SG_ 2151956480 ClstrHMIRdy 1;
BA_ "VNSigInfotainment" SG_ 2151956480 ClstrHMIRdy 1;
BA_ "SignalType" SG_ 2151956480 ClstrHMIRdy "BLN";
BA_ "SignalLongName" SG_ 2151956480 ClstrHMIRdy "Cluster HMI Ready";
BA_ "VNSigAllNodes" SG_ 2151956480 ClstrHMIRdy 1;
BA_ "GenSigSendType" SG_ 2151956480 ClstrHMIAnmSt 10;
BA_ "GenSigSendOnInit" SG_ 2151956480 ClstrHMIAnmSt 1;
BA_ "VNSigInfotainment" SG_ 2151956480 ClstrHMIAnmSt 1;
BA_ "SignalType" SG_ 2151956480 ClstrHMIAnmSt "ENM";
BA_ "SignalLongName" SG_ 2151956480 ClstrHMIAnmSt "Cluster HMI Animation State";
BA_ "VNSigAllNodes" SG_ 2151956480 ClstrHMIAnmSt 1;
BA_ "GenSigDeltaValue" SG_ 2151956480 DrvWrkldLvl 1;
BA_ "GenSigSendType" SG_ 2151956480 DrvWrkldLvl 12;
BA_ "SignalType" SG_ 2151956480 DrvWrkldLvl "UNM";
BA_ "SignalLongName" SG_ 2151956480 DrvWrkldLvl "Driver Workload Level";
BA_ "VNSigAllNodes" SG_ 2151956480 DrvWrkldLvl 1;
BA_ "GenSigSendType" SG_ 2151940096 EstIntHorzDshSrfTmpM 10;
BA_ "SignalType" SG_ 2151940096 EstIntHorzDshSrfTmpM "ENM";
BA_ "SignalLongName" SG_ 2151940096 EstIntHorzDshSrfTmpM "Estimated Interior Horizontal Dash Surface Temperature Mask";
BA_ "VNSigAllNodes" SG_ 2151940096 EstIntHorzDshSrfTmpM 1;
BA_ "GenSigDeltaValue" SG_ 2151940096 EstIntHorzDshSrfTmp 1;
BA_ "GenSigSendType" SG_ 2151940096 EstIntHorzDshSrfTmp 12;
BA_ "SignalType" SG_ 2151940096 EstIntHorzDshSrfTmp "UNM";
BA_ "SignalLongName" SG_ 2151940096 EstIntHorzDshSrfTmp "Estimated Interior Horizontal Dash Surface Temperature";
BA_ "VNSigAllNodes" SG_ 2151940096 EstIntHorzDshSrfTmp 1;
BA_ "GenSigSendType" SG_ 2151940096 EstIntRfSrfcTmpV 10;
BA_ "SignalType" SG_ 2151940096 EstIntRfSrfcTmpV "ENM";
BA_ "SignalLongName" SG_ 2151940096 EstIntRfSrfcTmpV "Estimated Interior Roof Surface Temperature Validity";
BA_ "VNSigAllNodes" SG_ 2151940096 EstIntRfSrfcTmpV 1;
BA_ "GenSigDeltaValue" SG_ 2151940096 EstIntRfSrfcTmp 1;
BA_ "GenSigSendType" SG_ 2151940096 EstIntRfSrfcTmp 12;
BA_ "SignalType" SG_ 2151940096 EstIntRfSrfcTmp "UNM";
BA_ "SignalLongName" SG_ 2151940096 EstIntRfSrfcTmp "Estimated Interior Roof Surface Temperature";
BA_ "VNSigAllNodes" SG_ 2151940096 EstIntRfSrfcTmp 1;
BA_ "GenSigSendType" SG_ 2151940096 EstBulkIntAirTmpV 10;
BA_ "SignalType" SG_ 2151940096 EstBulkIntAirTmpV "ENM";
BA_ "SignalLongName" SG_ 2151940096 EstBulkIntAirTmpV "Estimated Bulk Interior Air Temperature Validity";
BA_ "VNSigAllNodes" SG_ 2151940096 EstBulkIntAirTmpV 1;
BA_ "GenSigDeltaValue" SG_ 2151940096 EstBulkIntAirTmp 1;
BA_ "GenSigSendType" SG_ 2151940096 EstBulkIntAirTmp 12;
BA_ "SignalType" SG_ 2151940096 EstBulkIntAirTmp "UNM";
BA_ "SignalLongName" SG_ 2151940096 EstBulkIntAirTmp "Estimated Bulk Interior Air Temperature";
BA_ "VNSigAllNodes" SG_ 2151940096 EstBulkIntAirTmp 1;
BA_ "GenSigDeltaValue" SG_ 2151940096 A2ERRAlrmTime 1;
BA_ "GenSigSendType" SG_ 2151940096 A2ERRAlrmTime 12;
BA_ "VNSigIntermediate" SG_ 2151940096 A2ERRAlrmTime 1;
BA_ "SignalType" SG_ 2151940096 A2ERRAlrmTime "UNM";
BA_ "PacketOrder" SG_ 2151940096 A2ERRAlrmTime 2;
BA_ "SignalLongName" SG_ 2151940096 A2ERRAlrmTime "Alarm 2 Extended Range Request : Alarm Time";
BA_ "VNSigAllNodes" SG_ 2151940096 A2ERRAlrmTime 1;
BA_ "GenSigSendType" SG_ 2151940096 A2ERRAlrmReq 10;
BA_ "VNSigIntermediate" SG_ 2151940096 A2ERRAlrmReq 1;
BA_ "SignalType" SG_ 2151940096 A2ERRAlrmReq "ENM";
BA_ "PacketOrder" SG_ 2151940096 A2ERRAlrmReq 1;
BA_ "SignalLongName" SG_ 2151940096 A2ERRAlrmReq "Alarm 2 Extended Range Request : Alarm Request";
BA_ "VNSigAllNodes" SG_ 2151940096 A2ERRAlrmReq 1;
BA_ "GenSigSendType" SG_ 2151923712 HLOCCstCurrSetVal 10;
BA_ "GenSigSendOnInit" SG_ 2151923712 HLOCCstCurrSetVal 2;
BA_ "SignalType" SG_ 2151923712 HLOCCstCurrSetVal "ENM";
BA_ "SignalLongName" SG_ 2151923712 HLOCCstCurrSetVal "Handfree Liftgate Open Close Customization Current Setting Value";
BA_ "VNSigAllNodes" SG_ 2151923712 HLOCCstCurrSetVal 1;
BA_ "GenSigSendType" SG_ 2151923712 HLOCCstSetAvail 10;
BA_ "GenSigSendOnInit" SG_ 2151923712 HLOCCstSetAvail 2;
BA_ "SignalType" SG_ 2151923712 HLOCCstSetAvail "BLN";
BA_ "SignalLongName" SG_ 2151923712 HLOCCstSetAvail "Handsfree Liftgate Open Close Customization Setting Available";
BA_ "VNSigAllNodes" SG_ 2151923712 HLOCCstSetAvail 1;
BA_ "GenSigSendType" SG_ 2151923712 HLOCCA_Res4Avail 10;
BA_ "GenSigSendOnInit" SG_ 2151923712 HLOCCA_Res4Avail 2;
BA_ "SignalType" SG_ 2151923712 HLOCCA_Res4Avail "BLN";
BA_ "PacketOrder" SG_ 2151923712 HLOCCA_Res4Avail 7;
BA_ "SignalLongName" SG_ 2151923712 HLOCCA_Res4Avail "Handsfree Liftgate Open Close Customization Available : Reserved 4 Available";
BA_ "VNSigAllNodes" SG_ 2151923712 HLOCCA_Res4Avail 1;
BA_ "GenSigSendType" SG_ 2151923712 HLOCCA_Res3Avail 10;
BA_ "GenSigSendOnInit" SG_ 2151923712 HLOCCA_Res3Avail 2;
BA_ "SignalType" SG_ 2151923712 HLOCCA_Res3Avail "BLN";
BA_ "PacketOrder" SG_ 2151923712 HLOCCA_Res3Avail 6;
BA_ "SignalLongName" SG_ 2151923712 HLOCCA_Res3Avail "Handsfree Liftgate Open Close Customization Available : Reserved 3 Available";
BA_ "VNSigAllNodes" SG_ 2151923712 HLOCCA_Res3Avail 1;
BA_ "GenSigSendType" SG_ 2151923712 HLOCCA_Res2Avail 10;
BA_ "GenSigSendOnInit" SG_ 2151923712 HLOCCA_Res2Avail 2;
BA_ "SignalType" SG_ 2151923712 HLOCCA_Res2Avail "BLN";
BA_ "PacketOrder" SG_ 2151923712 HLOCCA_Res2Avail 5;
BA_ "SignalLongName" SG_ 2151923712 HLOCCA_Res2Avail "Handsfree Liftgate Open Close Customization Available : Reserved 2 Available";
BA_ "VNSigAllNodes" SG_ 2151923712 HLOCCA_Res2Avail 1;
BA_ "GenSigSendType" SG_ 2151923712 HLOCCA_Res1Avail 10;
BA_ "GenSigSendOnInit" SG_ 2151923712 HLOCCA_Res1Avail 2;
BA_ "SignalType" SG_ 2151923712 HLOCCA_Res1Avail "BLN";
BA_ "PacketOrder" SG_ 2151923712 HLOCCA_Res1Avail 4;
BA_ "SignalLongName" SG_ 2151923712 HLOCCA_Res1Avail "Handsfree Liftgate Open Close Customization Available : Reserved 1 Available";
BA_ "VNSigAllNodes" SG_ 2151923712 HLOCCA_Res1Avail 1;
BA_ "GenSigSendType" SG_ 2151923712 HLOCCA_OnOpnOnlyAvail 10;
BA_ "GenSigSendOnInit" SG_ 2151923712 HLOCCA_OnOpnOnlyAvail 2;
BA_ "SignalType" SG_ 2151923712 HLOCCA_OnOpnOnlyAvail "BLN";
BA_ "PacketOrder" SG_ 2151923712 HLOCCA_OnOpnOnlyAvail 3;
BA_ "SignalLongName" SG_ 2151923712 HLOCCA_OnOpnOnlyAvail "Handsfree Liftgate Open Close Customization Available : On Open Only Available";
BA_ "VNSigAllNodes" SG_ 2151923712 HLOCCA_OnOpnOnlyAvail 1;
BA_ "GenSigSendType" SG_ 2151923712 HLOCCA_OnAvail 10;
BA_ "GenSigSendOnInit" SG_ 2151923712 HLOCCA_OnAvail 2;
BA_ "SignalType" SG_ 2151923712 HLOCCA_OnAvail "BLN";
BA_ "PacketOrder" SG_ 2151923712 HLOCCA_OnAvail 2;
BA_ "SignalLongName" SG_ 2151923712 HLOCCA_OnAvail "Handsfree Liftgate Open Close Customization Available : On Available";
BA_ "VNSigAllNodes" SG_ 2151923712 HLOCCA_OnAvail 1;
BA_ "GenSigSendType" SG_ 2151923712 HLOCCA_OffAvail 10;
BA_ "GenSigSendOnInit" SG_ 2151923712 HLOCCA_OffAvail 2;
BA_ "SignalType" SG_ 2151923712 HLOCCA_OffAvail "BLN";
BA_ "PacketOrder" SG_ 2151923712 HLOCCA_OffAvail 1;
BA_ "SignalLongName" SG_ 2151923712 HLOCCA_OffAvail "Handsfree Liftgate Open Close Customization Available : Off Available";
BA_ "VNSigAllNodes" SG_ 2151923712 HLOCCA_OffAvail 1;
BA_ "GenSigDeltaValue" SG_ 2151923712 A1ERRAlrmTime 1;
BA_ "GenSigSendType" SG_ 2151923712 A1ERRAlrmTime 12;
BA_ "SignalType" SG_ 2151923712 A1ERRAlrmTime "UNM";
BA_ "PacketOrder" SG_ 2151923712 A1ERRAlrmTime 2;
BA_ "SignalLongName" SG_ 2151923712 A1ERRAlrmTime "Alarm 1 Extended Range Request : Alarm Time";
BA_ "VNSigAllNodes" SG_ 2151923712 A1ERRAlrmTime 1;
BA_ "GenSigSendType" SG_ 2151923712 A1ERRAlrmReq 10;
BA_ "SignalType" SG_ 2151923712 A1ERRAlrmReq "ENM";
BA_ "PacketOrder" SG_ 2151923712 A1ERRAlrmReq 1;
BA_ "SignalLongName" SG_ 2151923712 A1ERRAlrmReq "Alarm 1 Extended Range Request : Alarm Request";
BA_ "VNSigAllNodes" SG_ 2151923712 A1ERRAlrmReq 1;
BA_ "GenSigSendType" SG_ 2150645760 EnvIdRspSt1 10;
BA_ "SignalType" SG_ 2150645760 EnvIdRspSt1 "ENM";
BA_ "SignalLongName" SG_ 2150645760 EnvIdRspSt1 "Environment Identification Response Status 1";
BA_ "VNSigAllNodes" SG_ 2150645760 EnvIdRspSt1 1;
BA_ "GenSigDeltaValue" SG_ 2150645760 EnvIdRsp1 1;
BA_ "GenSigSendType" SG_ 2150645760 EnvIdRsp1 12;
BA_ "SignalType" SG_ 2150645760 EnvIdRsp1 "UNM";
BA_ "SignalLongName" SG_ 2150645760 EnvIdRsp1 "Environment Identification Response 1";
BA_ "VNSigAllNodes" SG_ 2150645760 EnvIdRsp1 1;
BA_ "GenSigSendType" SG_ 2152464384 RtLnDepWrnSt 10;
BA_ "SignalType" SG_ 2152464384 RtLnDepWrnSt "ENM";
BA_ "SignalLongName" SG_ 2152464384 RtLnDepWrnSt "Right Lane Departure Warning Status";
BA_ "VNSigAllNodes" SG_ 2152464384 RtLnDepWrnSt 1;
BA_ "GenSigSendType" SG_ 2152464384 LftLnDepWrnSt 10;
BA_ "SignalType" SG_ 2152464384 LftLnDepWrnSt "ENM";
BA_ "SignalLongName" SG_ 2152464384 LftLnDepWrnSt "Left Lane Departure Warning Status";
BA_ "VNSigAllNodes" SG_ 2152464384 LftLnDepWrnSt 1;
BA_ "GenSigSendType" SG_ 2152464384 TnDrvLDWOffUnbIO 10;
BA_ "SignalType" SG_ 2152464384 TnDrvLDWOffUnbIO "BLN";
BA_ "SignalLongName" SG_ 2152464384 TnDrvLDWOffUnbIO "Teen Driver Lane Departure Warning Off Unavailable Indication On";
BA_ "VNSigAllNodes" SG_ 2152464384 TnDrvLDWOffUnbIO 1;
BA_ "GenSigSendType" SG_ 2152464384 SrvcLnKpAstSysIO 10;
BA_ "SignalType" SG_ 2152464384 SrvcLnKpAstSysIO "BLN";
BA_ "SignalLongName" SG_ 2152464384 SrvcLnKpAstSysIO "Service Lane Keeping Assist System Indication On";
BA_ "VNSigAllNodes" SG_ 2152464384 SrvcLnKpAstSysIO 1;
BA_ "GenSigSendType" SG_ 2152464384 HndsOffStrWhlDtIO 10;
BA_ "SignalType" SG_ 2152464384 HndsOffStrWhlDtIO "BLN";
BA_ "SignalLongName" SG_ 2152464384 HndsOffStrWhlDtIO "Hands Off Steering Wheel Detection Indication On";
BA_ "VNSigAllNodes" SG_ 2152464384 HndsOffStrWhlDtIO 1;
BA_ "GenSigSendType" SG_ 2152464384 LnKpAstDisbldIO 10;
BA_ "SignalType" SG_ 2152464384 LnKpAstDisbldIO "BLN";
BA_ "SignalLongName" SG_ 2152464384 LnKpAstDisbldIO "Lane Keeping Assist Disabled Indication On";
BA_ "VNSigAllNodes" SG_ 2152464384 LnKpAstDisbldIO 1;
BA_ "GenSigSendType" SG_ 2152464384 LKAIC_AdbWngLn 10;
BA_ "SignalType" SG_ 2152464384 LKAIC_AdbWngLn "ENM";
BA_ "PacketOrder" SG_ 2152464384 LKAIC_AdbWngLn 4;
BA_ "SignalLongName" SG_ 2152464384 LKAIC_AdbWngLn "Lane Keeping Assist Indication Control : Audible Warning Location";
BA_ "VNSigAllNodes" SG_ 2152464384 LKAIC_AdbWngLn 1;
BA_ "GenSigSendType" SG_ 2152464384 LKAIC_Ind2 10;
BA_ "SignalType" SG_ 2152464384 LKAIC_Ind2 "BLN";
BA_ "PacketOrder" SG_ 2152464384 LKAIC_Ind2 3;
BA_ "SignalLongName" SG_ 2152464384 LKAIC_Ind2 "Lane Keeping Assist Indication Control : Indicator 2";
BA_ "VNSigAllNodes" SG_ 2152464384 LKAIC_Ind2 1;
BA_ "GenSigSendType" SG_ 2152464384 LKAIC_Ind1 10;
BA_ "SignalType" SG_ 2152464384 LKAIC_Ind1 "BLN";
BA_ "PacketOrder" SG_ 2152464384 LKAIC_Ind1 2;
BA_ "SignalLongName" SG_ 2152464384 LKAIC_Ind1 "Lane Keeping Assist Indication Control : Indicator 1";
BA_ "VNSigAllNodes" SG_ 2152464384 LKAIC_Ind1 1;
BA_ "GenSigSendType" SG_ 2152464384 LKAIC_IndReq 10;
BA_ "SignalType" SG_ 2152464384 LKAIC_IndReq "ENM";
BA_ "PacketOrder" SG_ 2152464384 LKAIC_IndReq 1;
BA_ "SignalLongName" SG_ 2152464384 LKAIC_IndReq "Lane Keeping Assist Indication Control : Indication Request";
BA_ "VNSigAllNodes" SG_ 2152464384 LKAIC_IndReq 1;
BA_ "GenSigSendType" SG_ 2152464384 SrvcLaneDepWrnSysIO 10;
BA_ "SignalType" SG_ 2152464384 SrvcLaneDepWrnSysIO "BLN";
BA_ "SignalLongName" SG_ 2152464384 SrvcLaneDepWrnSysIO "Service Lane Departure Warning System Indication On";
BA_ "VNSigAllNodes" SG_ 2152464384 SrvcLaneDepWrnSysIO 1;
BA_ "GenSigSendType" SG_ 2152464384 LDWIC_LnDepWAWLn 10;
BA_ "GenSigSendOnInit" SG_ 2152464384 LDWIC_LnDepWAWLn 2;
BA_ "SignalType" SG_ 2152464384 LDWIC_LnDepWAWLn "ENM";
BA_ "PacketOrder" SG_ 2152464384 LDWIC_LnDepWAWLn 4;
BA_ "SignalLongName" SG_ 2152464384 LDWIC_LnDepWAWLn "Lane Departure Warning Indication Control : Lane Deparature Warning Audible Warning Location";
BA_ "VNSigAllNodes" SG_ 2152464384 LDWIC_LnDepWAWLn 1;
BA_ "GenSigSendType" SG_ 2152464384 LDWIC_Ind2 10;
BA_ "GenSigSendOnInit" SG_ 2152464384 LDWIC_Ind2 2;
BA_ "SignalType" SG_ 2152464384 LDWIC_Ind2 "BLN";
BA_ "PacketOrder" SG_ 2152464384 LDWIC_Ind2 3;
BA_ "SignalLongName" SG_ 2152464384 LDWIC_Ind2 "Lane Departure Warning Indication Control : Indicator 2";
BA_ "VNSigAllNodes" SG_ 2152464384 LDWIC_Ind2 1;
BA_ "GenSigSendType" SG_ 2152464384 LDWIC_Ind1 10;
BA_ "GenSigSendOnInit" SG_ 2152464384 LDWIC_Ind1 2;
BA_ "SignalType" SG_ 2152464384 LDWIC_Ind1 "BLN";
BA_ "PacketOrder" SG_ 2152464384 LDWIC_Ind1 2;
BA_ "SignalLongName" SG_ 2152464384 LDWIC_Ind1 "Lane Departure Warning Indication Control : Indicator 1";
BA_ "VNSigAllNodes" SG_ 2152464384 LDWIC_Ind1 1;
BA_ "GenSigSendType" SG_ 2152464384 LDWIC_IndReq 10;
BA_ "GenSigSendOnInit" SG_ 2152464384 LDWIC_IndReq 2;
BA_ "SignalType" SG_ 2152464384 LDWIC_IndReq "ENM";
BA_ "PacketOrder" SG_ 2152464384 LDWIC_IndReq 1;
BA_ "SignalLongName" SG_ 2152464384 LDWIC_IndReq "Lane Departure Warning Indication Control : Indication Request";
BA_ "VNSigAllNodes" SG_ 2152464384 LDWIC_IndReq 1;
BA_ "GenSigSendType" SG_ 2152464384 LaneDepWrnDisbldIO 10;
BA_ "SignalType" SG_ 2152464384 LaneDepWrnDisbldIO "BLN";
BA_ "SignalLongName" SG_ 2152464384 LaneDepWrnDisbldIO "Lane Departure Warning Disabled Indication On";
BA_ "VNSigAllNodes" SG_ 2152464384 LaneDepWrnDisbldIO 1;
BA_ "GenSigSendType" SG_ 2154971136 PassHCSeatSw3Act 10;
BA_ "GenSigSendOnInit" SG_ 2154971136 PassHCSeatSw3Act 2;
BA_ "SignalType" SG_ 2154971136 PassHCSeatSw3Act "BLN";
BA_ "SignalLongName" SG_ 2154971136 PassHCSeatSw3Act "Passenger Heated/Cooled Seat Switch #3 Active";
BA_ "VNSigAllNodes" SG_ 2154971136 PassHCSeatSw3Act 1;
BA_ "GenSigSendType" SG_ 2154971136 PassHCSeatSw2Act 10;
BA_ "GenSigSendOnInit" SG_ 2154971136 PassHCSeatSw2Act 2;
BA_ "SignalType" SG_ 2154971136 PassHCSeatSw2Act "BLN";
BA_ "SignalLongName" SG_ 2154971136 PassHCSeatSw2Act "Passenger Heated/Cooled Seat Switch #2 Active";
BA_ "VNSigAllNodes" SG_ 2154971136 PassHCSeatSw2Act 1;
BA_ "GenSigSendType" SG_ 2154971136 PassHCSeatSw1Act 10;
BA_ "GenSigSendOnInit" SG_ 2154971136 PassHCSeatSw1Act 2;
BA_ "SignalType" SG_ 2154971136 PassHCSeatSw1Act "BLN";
BA_ "SignalLongName" SG_ 2154971136 PassHCSeatSw1Act "Passenger Heated/Cooled Seat Switch #1 Active";
BA_ "VNSigAllNodes" SG_ 2154971136 PassHCSeatSw1Act 1;
BA_ "GenSigSendType" SG_ 2154971136 DrvHCSeatSw3Act 10;
BA_ "GenSigSendOnInit" SG_ 2154971136 DrvHCSeatSw3Act 2;
BA_ "SignalType" SG_ 2154971136 DrvHCSeatSw3Act "BLN";
BA_ "SignalLongName" SG_ 2154971136 DrvHCSeatSw3Act "Driver Heated/Cooled Seat Switch #3 Active";
BA_ "VNSigAllNodes" SG_ 2154971136 DrvHCSeatSw3Act 1;
BA_ "GenSigSendType" SG_ 2154971136 DrvHCSeatSw2Act 10;
BA_ "GenSigSendOnInit" SG_ 2154971136 DrvHCSeatSw2Act 2;
BA_ "SignalType" SG_ 2154971136 DrvHCSeatSw2Act "BLN";
BA_ "SignalLongName" SG_ 2154971136 DrvHCSeatSw2Act "Driver Heated/Cooled Seat Switch #2 Active";
BA_ "VNSigAllNodes" SG_ 2154971136 DrvHCSeatSw2Act 1;
BA_ "GenSigSendType" SG_ 2154971136 DrvHCSeatSw1Act 10;
BA_ "GenSigSendOnInit" SG_ 2154971136 DrvHCSeatSw1Act 2;
BA_ "SignalType" SG_ 2154971136 DrvHCSeatSw1Act "BLN";
BA_ "SignalLongName" SG_ 2154971136 DrvHCSeatSw1Act "Driver Heated/Cooled Seat Switch #1 Active";
BA_ "VNSigAllNodes" SG_ 2154971136 DrvHCSeatSw1Act 1;
BA_ "GenSigSendType" SG_ 2154962944 PassHCSMInd3 10;
BA_ "GenSigSendOnInit" SG_ 2154962944 PassHCSMInd3 1;
BA_ "SignalType" SG_ 2154962944 PassHCSMInd3 "BLN";
BA_ "PacketOrder" SG_ 2154962944 PassHCSMInd3 4;
BA_ "SignalLongName" SG_ 2154962944 PassHCSMInd3 "Passenger Heated/Cooled Seat Mode Indication Control : Seat Mode Indication 3";
BA_ "VNSigAllNodes" SG_ 2154962944 PassHCSMInd3 1;
BA_ "GenSigSendType" SG_ 2154962944 PassHCSMInd2 10;
BA_ "GenSigSendOnInit" SG_ 2154962944 PassHCSMInd2 1;
BA_ "SignalType" SG_ 2154962944 PassHCSMInd2 "BLN";
BA_ "PacketOrder" SG_ 2154962944 PassHCSMInd2 3;
BA_ "SignalLongName" SG_ 2154962944 PassHCSMInd2 "Passenger Heated/Cooled Seat Mode Indication Control : Seat Mode Indication 2";
BA_ "VNSigAllNodes" SG_ 2154962944 PassHCSMInd2 1;
BA_ "GenSigSendType" SG_ 2154962944 PassHCSMInd1 10;
BA_ "GenSigSendOnInit" SG_ 2154962944 PassHCSMInd1 1;
BA_ "SignalType" SG_ 2154962944 PassHCSMInd1 "BLN";
BA_ "PacketOrder" SG_ 2154962944 PassHCSMInd1 2;
BA_ "SignalLongName" SG_ 2154962944 PassHCSMInd1 "Passenger Heated/Cooled Seat Mode Indication Control : Seat Mode Indication 1";
BA_ "VNSigAllNodes" SG_ 2154962944 PassHCSMInd1 1;
BA_ "GenSigSendType" SG_ 2154962944 PassHCSMIndReq 10;
BA_ "GenSigSendOnInit" SG_ 2154962944 PassHCSMIndReq 1;
BA_ "SignalType" SG_ 2154962944 PassHCSMIndReq "ENM";
BA_ "PacketOrder" SG_ 2154962944 PassHCSMIndReq 1;
BA_ "SignalLongName" SG_ 2154962944 PassHCSMIndReq "Passenger Heated/Cooled Seat Mode Indication Control : Indication Request";
BA_ "VNSigAllNodes" SG_ 2154962944 PassHCSMIndReq 1;
BA_ "GenSigSendType" SG_ 2154962944 PassHCSLSeatLev5 10;
BA_ "GenSigSendOnInit" SG_ 2154962944 PassHCSLSeatLev5 1;
BA_ "SignalType" SG_ 2154962944 PassHCSLSeatLev5 "BLN";
BA_ "PacketOrder" SG_ 2154962944 PassHCSLSeatLev5 6;
BA_ "SignalLongName" SG_ 2154962944 PassHCSLSeatLev5 "Passenger Heated/Cooled Seat Level Indication Control : Seat Level 5";
BA_ "VNSigAllNodes" SG_ 2154962944 PassHCSLSeatLev5 1;
BA_ "GenSigSendType" SG_ 2154962944 PassHCSLSeatLev4 10;
BA_ "GenSigSendOnInit" SG_ 2154962944 PassHCSLSeatLev4 1;
BA_ "SignalType" SG_ 2154962944 PassHCSLSeatLev4 "BLN";
BA_ "PacketOrder" SG_ 2154962944 PassHCSLSeatLev4 5;
BA_ "SignalLongName" SG_ 2154962944 PassHCSLSeatLev4 "Passenger Heated/Cooled Seat Level Indication Control : Seat Level 4";
BA_ "VNSigAllNodes" SG_ 2154962944 PassHCSLSeatLev4 1;
BA_ "GenSigSendType" SG_ 2154962944 PassHCSLSeatLev3 10;
BA_ "GenSigSendOnInit" SG_ 2154962944 PassHCSLSeatLev3 1;
BA_ "SignalType" SG_ 2154962944 PassHCSLSeatLev3 "BLN";
BA_ "PacketOrder" SG_ 2154962944 PassHCSLSeatLev3 4;
BA_ "SignalLongName" SG_ 2154962944 PassHCSLSeatLev3 "Passenger Heated/Cooled Seat Level Indication Control : Seat Level 3";
BA_ "VNSigAllNodes" SG_ 2154962944 PassHCSLSeatLev3 1;
BA_ "GenSigSendType" SG_ 2154962944 PassHCSLSeatLev2 10;
BA_ "GenSigSendOnInit" SG_ 2154962944 PassHCSLSeatLev2 1;
BA_ "SignalType" SG_ 2154962944 PassHCSLSeatLev2 "BLN";
BA_ "PacketOrder" SG_ 2154962944 PassHCSLSeatLev2 3;
BA_ "SignalLongName" SG_ 2154962944 PassHCSLSeatLev2 "Passenger Heated/Cooled Seat Level Indication Control : Seat Level 2";
BA_ "VNSigAllNodes" SG_ 2154962944 PassHCSLSeatLev2 1;
BA_ "GenSigSendType" SG_ 2154962944 PassHCSLSeatLev1 10;
BA_ "GenSigSendOnInit" SG_ 2154962944 PassHCSLSeatLev1 1;
BA_ "SignalType" SG_ 2154962944 PassHCSLSeatLev1 "BLN";
BA_ "PacketOrder" SG_ 2154962944 PassHCSLSeatLev1 2;
BA_ "SignalLongName" SG_ 2154962944 PassHCSLSeatLev1 "Passenger Heated/Cooled Seat Level Indication Control : Seat Level 1";
BA_ "VNSigAllNodes" SG_ 2154962944 PassHCSLSeatLev1 1;
BA_ "GenSigSendType" SG_ 2154962944 PassHCSLIndReq 10;
BA_ "GenSigSendOnInit" SG_ 2154962944 PassHCSLIndReq 1;
BA_ "SignalType" SG_ 2154962944 PassHCSLIndReq "ENM";
BA_ "PacketOrder" SG_ 2154962944 PassHCSLIndReq 1;
BA_ "SignalLongName" SG_ 2154962944 PassHCSLIndReq "Passenger Heated/Cooled Seat Level Indication Control : Indication Request";
BA_ "VNSigAllNodes" SG_ 2154962944 PassHCSLIndReq 1;
BA_ "GenSigSendType" SG_ 2154962944 DrvHCSMInd1 10;
BA_ "GenSigSendOnInit" SG_ 2154962944 DrvHCSMInd1 1;
BA_ "SignalType" SG_ 2154962944 DrvHCSMInd1 "BLN";
BA_ "PacketOrder" SG_ 2154962944 DrvHCSMInd1 2;
BA_ "SignalLongName" SG_ 2154962944 DrvHCSMInd1 "Driver Heated/Cooled Seat Mode Indication Control : Seat Mode Indication 1";
BA_ "VNSigAllNodes" SG_ 2154962944 DrvHCSMInd1 1;
BA_ "GenSigSendType" SG_ 2154962944 DrvHCSMIndReq 10;
BA_ "GenSigSendOnInit" SG_ 2154962944 DrvHCSMIndReq 1;
BA_ "SignalType" SG_ 2154962944 DrvHCSMIndReq "ENM";
BA_ "PacketOrder" SG_ 2154962944 DrvHCSMIndReq 1;
BA_ "SignalLongName" SG_ 2154962944 DrvHCSMIndReq "Driver Heated/Cooled Seat Mode Indication Control : Indication Request";
BA_ "VNSigAllNodes" SG_ 2154962944 DrvHCSMIndReq 1;
BA_ "GenSigSendType" SG_ 2154962944 DrvHCSMInd3 10;
BA_ "GenSigSendOnInit" SG_ 2154962944 DrvHCSMInd3 1;
BA_ "SignalType" SG_ 2154962944 DrvHCSMInd3 "BLN";
BA_ "PacketOrder" SG_ 2154962944 DrvHCSMInd3 4;
BA_ "SignalLongName" SG_ 2154962944 DrvHCSMInd3 "Driver Heated/Cooled Seat Mode Indication Control : Seat Mode Indication 3";
BA_ "VNSigAllNodes" SG_ 2154962944 DrvHCSMInd3 1;
BA_ "GenSigSendType" SG_ 2154962944 DrvHCSMInd2 10;
BA_ "GenSigSendOnInit" SG_ 2154962944 DrvHCSMInd2 1;
BA_ "SignalType" SG_ 2154962944 DrvHCSMInd2 "BLN";
BA_ "PacketOrder" SG_ 2154962944 DrvHCSMInd2 3;
BA_ "SignalLongName" SG_ 2154962944 DrvHCSMInd2 "Driver Heated/Cooled Seat Mode Indication Control : Seat Mode Indication 2";
BA_ "VNSigAllNodes" SG_ 2154962944 DrvHCSMInd2 1;
BA_ "GenSigSendType" SG_ 2154962944 DrvHCSLSeatLev5 10;
BA_ "GenSigSendOnInit" SG_ 2154962944 DrvHCSLSeatLev5 1;
BA_ "SignalType" SG_ 2154962944 DrvHCSLSeatLev5 "BLN";
BA_ "PacketOrder" SG_ 2154962944 DrvHCSLSeatLev5 6;
BA_ "SignalLongName" SG_ 2154962944 DrvHCSLSeatLev5 "Driver Heated/Cooled Seat Level Indication Control : Seat Level 5";
BA_ "VNSigAllNodes" SG_ 2154962944 DrvHCSLSeatLev5 1;
BA_ "GenSigSendType" SG_ 2154962944 DrvHCSLSeatLev4 10;
BA_ "GenSigSendOnInit" SG_ 2154962944 DrvHCSLSeatLev4 1;
BA_ "SignalType" SG_ 2154962944 DrvHCSLSeatLev4 "BLN";
BA_ "PacketOrder" SG_ 2154962944 DrvHCSLSeatLev4 5;
BA_ "SignalLongName" SG_ 2154962944 DrvHCSLSeatLev4 "Driver Heated/Cooled Seat Level Indication Control : Seat Level 4";
BA_ "VNSigAllNodes" SG_ 2154962944 DrvHCSLSeatLev4 1;
BA_ "GenSigSendType" SG_ 2154962944 DrvHCSLSeatLev3 10;
BA_ "GenSigSendOnInit" SG_ 2154962944 DrvHCSLSeatLev3 1;
BA_ "SignalType" SG_ 2154962944 DrvHCSLSeatLev3 "BLN";
BA_ "PacketOrder" SG_ 2154962944 DrvHCSLSeatLev3 4;
BA_ "SignalLongName" SG_ 2154962944 DrvHCSLSeatLev3 "Driver Heated/Cooled Seat Level Indication Control : Seat Level 3";
BA_ "VNSigAllNodes" SG_ 2154962944 DrvHCSLSeatLev3 1;
BA_ "GenSigSendType" SG_ 2154962944 DrvHCSLSeatLev2 10;
BA_ "GenSigSendOnInit" SG_ 2154962944 DrvHCSLSeatLev2 1;
BA_ "SignalType" SG_ 2154962944 DrvHCSLSeatLev2 "BLN";
BA_ "PacketOrder" SG_ 2154962944 DrvHCSLSeatLev2 3;
BA_ "SignalLongName" SG_ 2154962944 DrvHCSLSeatLev2 "Driver Heated/Cooled Seat Level Indication Control : Seat Level 2";
BA_ "VNSigAllNodes" SG_ 2154962944 DrvHCSLSeatLev2 1;
BA_ "GenSigSendType" SG_ 2154962944 DrvHCSLSeatLev1 10;
BA_ "GenSigSendOnInit" SG_ 2154962944 DrvHCSLSeatLev1 1;
BA_ "SignalType" SG_ 2154962944 DrvHCSLSeatLev1 "BLN";
BA_ "PacketOrder" SG_ 2154962944 DrvHCSLSeatLev1 2;
BA_ "SignalLongName" SG_ 2154962944 DrvHCSLSeatLev1 "Driver Heated/Cooled Seat Level Indication Control : Seat Level 1";
BA_ "VNSigAllNodes" SG_ 2154962944 DrvHCSLSeatLev1 1;
BA_ "GenSigSendType" SG_ 2154962944 DrvHCSLIndReq 10;
BA_ "GenSigSendOnInit" SG_ 2154962944 DrvHCSLIndReq 1;
BA_ "SignalType" SG_ 2154962944 DrvHCSLIndReq "ENM";
BA_ "PacketOrder" SG_ 2154962944 DrvHCSLIndReq 1;
BA_ "SignalLongName" SG_ 2154962944 DrvHCSLIndReq "Driver Heated/Cooled Seat Level Indication Control : Indication Request";
BA_ "VNSigAllNodes" SG_ 2154962944 DrvHCSLIndReq 1;
BA_ "GenSigSendType" SG_ 2156232704 ACSAlarm9 10;
BA_ "SignalType" SG_ 2156232704 ACSAlarm9 "ENM";
BA_ "PacketOrder" SG_ 2156232704 ACSAlarm9 10;
BA_ "SignalLongName" SG_ 2156232704 ACSAlarm9 "Alarm Clock Status : Alarm 9";
BA_ "VNSigAllNodes" SG_ 2156232704 ACSAlarm9 1;
BA_ "GenSigSendType" SG_ 2156232704 ACSAlarm8 10;
BA_ "SignalType" SG_ 2156232704 ACSAlarm8 "ENM";
BA_ "PacketOrder" SG_ 2156232704 ACSAlarm8 9;
BA_ "SignalLongName" SG_ 2156232704 ACSAlarm8 "Alarm Clock Status : Alarm 8";
BA_ "VNSigAllNodes" SG_ 2156232704 ACSAlarm8 1;
BA_ "GenSigSendType" SG_ 2156232704 ACSAlarm7 10;
BA_ "SignalType" SG_ 2156232704 ACSAlarm7 "ENM";
BA_ "PacketOrder" SG_ 2156232704 ACSAlarm7 8;
BA_ "SignalLongName" SG_ 2156232704 ACSAlarm7 "Alarm Clock Status : Alarm 7";
BA_ "VNSigAllNodes" SG_ 2156232704 ACSAlarm7 1;
BA_ "GenSigSendType" SG_ 2156232704 ACSAlarm6 10;
BA_ "SignalType" SG_ 2156232704 ACSAlarm6 "ENM";
BA_ "PacketOrder" SG_ 2156232704 ACSAlarm6 7;
BA_ "SignalLongName" SG_ 2156232704 ACSAlarm6 "Alarm Clock Status : Alarm 6";
BA_ "VNSigAllNodes" SG_ 2156232704 ACSAlarm6 1;
BA_ "GenSigSendType" SG_ 2156232704 ACSAlarm5 10;
BA_ "SignalType" SG_ 2156232704 ACSAlarm5 "ENM";
BA_ "PacketOrder" SG_ 2156232704 ACSAlarm5 6;
BA_ "SignalLongName" SG_ 2156232704 ACSAlarm5 "Alarm Clock Status : Alarm 5";
BA_ "VNSigAllNodes" SG_ 2156232704 ACSAlarm5 1;
BA_ "GenSigSendType" SG_ 2156232704 ACSAlarm4 10;
BA_ "SignalType" SG_ 2156232704 ACSAlarm4 "ENM";
BA_ "PacketOrder" SG_ 2156232704 ACSAlarm4 5;
BA_ "SignalLongName" SG_ 2156232704 ACSAlarm4 "Alarm Clock Status : Alarm 4";
BA_ "VNSigAllNodes" SG_ 2156232704 ACSAlarm4 1;
BA_ "GenSigSendType" SG_ 2156232704 ACSAlarm3 10;
BA_ "SignalType" SG_ 2156232704 ACSAlarm3 "ENM";
BA_ "PacketOrder" SG_ 2156232704 ACSAlarm3 4;
BA_ "SignalLongName" SG_ 2156232704 ACSAlarm3 "Alarm Clock Status : Alarm 3";
BA_ "VNSigAllNodes" SG_ 2156232704 ACSAlarm3 1;
BA_ "GenSigSendType" SG_ 2156232704 ACSAlarm2 10;
BA_ "SignalType" SG_ 2156232704 ACSAlarm2 "ENM";
BA_ "PacketOrder" SG_ 2156232704 ACSAlarm2 3;
BA_ "SignalLongName" SG_ 2156232704 ACSAlarm2 "Alarm Clock Status : Alarm 2";
BA_ "VNSigAllNodes" SG_ 2156232704 ACSAlarm2 1;
BA_ "GenSigSendType" SG_ 2156232704 ACSAlarm15 10;
BA_ "SignalType" SG_ 2156232704 ACSAlarm15 "ENM";
BA_ "PacketOrder" SG_ 2156232704 ACSAlarm15 16;
BA_ "SignalLongName" SG_ 2156232704 ACSAlarm15 "Alarm Clock Status : Alarm 15";
BA_ "VNSigAllNodes" SG_ 2156232704 ACSAlarm15 1;
BA_ "GenSigSendType" SG_ 2156232704 ACSAlarm14 10;
BA_ "SignalType" SG_ 2156232704 ACSAlarm14 "ENM";
BA_ "PacketOrder" SG_ 2156232704 ACSAlarm14 15;
BA_ "SignalLongName" SG_ 2156232704 ACSAlarm14 "Alarm Clock Status : Alarm 14";
BA_ "VNSigAllNodes" SG_ 2156232704 ACSAlarm14 1;
BA_ "GenSigSendType" SG_ 2156232704 ACSAlarm13 10;
BA_ "SignalType" SG_ 2156232704 ACSAlarm13 "ENM";
BA_ "PacketOrder" SG_ 2156232704 ACSAlarm13 14;
BA_ "SignalLongName" SG_ 2156232704 ACSAlarm13 "Alarm Clock Status : Alarm 13";
BA_ "VNSigAllNodes" SG_ 2156232704 ACSAlarm13 1;
BA_ "GenSigSendType" SG_ 2156232704 ACSAlarm12 10;
BA_ "SignalType" SG_ 2156232704 ACSAlarm12 "ENM";
BA_ "PacketOrder" SG_ 2156232704 ACSAlarm12 13;
BA_ "SignalLongName" SG_ 2156232704 ACSAlarm12 "Alarm Clock Status : Alarm 12";
BA_ "VNSigAllNodes" SG_ 2156232704 ACSAlarm12 1;
BA_ "GenSigSendType" SG_ 2156232704 ACSAlarm11 10;
BA_ "SignalType" SG_ 2156232704 ACSAlarm11 "ENM";
BA_ "PacketOrder" SG_ 2156232704 ACSAlarm11 12;
BA_ "SignalLongName" SG_ 2156232704 ACSAlarm11 "Alarm Clock Status : Alarm 11";
BA_ "VNSigAllNodes" SG_ 2156232704 ACSAlarm11 1;
BA_ "GenSigSendType" SG_ 2156232704 ACSAlarm10 10;
BA_ "SignalType" SG_ 2156232704 ACSAlarm10 "ENM";
BA_ "PacketOrder" SG_ 2156232704 ACSAlarm10 11;
BA_ "SignalLongName" SG_ 2156232704 ACSAlarm10 "Alarm Clock Status : Alarm 10";
BA_ "VNSigAllNodes" SG_ 2156232704 ACSAlarm10 1;
BA_ "GenSigSendType" SG_ 2156232704 ACSAlarm1 10;
BA_ "SignalType" SG_ 2156232704 ACSAlarm1 "ENM";
BA_ "PacketOrder" SG_ 2156232704 ACSAlarm1 2;
BA_ "SignalLongName" SG_ 2156232704 ACSAlarm1 "Alarm Clock Status : Alarm 1";
BA_ "VNSigAllNodes" SG_ 2156232704 ACSAlarm1 1;
BA_ "GenSigSendType" SG_ 2156232704 ACSAlarm0 10;
BA_ "SignalType" SG_ 2156232704 ACSAlarm0 "ENM";
BA_ "PacketOrder" SG_ 2156232704 ACSAlarm0 1;
BA_ "SignalLongName" SG_ 2156232704 ACSAlarm0 "Alarm Clock Status : Alarm 0";
BA_ "VNSigAllNodes" SG_ 2156232704 ACSAlarm0 1;
BA_ "GenSigSendType" SG_ 2154987520 WrlsChrgSysChrgStat 10;
BA_ "GenSigSendOnInit" SG_ 2154987520 WrlsChrgSysChrgStat 2;
BA_ "SignalType" SG_ 2154987520 WrlsChrgSysChrgStat "ENM";
BA_ "SignalLongName" SG_ 2154987520 WrlsChrgSysChrgStat "Wireless Charging System Charging Status";
BA_ "VNSigAllNodes" SG_ 2154987520 WrlsChrgSysChrgStat 1;
BA_ "GenSigSendType" SG_ 2154987520 HdStV 10;
BA_ "SignalType" SG_ 2154987520 HdStV "ENM";
BA_ "SignalLongName" SG_ 2154987520 HdStV "Hood Status Validity";
BA_ "VNSigAllNodes" SG_ 2154987520 HdStV 1;
BA_ "GenSigSendType" SG_ 2154987520 HdSt 10;
BA_ "GenSigSendOnInit" SG_ 2154987520 HdSt 2;
BA_ "SignalType" SG_ 2154987520 HdSt "ENM";
BA_ "SignalLongName" SG_ 2154987520 HdSt "Hood Status";
BA_ "VNSigAllNodes" SG_ 2154987520 HdSt 1;
BA_ "GenSigSendType" SG_ 2154840064 CmpsZnNvrSet 10;
BA_ "GenSigSendOnInit" SG_ 2154840064 CmpsZnNvrSet 1;
BA_ "SignalType" SG_ 2154840064 CmpsZnNvrSet "BLN";
BA_ "SignalLongName" SG_ 2154840064 CmpsZnNvrSet "Compass Zone Never Set";
BA_ "VNSigAllNodes" SG_ 2154840064 CmpsZnNvrSet 1;
BA_ "GenSigSendType" SG_ 2154840064 CmpsSatrtd 10;
BA_ "GenSigSendOnInit" SG_ 2154840064 CmpsSatrtd 1;
BA_ "SignalType" SG_ 2154840064 CmpsSatrtd "BLN";
BA_ "SignalLongName" SG_ 2154840064 CmpsSatrtd "Compass Saturated";
BA_ "VNSigAllNodes" SG_ 2154840064 CmpsSatrtd 1;
BA_ "GenSigSendType" SG_ 2154840064 CmpsDecZone 10;
BA_ "GenSigSendOnInit" SG_ 2154840064 CmpsDecZone 1;
BA_ "SignalType" SG_ 2154840064 CmpsDecZone "ENM";
BA_ "SignalLongName" SG_ 2154840064 CmpsDecZone "Compass Declination Zone";
BA_ "VNSigAllNodes" SG_ 2154840064 CmpsDecZone 1;
BA_ "GenSigSendType" SG_ 2154840064 CmpsOctHdingDataSrc 10;
BA_ "GenSigSendOnInit" SG_ 2154840064 CmpsOctHdingDataSrc 1;
BA_ "SignalType" SG_ 2154840064 CmpsOctHdingDataSrc "ENM";
BA_ "SignalLongName" SG_ 2154840064 CmpsOctHdingDataSrc "Compass Octant Heading Data Source";
BA_ "VNSigAllNodes" SG_ 2154840064 CmpsOctHdingDataSrc 1;
BA_ "GenSigSendType" SG_ 2154840064 CmpsOctHding 10;
BA_ "GenSigSendOnInit" SG_ 2154840064 CmpsOctHding 1;
BA_ "SignalType" SG_ 2154840064 CmpsOctHding "ENM";
BA_ "SignalLongName" SG_ 2154840064 CmpsOctHding "Compass Octant Heading";
BA_ "VNSigAllNodes" SG_ 2154840064 CmpsOctHding 1;
BA_ "GenSigSendType" SG_ 2154840064 CmpsModManCalInPrc 10;
BA_ "GenSigSendOnInit" SG_ 2154840064 CmpsModManCalInPrc 1;
BA_ "SignalType" SG_ 2154840064 CmpsModManCalInPrc "BLN";
BA_ "SignalLongName" SG_ 2154840064 CmpsModManCalInPrc "Compass Module Manual Calibration In Process";
BA_ "VNSigAllNodes" SG_ 2154840064 CmpsModManCalInPrc 1;
BA_ "GenSigSendType" SG_ 2154840064 CmpsModFltPrs 10;
BA_ "GenSigSendOnInit" SG_ 2154840064 CmpsModFltPrs 1;
BA_ "SignalType" SG_ 2154840064 CmpsModFltPrs "BLN";
BA_ "SignalLongName" SG_ 2154840064 CmpsModFltPrs "Compass Module Fault Present";
BA_ "VNSigAllNodes" SG_ 2154840064 CmpsModFltPrs 1;
BA_ "GenSigDeltaValue" SG_ 2154840064 CmpsCrHding 1;
BA_ "GenSigSendType" SG_ 2154840064 CmpsCrHding 12;
BA_ "GenSigSendOnInit" SG_ 2154840064 CmpsCrHding 1;
BA_ "SignalType" SG_ 2154840064 CmpsCrHding "UNM";
BA_ "SignalLongName" SG_ 2154840064 CmpsCrHding "Compass Corrected Heading";
BA_ "VNSigAllNodes" SG_ 2154840064 CmpsCrHding 1;
BA_ "GenSigSendType" SG_ 2154676224 CmpsModSlfTstReq 10;
BA_ "SignalType" SG_ 2154676224 CmpsModSlfTstReq "ENM";
BA_ "SignalLongName" SG_ 2154676224 CmpsModSlfTstReq "Compass Module Self Test Request";
BA_ "VNSigAllNodes" SG_ 2154676224 CmpsModSlfTstReq 1;
BA_ "GenSigSendType" SG_ 2154676224 CmpsModManCalReq 10;
BA_ "SignalType" SG_ 2154676224 CmpsModManCalReq "ENM";
BA_ "SignalLongName" SG_ 2154676224 CmpsModManCalReq "Compass Module Manual Calibration Request";
BA_ "VNSigAllNodes" SG_ 2154676224 CmpsModManCalReq 1;
BA_ "GenSigSendType" SG_ 2154676224 CmpsDecZonSetReq 10;
BA_ "SignalType" SG_ 2154676224 CmpsDecZonSetReq "ENM";
BA_ "SignalLongName" SG_ 2154676224 CmpsDecZonSetReq "Compass Declination Zone Set Request";
BA_ "VNSigAllNodes" SG_ 2154676224 CmpsDecZonSetReq 1;
BA_ "GenSigSendType" SG_ 2154676224 CmpsDecZonCmndVal 10;
BA_ "SignalType" SG_ 2154676224 CmpsDecZonCmndVal "ENM";
BA_ "SignalLongName" SG_ 2154676224 CmpsDecZonCmndVal "Compass Declination Zone Commanded Value";
BA_ "VNSigAllNodes" SG_ 2154676224 CmpsDecZonCmndVal 1;
BA_ "GenSigSendType" SG_ 2154643456 HtrCoreInltClntTmpCalcV 10;
BA_ "SignalType" SG_ 2154643456 HtrCoreInltClntTmpCalcV "ENM";
BA_ "SignalLongName" SG_ 2154643456 HtrCoreInltClntTmpCalcV "Heater Core Inlet Coolant Temperature Calculated Validity";
BA_ "VNSigAllNodes" SG_ 2154643456 HtrCoreInltClntTmpCalcV 1;
BA_ "GenSigDeltaValue" SG_ 2154643456 HtrCoreInltClntTmpCalc 1;
BA_ "GenSigSendType" SG_ 2154643456 HtrCoreInltClntTmpCalc 12;
BA_ "SignalType" SG_ 2154643456 HtrCoreInltClntTmpCalc "UNM";
BA_ "SignalLongName" SG_ 2154643456 HtrCoreInltClntTmpCalc "Heater Core Inlet Coolant Temperature Calculated";
BA_ "VNSigAllNodes" SG_ 2154643456 HtrCoreInltClntTmpCalc 1;
BA_ "GenSigSendType" SG_ 2154643456 AuxHtrAtv 10;
BA_ "SignalType" SG_ 2154643456 AuxHtrAtv "BLN";
BA_ "SignalLongName" SG_ 2154643456 AuxHtrAtv "Auxiliary Heater Active";
BA_ "VNSigAllNodes" SG_ 2154643456 AuxHtrAtv 1;
BA_ "GenSigDeltaValue" SG_ 2154643456 CCClntCrcFlwRtReq 1;
BA_ "GenSigSendType" SG_ 2154643456 CCClntCrcFlwRtReq 12;
BA_ "GenSigSendOnInit" SG_ 2154643456 CCClntCrcFlwRtReq 2;
BA_ "SignalType" SG_ 2154643456 CCClntCrcFlwRtReq "UNM";
BA_ "SignalLongName" SG_ 2154643456 CCClntCrcFlwRtReq "Climate Control Coolant Circulation Flow Rate Request";
BA_ "VNSigAllNodes" SG_ 2154643456 CCClntCrcFlwRtReq 1;
BA_REL_ "GenSigSuprvResp" BU_SG_REL_ EOCM2B_K1_LS SG_ 2156789760 TimeDispFormat 1;
BA_REL_ "GenSigSuprvResp" BU_SG_REL_ EOCM2A_K1_LS SG_ 2156789760 TimeDispFormat 1;
BA_REL_ "GenSigSuprvResp" BU_SG_REL_ VPM_LS SG_ 2156789760 TimeDispFormat 1;
BA_REL_ "GenSigSuprvResp" BU_SG_REL_ EOCM2B_K1_LS SG_ 2156789760 CldrYr 1;
BA_REL_ "GenSigSuprvResp" BU_SG_REL_ EOCM2A_K1_LS SG_ 2156789760 CldrYr 1;
BA_REL_ "GenSigSuprvResp" BU_SG_REL_ VPM_LS SG_ 2156789760 CldrYr 1;
BA_REL_ "GenSigSuprvResp" BU_SG_REL_ EOCM2B_K1_LS SG_ 2156789760 CldrMth 1;
BA_REL_ "GenSigSuprvResp" BU_SG_REL_ EOCM2A_K1_LS SG_ 2156789760 CldrMth 1;
BA_REL_ "GenSigSuprvResp" BU_SG_REL_ VPM_LS SG_ 2156789760 CldrMth 1;
BA_REL_ "GenSigSuprvResp" BU_SG_REL_ EOCM2B_K1_LS SG_ 2156789760 CldrDay 1;
BA_REL_ "GenSigSuprvResp" BU_SG_REL_ EOCM2A_K1_LS SG_ 2156789760 CldrDay 1;
BA_REL_ "GenSigSuprvResp" BU_SG_REL_ VPM_LS SG_ 2156789760 CldrDay 1;
BA_REL_ "GenSigSuprvResp" BU_SG_REL_ EOCM2B_K1_LS SG_ 2156789760 TOD_SecofMin 1;
BA_REL_ "GenSigSuprvResp" BU_SG_REL_ EOCM2A_K1_LS SG_ 2156789760 TOD_SecofMin 1;
BA_REL_ "GenSigSuprvResp" BU_SG_REL_ VPM_LS SG_ 2156789760 TOD_SecofMin 1;
BA_REL_ "GenSigSuprvResp" BU_SG_REL_ LVMPC_LS SG_ 2156789760 TOD_SecofMin 1;
BA_REL_ "GenSigSuprvResp" BU_SG_REL_ FCM_LS SG_ 2156789760 TOD_SecofMin 1;
BA_REL_ "GenSigSuprvResp" BU_SG_REL_ EOCM2B_K1_LS SG_ 2156789760 TOD_MinofHr 1;
BA_REL_ "GenSigSuprvResp" BU_SG_REL_ EOCM2A_K1_LS SG_ 2156789760 TOD_MinofHr 1;
BA_REL_ "GenSigSuprvResp" BU_SG_REL_ VPM_LS SG_ 2156789760 TOD_MinofHr 1;
BA_REL_ "GenSigSuprvResp" BU_SG_REL_ LVMPC_LS SG_ 2156789760 TOD_MinofHr 1;
BA_REL_ "GenSigSuprvResp" BU_SG_REL_ FCM_LS SG_ 2156789760 TOD_MinofHr 1;
BA_REL_ "GenSigSuprvResp" BU_SG_REL_ EOCM2B_K1_LS SG_ 2156789760 TOD_HrofDay 1;
BA_REL_ "GenSigSuprvResp" BU_SG_REL_ EOCM2A_K1_LS SG_ 2156789760 TOD_HrofDay 1;
BA_REL_ "GenSigSuprvResp" BU_SG_REL_ VPM_LS SG_ 2156789760 TOD_HrofDay 1;
BA_REL_ "GenSigSuprvResp" BU_SG_REL_ LVMPC_LS SG_ 2156789760 TOD_HrofDay 1;
BA_REL_ "GenSigSuprvResp" BU_SG_REL_ FCM_LS SG_ 2156789760 TOD_HrofDay 1;
BA_REL_ "GenSigSuprvResp" BU_SG_REL_ TCP_LS SG_ 2155020288 LngSelExt 1;
BA_REL_ "GenSigSuprvResp" BU_SG_REL_ VPM_LS SG_ 2155020288 LngSelExt 1;
BA_REL_ "GenSigSuprvResp" BU_SG_REL_ IPC_LS SG_ 2150432768 GrdBrkgAct 1;
BA_REL_ "GenSigSuprvResp" BU_SG_REL_ ECC_LS SG_ 2150432768 EngManfldAirTempCrtd 1;
BA_REL_ "GenSigSuprvResp" BU_SG_REL_ CSM_LS SG_ 2150432768 FuelTotCap 1;
BA_REL_ "GenSigSuprvResp" BU_SG_REL_ RadioHead_LS SG_ 2150432768 FuelTotCap 1;
BA_REL_ "GenSigSuprvResp" BU_SG_REL_ RadioHead_LS SG_ 2150432768 FuelTotCap 1;
BA_REL_ "GenSigSuprvResp" BU_SG_REL_ BCM_LS SG_ 2155298816 TrPrsMntrTrLdRstRqstd 1;
BA_REL_ "GenSigSuprvResp" BU_SG_REL_ V2V_LS SG_ 2154692608 LgclAVChnl 1;
BA_REL_ "GenSigSuprvResp" BU_SG_REL_ ISRVM_LS SG_ 2154692608 LgclAVChnl 1;
BA_REL_ "GenSigSuprvResp" BU_SG_REL_ HBSM_LS SG_ 2154692608 LgclAVChnl 1;
BA_REL_ "GenSigSuprvResp" BU_SG_REL_ TCP_LS SG_ 2154627072 AudMstrArbCom 1;
BA_REL_ "GenSigSuprvResp" BU_SG_REL_ DVB_T_LS SG_ 2154627072 AudMstrArbCom 1;
BA_REL_ "GenSigSuprvResp" BU_SG_REL_ UHP_Low SG_ 2154627072 AudMstrArbCom 1;
BA_REL_ "GenSigSuprvResp" BU_SG_REL_ ONSTAR_LS SG_ 2154627072 AudMstrArbCom 1;
BA_REL_ "GenSigSuprvResp" BU_SG_REL_ BCM_LS SG_ 2151112704 FrPasSeatbltRemOccSt 1;
BA_REL_ "GenSigSuprvResp" BU_SG_REL_ CSM_LS SG_ 2151112704 FrPasSeatbltRemOccSt 1;
BA_REL_ "GenSigSuprvResp" BU_SG_REL_ RadioHead_LS SG_ 2151112704 FrPasSeatbltRemOccSt 1;
BA_REL_ "GenSigSuprvResp" BU_SG_REL_ SDM_LS SG_ 2151112704 FrPasSeatbltRemOccSt 1;
BA_REL_ "GenSigSuprvResp" BU_SG_REL_ SDM_LS SG_ 2151112704 FrPasSeatResCtrlOccStV 1;
BA_REL_ "GenSigSuprvResp" BU_SG_REL_ CSM_LS SG_ 2151112704 FrPasSeatResCtrlOccSt 1;
BA_REL_ "GenSigSuprvResp" BU_SG_REL_ RadioHead_LS SG_ 2151112704 FrPasSeatResCtrlOccSt 1;
BA_REL_ "GenSigVBitResp" BU_SG_REL_ SDM_LS SG_ 2151112704 FrPasSeatResCtrlOccSt 1;
BA_REL_ "GenSigSuprvResp" BU_SG_REL_ SDM_LS SG_ 2151112704 FrPasSeatResCtrlOccSt 1;
BA_REL_ "GenSigSuprvResp" BU_SG_REL_ SDM_LS SG_ 2151112704 FrPsSeatOccSnsOpMd 1;
BA_REL_ "GenSigSuprvResp" BU_SG_REL_ CSM_LS SG_ 2151112704 FrPsSeatOccFltSt 1;
BA_REL_ "GenSigSuprvResp" BU_SG_REL_ MSM_P_LS SG_ 2151112704 FrPsSeatOccFltSt 1;
BA_REL_ "GenSigSuprvResp" BU_SG_REL_ MSM_LS SG_ 2151112704 FrPsSeatOccFltSt 1;
BA_REL_ "GenSigSuprvResp" BU_SG_REL_ RadioHead_LS SG_ 2151112704 FrPsSeatOccFltSt 1;
BA_REL_ "GenSigSuprvResp" BU_SG_REL_ SDM_LS SG_ 2151112704 FrPsSeatOccFltSt 1;
BA_REL_ "GenSigSuprvResp" BU_SG_REL_ CSM_LS SG_ 2151112704 FrntPassClass 1;
BA_REL_ "GenSigSuprvResp" BU_SG_REL_ MSM_P_LS SG_ 2151112704 FrntPassClass 1;
BA_REL_ "GenSigSuprvResp" BU_SG_REL_ MSM_LS SG_ 2151112704 FrntPassClass 1;
BA_REL_ "GenSigSuprvResp" BU_SG_REL_ RadioHead_LS SG_ 2151112704 FrntPassClass 1;
BA_REL_ "GenSigSuprvResp" BU_SG_REL_ SDM_LS SG_ 2151112704 FrntPassClass 1;
BA_REL_ "GenSigSuprvResp" BU_SG_REL_ BCM_LS SG_ 2153938944 RmtRflshMdReqtd 1;
BA_REL_ "GenSigSuprvResp" BU_SG_REL_ EOCM2B_K1_LS SG_ 2150850560 PsSbltAtc 1;
BA_REL_ "GenSigSuprvResp" BU_SG_REL_ EOCM2A_K1_LS SG_ 2150850560 PsSbltAtc 1;
BA_REL_ "GenSigSuprvResp" BU_SG_REL_ V2V_LS SG_ 2150850560 PsSbltAtc 1;
BA_REL_ "GenSigSuprvResp" BU_SG_REL_ ECC_LS SG_ 2150850560 PsSbltAtc 1;
BA_REL_ "GenSigVBitResp" BU_SG_REL_ AOS_LS SG_ 2150850560 PsSbltAtc 1;
BA_REL_ "GenSigSuprvResp" BU_SG_REL_ AOS_LS SG_ 2150850560 PsSbltAtc 1;
BA_REL_ "GenSigSuprvResp" BU_SG_REL_ EOCM2B_K1_LS SG_ 2150850560 DrSbltAtc 1;
BA_REL_ "GenSigSuprvResp" BU_SG_REL_ EOCM2A_K1_LS SG_ 2150850560 DrSbltAtc 1;
BA_REL_ "GenSigSuprvResp" BU_SG_REL_ FCM_LS SG_ 2150850560 DrSbltAtc 1;
BA_REL_ "GenSigSuprvResp" BU_SG_REL_ V2V_LS SG_ 2150850560 DrSbltAtc 1;
BA_REL_ "GenSigSuprvResp" BU_SG_REL_ EOCM_F_LS SG_ 2150850560 DrSbltAtc 1;
BA_REL_ "GenSigVBitResp" BU_SG_REL_ BCM_LS SG_ 2154659840 ClmnLckStat 1;
BA_REL_ "GenSigSuprvResp" BU_SG_REL_ BCM_LS SG_ 2154659840 ClmnLckStat 1;
BA_REL_ "GenSigVBitResp" BU_SG_REL_ BCM_LS SG_ 2154659840 ClmnLckStat 1;
BA_REL_ "GenSigSuprvResp" BU_SG_REL_ BCM_LS SG_ 2154659840 ClmnLckStat 1;
BA_REL_ "GenSigVBitResp" BU_SG_REL_ BCM_LS SG_ 2154659840 ClmnLckStat 1;
BA_REL_ "GenSigSuprvResp" BU_SG_REL_ BCM_LS SG_ 2154659840 ClmnLckStat 1;
BA_REL_ "GenSigSuprvResp" BU_SG_REL_ HVSM_R_LS SG_ 2155266048 RRHCSeatSw3Act 1;
BA_REL_ "GenSigSuprvResp" BU_SG_REL_ HVSM_R_LS SG_ 2155266048 RRHCSeatSw2Act 1;
BA_REL_ "GenSigSuprvResp" BU_SG_REL_ HVSM_R_LS SG_ 2155266048 RRHCSeatSw1Act 1;
BA_REL_ "GenSigSuprvResp" BU_SG_REL_ HVSM_R_LS SG_ 2155266048 RLHCSeatSw3Act 1;
BA_REL_ "GenSigSuprvResp" BU_SG_REL_ HVSM_R_LS SG_ 2155266048 RLHCSeatSw2Act 1;
BA_REL_ "GenSigSuprvResp" BU_SG_REL_ HVSM_R_LS SG_ 2155266048 RLHCSeatSw1Act 1;
BA_REL_ "GenSigSuprvResp" BU_SG_REL_ RSC_LS SG_ 2155249664 RRHCSMInd3 1;
BA_REL_ "GenSigSuprvResp" BU_SG_REL_ RSA_LS SG_ 2155249664 RRHCSMInd3 1;
BA_REL_ "GenSigSuprvResp" BU_SG_REL_ ECC_LS SG_ 2155249664 RRHCSMInd3 1;
BA_REL_ "GenSigSuprvResp" BU_SG_REL_ BCM_LS SG_ 2155249664 RRHCSMInd3 1;
BA_REL_ "GenSigSuprvResp" BU_SG_REL_ RSC_LS SG_ 2155249664 RRHCSMInd2 1;
BA_REL_ "GenSigSuprvResp" BU_SG_REL_ RSA_LS SG_ 2155249664 RRHCSMInd2 1;
BA_REL_ "GenSigSuprvResp" BU_SG_REL_ ECC_LS SG_ 2155249664 RRHCSMInd2 1;
BA_REL_ "GenSigSuprvResp" BU_SG_REL_ BCM_LS SG_ 2155249664 RRHCSMInd2 1;
BA_REL_ "GenSigSuprvResp" BU_SG_REL_ RSC_LS SG_ 2155249664 RRHCSMInd1 1;
BA_REL_ "GenSigSuprvResp" BU_SG_REL_ RSA_LS SG_ 2155249664 RRHCSMInd1 1;
BA_REL_ "GenSigSuprvResp" BU_SG_REL_ ECC_LS SG_ 2155249664 RRHCSMInd1 1;
BA_REL_ "GenSigSuprvResp" BU_SG_REL_ BCM_LS SG_ 2155249664 RRHCSMInd1 1;
BA_REL_ "GenSigSuprvResp" BU_SG_REL_ RSC_LS SG_ 2155249664 RRHCSMIndReq 1;
BA_REL_ "GenSigSuprvResp" BU_SG_REL_ RSA_LS SG_ 2155249664 RRHCSMIndReq 1;
BA_REL_ "GenSigSuprvResp" BU_SG_REL_ ECC_LS SG_ 2155249664 RRHCSMIndReq 1;
BA_REL_ "GenSigSuprvResp" BU_SG_REL_ BCM_LS SG_ 2155249664 RRHCSMIndReq 1;
BA_REL_ "GenSigSuprvResp" BU_SG_REL_ IPC_LS SG_ 2155249664 RRHCSLSeatLev5 1;
BA_REL_ "GenSigSuprvResp" BU_SG_REL_ RSC_LS SG_ 2155249664 RRHCSLSeatLev5 1;
BA_REL_ "GenSigSuprvResp" BU_SG_REL_ RSA_LS SG_ 2155249664 RRHCSLSeatLev5 1;
BA_REL_ "GenSigSuprvResp" BU_SG_REL_ ECC_LS SG_ 2155249664 RRHCSLSeatLev5 1;
BA_REL_ "GenSigSuprvResp" BU_SG_REL_ BCM_LS SG_ 2155249664 RRHCSLSeatLev5 1;
BA_REL_ "GenSigSuprvResp" BU_SG_REL_ IPC_LS SG_ 2155249664 RRHCSLSeatLev4 1;
BA_REL_ "GenSigSuprvResp" BU_SG_REL_ RSC_LS SG_ 2155249664 RRHCSLSeatLev4 1;
BA_REL_ "GenSigSuprvResp" BU_SG_REL_ RSA_LS SG_ 2155249664 RRHCSLSeatLev4 1;
BA_REL_ "GenSigSuprvResp" BU_SG_REL_ ECC_LS SG_ 2155249664 RRHCSLSeatLev4 1;
BA_REL_ "GenSigSuprvResp" BU_SG_REL_ BCM_LS SG_ 2155249664 RRHCSLSeatLev4 1;
BA_REL_ "GenSigSuprvResp" BU_SG_REL_ IPC_LS SG_ 2155249664 RRHCSLSeatLev3 1;
BA_REL_ "GenSigSuprvResp" BU_SG_REL_ RSC_LS SG_ 2155249664 RRHCSLSeatLev3 1;
BA_REL_ "GenSigSuprvResp" BU_SG_REL_ RSA_LS SG_ 2155249664 RRHCSLSeatLev3 1;
BA_REL_ "GenSigSuprvResp" BU_SG_REL_ ECC_LS SG_ 2155249664 RRHCSLSeatLev3 1;
BA_REL_ "GenSigSuprvResp" BU_SG_REL_ BCM_LS SG_ 2155249664 RRHCSLSeatLev3 1;
BA_REL_ "GenSigSuprvResp" BU_SG_REL_ IPC_LS SG_ 2155249664 RRHCSLSeatLev2 1;
BA_REL_ "GenSigSuprvResp" BU_SG_REL_ RSC_LS SG_ 2155249664 RRHCSLSeatLev2 1;
BA_REL_ "GenSigSuprvResp" BU_SG_REL_ RSA_LS SG_ 2155249664 RRHCSLSeatLev2 1;
BA_REL_ "GenSigSuprvResp" BU_SG_REL_ ECC_LS SG_ 2155249664 RRHCSLSeatLev2 1;
BA_REL_ "GenSigSuprvResp" BU_SG_REL_ BCM_LS SG_ 2155249664 RRHCSLSeatLev2 1;
BA_REL_ "GenSigSuprvResp" BU_SG_REL_ IPC_LS SG_ 2155249664 RRHCSLSeatLev1 1;
BA_REL_ "GenSigSuprvResp" BU_SG_REL_ RSC_LS SG_ 2155249664 RRHCSLSeatLev1 1;
BA_REL_ "GenSigSuprvResp" BU_SG_REL_ RSA_LS SG_ 2155249664 RRHCSLSeatLev1 1;
BA_REL_ "GenSigSuprvResp" BU_SG_REL_ ECC_LS SG_ 2155249664 RRHCSLSeatLev1 1;
BA_REL_ "GenSigSuprvResp" BU_SG_REL_ BCM_LS SG_ 2155249664 RRHCSLSeatLev1 1;
BA_REL_ "GenSigSuprvResp" BU_SG_REL_ IPC_LS SG_ 2155249664 RRHCSLIndReq 1;
BA_REL_ "GenSigSuprvResp" BU_SG_REL_ RSC_LS SG_ 2155249664 RRHCSLIndReq 1;
BA_REL_ "GenSigSuprvResp" BU_SG_REL_ RSA_LS SG_ 2155249664 RRHCSLIndReq 1;
BA_REL_ "GenSigSuprvResp" BU_SG_REL_ ECC_LS SG_ 2155249664 RRHCSLIndReq 1;
BA_REL_ "GenSigSuprvResp" BU_SG_REL_ BCM_LS SG_ 2155249664 RRHCSLIndReq 1;
BA_REL_ "GenSigSuprvResp" BU_SG_REL_ RSC_LS SG_ 2155249664 RLHCSMInd3 1;
BA_REL_ "GenSigSuprvResp" BU_SG_REL_ RSA_LS SG_ 2155249664 RLHCSMInd3 1;
BA_REL_ "GenSigSuprvResp" BU_SG_REL_ ECC_LS SG_ 2155249664 RLHCSMInd3 1;
BA_REL_ "GenSigSuprvResp" BU_SG_REL_ BCM_LS SG_ 2155249664 RLHCSMInd3 1;
BA_REL_ "GenSigSuprvResp" BU_SG_REL_ RSC_LS SG_ 2155249664 RLHCSMInd2 1;
BA_REL_ "GenSigSuprvResp" BU_SG_REL_ RSA_LS SG_ 2155249664 RLHCSMInd2 1;
BA_REL_ "GenSigSuprvResp" BU_SG_REL_ ECC_LS SG_ 2155249664 RLHCSMInd2 1;
BA_REL_ "GenSigSuprvResp" BU_SG_REL_ BCM_LS SG_ 2155249664 RLHCSMInd2 1;
BA_REL_ "GenSigSuprvResp" BU_SG_REL_ RSC_LS SG_ 2155249664 RLHCSMInd1 1;
BA_REL_ "GenSigSuprvResp" BU_SG_REL_ RSA_LS SG_ 2155249664 RLHCSMInd1 1;
BA_REL_ "GenSigSuprvResp" BU_SG_REL_ ECC_LS SG_ 2155249664 RLHCSMInd1 1;
BA_REL_ "GenSigSuprvResp" BU_SG_REL_ BCM_LS SG_ 2155249664 RLHCSMInd1 1;
BA_REL_ "GenSigSuprvResp" BU_SG_REL_ RSC_LS SG_ 2155249664 RLHCSMIndReq 1;
BA_REL_ "GenSigSuprvResp" BU_SG_REL_ RSA_LS SG_ 2155249664 RLHCSMIndReq 1;
BA_REL_ "GenSigSuprvResp" BU_SG_REL_ ECC_LS SG_ 2155249664 RLHCSMIndReq 1;
BA_REL_ "GenSigSuprvResp" BU_SG_REL_ BCM_LS SG_ 2155249664 RLHCSMIndReq 1;
BA_REL_ "GenSigSuprvResp" BU_SG_REL_ IPC_LS SG_ 2155249664 RLHCSLSeatLev5 1;
BA_REL_ "GenSigSuprvResp" BU_SG_REL_ RSC_LS SG_ 2155249664 RLHCSLSeatLev5 1;
BA_REL_ "GenSigSuprvResp" BU_SG_REL_ RSA_LS SG_ 2155249664 RLHCSLSeatLev5 1;
BA_REL_ "GenSigSuprvResp" BU_SG_REL_ ECC_LS SG_ 2155249664 RLHCSLSeatLev5 1;
BA_REL_ "GenSigSuprvResp" BU_SG_REL_ BCM_LS SG_ 2155249664 RLHCSLSeatLev5 1;
BA_REL_ "GenSigSuprvResp" BU_SG_REL_ IPC_LS SG_ 2155249664 RLHCSLSeatLev4 1;
BA_REL_ "GenSigSuprvResp" BU_SG_REL_ RSC_LS SG_ 2155249664 RLHCSLSeatLev4 1;
BA_REL_ "GenSigSuprvResp" BU_SG_REL_ RSA_LS SG_ 2155249664 RLHCSLSeatLev4 1;
BA_REL_ "GenSigSuprvResp" BU_SG_REL_ ECC_LS SG_ 2155249664 RLHCSLSeatLev4 1;
BA_REL_ "GenSigSuprvResp" BU_SG_REL_ BCM_LS SG_ 2155249664 RLHCSLSeatLev4 1;
BA_REL_ "GenSigSuprvResp" BU_SG_REL_ IPC_LS SG_ 2155249664 RLHCSLSeatLev3 1;
BA_REL_ "GenSigSuprvResp" BU_SG_REL_ RSC_LS SG_ 2155249664 RLHCSLSeatLev3 1;
BA_REL_ "GenSigSuprvResp" BU_SG_REL_ RSA_LS SG_ 2155249664 RLHCSLSeatLev3 1;
BA_REL_ "GenSigSuprvResp" BU_SG_REL_ ECC_LS SG_ 2155249664 RLHCSLSeatLev3 1;
BA_REL_ "GenSigSuprvResp" BU_SG_REL_ BCM_LS SG_ 2155249664 RLHCSLSeatLev3 1;
BA_REL_ "GenSigSuprvResp" BU_SG_REL_ IPC_LS SG_ 2155249664 RLHCSLSeatLev2 1;
BA_REL_ "GenSigSuprvResp" BU_SG_REL_ RSC_LS SG_ 2155249664 RLHCSLSeatLev2 1;
BA_REL_ "GenSigSuprvResp" BU_SG_REL_ RSA_LS SG_ 2155249664 RLHCSLSeatLev2 1;
BA_REL_ "GenSigSuprvResp" BU_SG_REL_ ECC_LS SG_ 2155249664 RLHCSLSeatLev2 1;
BA_REL_ "GenSigSuprvResp" BU_SG_REL_ BCM_LS SG_ 2155249664 RLHCSLSeatLev2 1;
BA_REL_ "GenSigSuprvResp" BU_SG_REL_ IPC_LS SG_ 2155249664 RLHCSLSeatLev1 1;
BA_REL_ "GenSigSuprvResp" BU_SG_REL_ RSC_LS SG_ 2155249664 RLHCSLSeatLev1 1;
BA_REL_ "GenSigSuprvResp" BU_SG_REL_ RSA_LS SG_ 2155249664 RLHCSLSeatLev1 1;
BA_REL_ "GenSigSuprvResp" BU_SG_REL_ ECC_LS SG_ 2155249664 RLHCSLSeatLev1 1;
BA_REL_ "GenSigSuprvResp" BU_SG_REL_ BCM_LS SG_ 2155249664 RLHCSLSeatLev1 1;
BA_REL_ "GenSigSuprvResp" BU_SG_REL_ IPC_LS SG_ 2155249664 RLHCSLIndReq 1;
BA_REL_ "GenSigSuprvResp" BU_SG_REL_ RSC_LS SG_ 2155249664 RLHCSLIndReq 1;
BA_REL_ "GenSigSuprvResp" BU_SG_REL_ RSA_LS SG_ 2155249664 RLHCSLIndReq 1;
BA_REL_ "GenSigSuprvResp" BU_SG_REL_ ECC_LS SG_ 2155249664 RLHCSLIndReq 1;
BA_REL_ "GenSigSuprvResp" BU_SG_REL_ BCM_LS SG_ 2155249664 RLHCSLIndReq 1;
BA_REL_ "GenSigSuprvResp" BU_SG_REL_ CSM_LS SG_ 2155184128 TrnsShftLvrLckStat 1;
BA_REL_ "GenSigSuprvResp" BU_SG_REL_ RadioHead_LS SG_ 2155184128 TrnsShftLvrLckStat 1;
BA_REL_ "GenSigSuprvResp" BU_SG_REL_ FCM_LS SG_ 2155184128 CrsCntrlSwStCanSwAct 1;
BA_REL_ "GenSigSuprvResp" BU_SG_REL_ VPM_LS SG_ 2155184128 CrsCntrlSwStCanSwAct 1;
BA_REL_ "GenSigVDAFailComment" BU_SG_REL_ SDM_LS SG_ 2155184128 CrsCntrlSwStCanSwAct "Engine Virtual Device Availability";
BA_REL_ "GenSigVDAFailResp" BU_SG_REL_ SDM_LS SG_ 2155184128 CrsCntrlSwStCanSwAct 1;
BA_REL_ "GenSigSuprvResp" BU_SG_REL_ SDM_LS SG_ 2155184128 CrsCntrlSwStCanSwAct 1;
BA_REL_ "GenSigSuprvResp" BU_SG_REL_ FCM_LS SG_ 2155184128 CrsCntrlSwStSwDataIntgty 1;
BA_REL_ "GenSigSuprvResp" BU_SG_REL_ VPM_LS SG_ 2155184128 CrsCntrlSwStSwDataIntgty 1;
BA_REL_ "GenSigVDAFailComment" BU_SG_REL_ SDM_LS SG_ 2155184128 CrsCntrlSwStSwDataIntgty "Engine Virtual Device Availability";
BA_REL_ "GenSigVDAFailResp" BU_SG_REL_ SDM_LS SG_ 2155184128 CrsCntrlSwStSwDataIntgty 1;
BA_REL_ "GenSigSuprvResp" BU_SG_REL_ SDM_LS SG_ 2155184128 CrsCntrlSwStSwDataIntgty 1;
BA_REL_ "GenSigSuprvResp" BU_SG_REL_ FCM_LS SG_ 2155184128 CrsCntrlSwStSpdInSwAct 1;
BA_REL_ "GenSigSuprvResp" BU_SG_REL_ VPM_LS SG_ 2155184128 CrsCntrlSwStSpdInSwAct 1;
BA_REL_ "GenSigVDAFailComment" BU_SG_REL_ SDM_LS SG_ 2155184128 CrsCntrlSwStSpdInSwAct "Engine Virtual Device Availability";
BA_REL_ "GenSigVDAFailResp" BU_SG_REL_ SDM_LS SG_ 2155184128 CrsCntrlSwStSpdInSwAct 1;
BA_REL_ "GenSigSuprvResp" BU_SG_REL_ SDM_LS SG_ 2155184128 CrsCntrlSwStSpdInSwAct 1;
BA_REL_ "GenSigSuprvResp" BU_SG_REL_ FCM_LS SG_ 2155184128 CrsCntrlSwStSpDcSwAct 1;
BA_REL_ "GenSigSuprvResp" BU_SG_REL_ VPM_LS SG_ 2155184128 CrsCntrlSwStSpDcSwAct 1;
BA_REL_ "GenSigVDAFailComment" BU_SG_REL_ SDM_LS SG_ 2155184128 CrsCntrlSwStSpDcSwAct "Engine Virtual Device Availability";
BA_REL_ "GenSigVDAFailResp" BU_SG_REL_ SDM_LS SG_ 2155184128 CrsCntrlSwStSpDcSwAct 1;
BA_REL_ "GenSigSuprvResp" BU_SG_REL_ SDM_LS SG_ 2155184128 CrsCntrlSwStSpDcSwAct 1;
BA_REL_ "GenSigSuprvResp" BU_SG_REL_ FCM_LS SG_ 2155184128 CrsCntrlSwStSetSwAct 1;
BA_REL_ "GenSigSuprvResp" BU_SG_REL_ VPM_LS SG_ 2155184128 CrsCntrlSwStSetSwAct 1;
BA_REL_ "GenSigVDAFailComment" BU_SG_REL_ SDM_LS SG_ 2155184128 CrsCntrlSwStSetSwAct "Engine Virtual Device Availability";
BA_REL_ "GenSigVDAFailResp" BU_SG_REL_ SDM_LS SG_ 2155184128 CrsCntrlSwStSetSwAct 1;
BA_REL_ "GenSigSuprvResp" BU_SG_REL_ SDM_LS SG_ 2155184128 CrsCntrlSwStSetSwAct 1;
BA_REL_ "GenSigSuprvResp" BU_SG_REL_ FCM_LS SG_ 2155184128 CrsCntrlSwStResSwAct 1;
BA_REL_ "GenSigSuprvResp" BU_SG_REL_ VPM_LS SG_ 2155184128 CrsCntrlSwStResSwAct 1;
BA_REL_ "GenSigVDAFailComment" BU_SG_REL_ SDM_LS SG_ 2155184128 CrsCntrlSwStResSwAct "Engine Virtual Device Availability";
BA_REL_ "GenSigVDAFailResp" BU_SG_REL_ SDM_LS SG_ 2155184128 CrsCntrlSwStResSwAct 1;
BA_REL_ "GenSigSuprvResp" BU_SG_REL_ SDM_LS SG_ 2155184128 CrsCntrlSwStResSwAct 1;
BA_REL_ "GenSigSuprvResp" BU_SG_REL_ FCM_LS SG_ 2155184128 CrsCntrlSwStOnSwAct 1;
BA_REL_ "GenSigSuprvResp" BU_SG_REL_ VPM_LS SG_ 2155184128 CrsCntrlSwStOnSwAct 1;
BA_REL_ "GenSigVDAFailComment" BU_SG_REL_ SDM_LS SG_ 2155184128 CrsCntrlSwStOnSwAct "Engine Virtual Device Availability";
BA_REL_ "GenSigVDAFailResp" BU_SG_REL_ SDM_LS SG_ 2155184128 CrsCntrlSwStOnSwAct 1;
BA_REL_ "GenSigSuprvResp" BU_SG_REL_ SDM_LS SG_ 2155184128 CrsCntrlSwStOnSwAct 1;
BA_REL_ "GenSigSuprvResp" BU_SG_REL_ VIS2_LS SG_ 2155184128 CrsCntAtv 1;
BA_REL_ "GenSigSuprvResp" BU_SG_REL_ FCM_LS SG_ 2155184128 CrsCntAtv 1;
BA_REL_ "GenSigVDAFailComment" BU_SG_REL_ SDM_LS SG_ 2155184128 CrsCntAtv "Engine Virtual Device Availability";
BA_REL_ "GenSigVDAFailResp" BU_SG_REL_ SDM_LS SG_ 2155184128 CrsCntAtv 1;
BA_REL_ "GenSigSuprvResp" BU_SG_REL_ SDM_LS SG_ 2155184128 CrsCntAtv 1;
BA_REL_ "GenSigSuprvResp" BU_SG_REL_ RCRM_LS SG_ 2155167744 VehMovState 1;
BA_REL_ "GenSigSuprvResp" BU_SG_REL_ PEPS_LS SG_ 2155167744 VehMovState 1;
BA_REL_ "GenSigSuprvResp" BU_SG_REL_ MSM_RR_LS SG_ 2155167744 VehMovState 1;
BA_REL_ "GenSigSuprvResp" BU_SG_REL_ MSM_LR_LS SG_ 2155167744 VehMovState 1;
BA_REL_ "GenSigSuprvResp" BU_SG_REL_ VIS2_LS SG_ 2155167744 VehMovState 1;
BA_REL_ "GenSigSuprvResp" BU_SG_REL_ VPM_LS SG_ 2155167744 VehMovState 1;
BA_REL_ "GenSigSuprvResp" BU_SG_REL_ ISRVM_LS SG_ 2155167744 VehMovState 1;
BA_REL_ "GenSigSuprvResp" BU_SG_REL_ FCM_LS SG_ 2155167744 VehMovState 1;
BA_REL_ "GenSigSuprvResp" BU_SG_REL_ PSD_R_LS SG_ 2155167744 VehMovState 1;
BA_REL_ "GenSigSuprvResp" BU_SG_REL_ PSD_L_LS SG_ 2155167744 VehMovState 1;
BA_REL_ "GenSigSuprvResp" BU_SG_REL_ MSM_P_LS SG_ 2155167744 VehMovState 1;
BA_REL_ "GenSigSuprvResp" BU_SG_REL_ MSM_LS SG_ 2155167744 VehMovState 1;
BA_REL_ "GenSigSuprvResp" BU_SG_REL_ UPA_LS SG_ 2155167744 VehMovState 1;
BA_REL_ "GenSigSuprvResp" BU_SG_REL_ APA_LS SG_ 2155167744 VehMovState 1;
BA_REL_ "GenSigSuprvResp" BU_SG_REL_ APA_LS SG_ 2155167744 VehMovState 1;
BA_REL_ "GenSigSuprvResp" BU_SG_REL_ RadioHead_LS SG_ 2155167744 TrStLgMdAtv 1;
BA_REL_ "GenSigSuprvResp" BU_SG_REL_ ONSTAR_LS SG_ 2155167744 Ky_IdDevPr 1;
BA_REL_ "GenSigSuprvResp" BU_SG_REL_ TCP_LS SG_ 2155167744 Ky_IdDevPr 1;
BA_REL_ "GenSigSuprvResp" BU_SG_REL_ IPC_LS SG_ 2155167744 KylsStrtUseTxPckIO 1;
BA_REL_ "GenSigSuprvResp" BU_SG_REL_ ARB_LS SG_ 2154921984 RFRmtCntFobNm 1;
BA_REL_ "GenSigSuprvResp" BU_SG_REL_ PEPS_LS SG_ 2154921984 RFRmtCntFobNm 1;
BA_REL_ "GenSigSuprvResp" BU_SG_REL_ ARB_LS SG_ 2154921984 RFRmtCntrlFobFnc 1;
BA_REL_ "GenSigSuprvResp" BU_SG_REL_ PEPS_LS SG_ 2154921984 RFRmtCntrlFobFnc 1;
BA_REL_ "GenSigSuprvResp" BU_SG_REL_ ARB_LS SG_ 2154921984 RFRmtCntFobBatLw 1;
BA_REL_ "GenSigSuprvResp" BU_SG_REL_ PEPS_LS SG_ 2154921984 RFRmtCntFobBatLw 1;
BA_REL_ "GenSigSuprvResp" BU_SG_REL_ VPM_LS SG_ 2151317504 PrkAstRrSysStat 1;
BA_REL_ "GenSigSuprvResp" BU_SG_REL_ IPC_LS SG_ 2151317504 PrkAstRrSysStat 1;
BA_REL_ "GenSigSuprvResp" BU_SG_REL_ VPM_LS SG_ 2151317504 PARrRgn4ObjStat 1;
BA_REL_ "GenSigSuprvResp" BU_SG_REL_ VPM_LS SG_ 2151317504 PARrRgn3ObjStat 1;
BA_REL_ "GenSigSuprvResp" BU_SG_REL_ VPM_LS SG_ 2151317504 PARrRgn2ObjStat 1;
BA_REL_ "GenSigSuprvResp" BU_SG_REL_ VPM_LS SG_ 2151317504 PARrRgn1ObjStat 1;
BA_REL_ "GenSigSuprvResp" BU_SG_REL_ FCM_LS SG_ 2151301120 PrkAstAdvSysAct 1;
BA_REL_ "GenSigSuprvResp" BU_SG_REL_ EOCM2B_K2_LS SG_ 2151301120 PrkAstAdvSysAct 1;
BA_REL_ "GenSigSuprvResp" BU_SG_REL_ EOCM2A_K2_LS SG_ 2151301120 PrkAstAdvSysAct 1;
BA_REL_ "GenSigSuprvResp" BU_SG_REL_ BCM_LS SG_ 2151301120 PrkAstAdvSysAct 1;
BA_REL_ "GenSigSuprvResp" BU_SG_REL_ EOCM_F_LS SG_ 2151301120 PrkAstAdvSysAct 1;
BA_REL_ "GenSigSuprvResp" BU_SG_REL_ EOCM2B_K2_LS SG_ 2151301120 PrkAstFrSysStat 1;
BA_REL_ "GenSigSuprvResp" BU_SG_REL_ EOCM2A_K2_LS SG_ 2151301120 PrkAstFrSysStat 1;
BA_REL_ "GenSigSuprvResp" BU_SG_REL_ EOCM2B_K2_LS SG_ 2151301120 PAFrtRgn4ObjStat 1;
BA_REL_ "GenSigSuprvResp" BU_SG_REL_ EOCM2A_K2_LS SG_ 2151301120 PAFrtRgn4ObjStat 1;
BA_REL_ "GenSigSuprvResp" BU_SG_REL_ EOCM2B_K2_LS SG_ 2151301120 PAFrtRgn3ObjStat 1;
BA_REL_ "GenSigSuprvResp" BU_SG_REL_ EOCM2A_K2_LS SG_ 2151301120 PAFrtRgn3ObjStat 1;
BA_REL_ "GenSigSuprvResp" BU_SG_REL_ EOCM2B_K2_LS SG_ 2151301120 PAFrtRgn2ObjStat 1;
BA_REL_ "GenSigSuprvResp" BU_SG_REL_ EOCM2A_K2_LS SG_ 2151301120 PAFrtRgn2ObjStat 1;
BA_REL_ "GenSigSuprvResp" BU_SG_REL_ EOCM2B_K2_LS SG_ 2151301120 PAFrtRgn1ObjStat 1;
BA_REL_ "GenSigSuprvResp" BU_SG_REL_ EOCM2A_K2_LS SG_ 2151301120 PAFrtRgn1ObjStat 1;
BA_REL_ "GenSigSuprvResp" BU_SG_REL_ EOCM2B_K2_LS SG_ 2151301120 PrkAsstFrtExtdDist 1;
BA_REL_ "GenSigSuprvResp" BU_SG_REL_ EOCM2A_K2_LS SG_ 2151301120 PrkAsstFrtExtdDist 1;
BA_REL_ "GenSigSuprvResp" BU_SG_REL_ VPM_LS SG_ 2151301120 PrkAsstFrtExtdDist 1;
BA_REL_ "GenSigSuprvResp" BU_SG_REL_ BSM_LS SG_ 2153922560 HtrVlvRqstdPstn 1;
BA_REL_ "GenSigSuprvResp" BU_SG_REL_ VICM_LS SG_ 2153922560 HtrVlvRqstdPstn 1;
BA_REL_ "GenSigSuprvResp" BU_SG_REL_ BSM_LS SG_ 2153922560 ClntHtrElecPwrRat 1;
BA_REL_ "GenSigSuprvResp" BU_SG_REL_ VICM_LS SG_ 2153922560 ClntHtrElecPwrRat 1;
BA_REL_ "GenSigSuprvResp" BU_SG_REL_ BSM_LS SG_ 2153922560 ClmCtrHiVltPwrRqtd 1;
BA_REL_ "GenSigSuprvResp" BU_SG_REL_ VICM_LS SG_ 2153922560 ClmCtrHiVltPwrRqtd 1;
BA_REL_ "GenSigSuprvResp" BU_SG_REL_ BCM_LS SG_ 2153922560 ClmtCtrlHtrEngRunRq 1;
BA_REL_ "GenSigSuprvResp" BU_SG_REL_ BCM_LS SG_ 2153922560 ClimCtrlVoltBstModReq 1;
BA_REL_ "GenSigSuprvResp" BU_SG_REL_ V2V_LS SG_ 2153807872 PsDoorOpenSwAct 1;
BA_REL_ "GenSigSuprvResp" BU_SG_REL_ ARB_LS SG_ 2153807872 PsDoorOpenSwAct 1;
BA_REL_ "GenSigVBitResp" BU_SG_REL_ SCL_LS SG_ 2153807872 PsDoorOpenSwAct 1;
BA_REL_ "GenSigSuprvResp" BU_SG_REL_ SCL_LS SG_ 2153807872 PsDoorOpenSwAct 2;
BA_REL_ "GenSigVBitResp" BU_SG_REL_ BCM_LS SG_ 2153807872 PsDoorOpenSwAct 1;
BA_REL_ "GenSigSuprvResp" BU_SG_REL_ BCM_LS SG_ 2153807872 PsDoorOpenSwAct 1;
BA_REL_ "GenSigSuprvResp" BU_SG_REL_ V2V_LS SG_ 2153807872 DrDoorOpenSwAct 1;
BA_REL_ "GenSigSuprvResp" BU_SG_REL_ FCM_LS SG_ 2153807872 DrDoorOpenSwAct 1;
BA_REL_ "GenSigSuprvResp" BU_SG_REL_ EOCM_F_LS SG_ 2153807872 DrDoorOpenSwAct 1;
BA_REL_ "GenSigSuprvResp" BU_SG_REL_ ARB_LS SG_ 2153807872 DrDoorOpenSwAct 1;
BA_REL_ "GenSigVBitResp" BU_SG_REL_ SCL_LS SG_ 2153807872 DrDoorOpenSwAct 1;
BA_REL_ "GenSigSuprvResp" BU_SG_REL_ SCL_LS SG_ 2153807872 DrDoorOpenSwAct 2;
BA_REL_ "GenSigSuprvResp" BU_SG_REL_ BCM_LS SG_ 2153807872 DrDoorOpenSwAct 1;
BA_REL_ "GenSigVBitResp" BU_SG_REL_ BCM_LS SG_ 2153807872 DrDoorOpenSwAct 1;
BA_REL_ "GenSigSuprvResp" BU_SG_REL_ BCM_LS SG_ 2153807872 DrDoorOpenSwAct 1;
BA_REL_ "GenSigSuprvResp" BU_SG_REL_ RadioHead_LS SG_ 2150703104 AudSysVNoisCompPres 1;
BA_REL_ "GenSigSuprvResp" BU_SG_REL_ RadioHead_LS SG_ 2150703104 AudSysSurSndSysPres 1;
BA_REL_ "GenSigSuprvResp" BU_SG_REL_ RadioHead_LS SG_ 2150703104 AudSysDigSigProcPres 1;
BA_REL_ "GenSigSuprvRespSubValue" BU_SG_REL_ BCM_LS SG_ 2151399424 WshFldLw 1;
BA_REL_ "GenSigSuprvResp" BU_SG_REL_ BCM_LS SG_ 2151399424 WshFldLw 1;
BA_REL_ "GenSigRxStartValue" BU_SG_REL_ RadioHead_LS SG_ 2151956480 StrWhlThbwhlCnts "0";
BA_REL_ "GenSigSuprvResp" BU_SG_REL_ BCM_LS SG_ 2151940096 EstIntHorzDshSrfTmp 1;
BA_REL_ "GenSigSuprvResp" BU_SG_REL_ CSM_LS SG_ 2151940096 EstIntRfSrfcTmp 1;
BA_REL_ "GenSigSuprvResp" BU_SG_REL_ RadioHead_LS SG_ 2151940096 EstIntRfSrfcTmp 1;
BA_REL_ "GenSigSuprvResp" BU_SG_REL_ CSM_LS SG_ 2151940096 EstBulkIntAirTmp 1;
BA_REL_ "GenSigSuprvResp" BU_SG_REL_ RadioHead_LS SG_ 2151940096 EstBulkIntAirTmp 1;
BA_REL_ "GenSigSuprvResp" BU_SG_REL_ IPC_LS SG_ 2152464384 RtLnDepWrnSt 1;
BA_REL_ "GenSigSuprvResp" BU_SG_REL_ IPC_LS SG_ 2152464384 LftLnDepWrnSt 1;
BA_REL_ "GenSigSuprvResp" BU_SG_REL_ IPC_LS SG_ 2152464384 TnDrvLDWOffUnbIO 1;
BA_REL_ "GenSigSuprvResp" BU_SG_REL_ BCM_LS SG_ 2152464384 SrvcLnKpAstSysIO 1;
BA_REL_ "GenSigSuprvResp" BU_SG_REL_ IPC_LS SG_ 2152464384 SrvcLnKpAstSysIO 1;
BA_REL_ "GenSigSuprvResp" BU_SG_REL_ IPC_LS SG_ 2152464384 HndsOffStrWhlDtIO 1;
BA_REL_ "GenSigSuprvResp" BU_SG_REL_ IPC_LS SG_ 2152464384 LnKpAstDisbldIO 1;
BA_REL_ "GenSigSuprvResp" BU_SG_REL_ BCM_LS SG_ 2152464384 LKAIC_AdbWngLn 1;
BA_REL_ "GenSigSuprvResp" BU_SG_REL_ IPC_LS SG_ 2152464384 LKAIC_AdbWngLn 1;
BA_REL_ "GenSigSuprvResp" BU_SG_REL_ BCM_LS SG_ 2152464384 LKAIC_Ind2 1;
BA_REL_ "GenSigSuprvResp" BU_SG_REL_ IPC_LS SG_ 2152464384 LKAIC_Ind2 1;
BA_REL_ "GenSigSuprvResp" BU_SG_REL_ BCM_LS SG_ 2152464384 LKAIC_Ind1 1;
BA_REL_ "GenSigSuprvResp" BU_SG_REL_ IPC_LS SG_ 2152464384 LKAIC_Ind1 1;
BA_REL_ "GenSigSuprvResp" BU_SG_REL_ BCM_LS SG_ 2152464384 LKAIC_IndReq 1;
BA_REL_ "GenSigSuprvResp" BU_SG_REL_ IPC_LS SG_ 2152464384 LKAIC_IndReq 1;
BA_REL_ "GenSigSuprvResp" BU_SG_REL_ BCM_LS SG_ 2152464384 SrvcLaneDepWrnSysIO 1;
BA_REL_ "GenSigSuprvResp" BU_SG_REL_ BCM_LS SG_ 2152464384 LDWIC_LnDepWAWLn 1;
BA_REL_ "GenSigSuprvResp" BU_SG_REL_ IPC_LS SG_ 2152464384 LDWIC_LnDepWAWLn 1;
BA_REL_ "GenSigSuprvResp" BU_SG_REL_ BCM_LS SG_ 2152464384 LDWIC_Ind2 1;
BA_REL_ "GenSigSuprvResp" BU_SG_REL_ IPC_LS SG_ 2152464384 LDWIC_Ind2 1;
BA_REL_ "GenSigSuprvResp" BU_SG_REL_ BCM_LS SG_ 2152464384 LDWIC_Ind1 1;
BA_REL_ "GenSigSuprvResp" BU_SG_REL_ IPC_LS SG_ 2152464384 LDWIC_Ind1 1;
BA_REL_ "GenSigSuprvResp" BU_SG_REL_ BCM_LS SG_ 2152464384 LDWIC_IndReq 1;
BA_REL_ "GenSigSuprvResp" BU_SG_REL_ IPC_LS SG_ 2152464384 LDWIC_IndReq 1;
BA_REL_ "GenSigSuprvResp" BU_SG_REL_ MSM_P_LS SG_ 2154971136 PassHCSeatSw3Act 1;
BA_REL_ "GenSigSuprvResp" BU_SG_REL_ HVSM_F_LS SG_ 2154971136 PassHCSeatSw3Act 1;
BA_REL_ "GenSigSuprvResp" BU_SG_REL_ MSM_LS SG_ 2154971136 PassHCSeatSw3Act 1;
BA_REL_ "GenSigSuprvResp" BU_SG_REL_ MSM_P_LS SG_ 2154971136 PassHCSeatSw2Act 1;
BA_REL_ "GenSigSuprvResp" BU_SG_REL_ HVSM_F_LS SG_ 2154971136 PassHCSeatSw2Act 1;
BA_REL_ "GenSigSuprvResp" BU_SG_REL_ MSM_LS SG_ 2154971136 PassHCSeatSw2Act 1;
BA_REL_ "GenSigSuprvResp" BU_SG_REL_ MSM_P_LS SG_ 2154971136 PassHCSeatSw1Act 1;
BA_REL_ "GenSigSuprvResp" BU_SG_REL_ HVSM_F_LS SG_ 2154971136 PassHCSeatSw1Act 1;
BA_REL_ "GenSigSuprvResp" BU_SG_REL_ MSM_LS SG_ 2154971136 PassHCSeatSw1Act 1;
BA_REL_ "GenSigSuprvResp" BU_SG_REL_ MSM_P_LS SG_ 2154971136 DrvHCSeatSw3Act 1;
BA_REL_ "GenSigSuprvResp" BU_SG_REL_ HVSM_F_LS SG_ 2154971136 DrvHCSeatSw3Act 1;
BA_REL_ "GenSigSuprvResp" BU_SG_REL_ MSM_LS SG_ 2154971136 DrvHCSeatSw3Act 1;
BA_REL_ "GenSigSuprvResp" BU_SG_REL_ MSM_P_LS SG_ 2154971136 DrvHCSeatSw2Act 1;
BA_REL_ "GenSigSuprvResp" BU_SG_REL_ HVSM_F_LS SG_ 2154971136 DrvHCSeatSw2Act 1;
BA_REL_ "GenSigSuprvResp" BU_SG_REL_ MSM_LS SG_ 2154971136 DrvHCSeatSw2Act 1;
BA_REL_ "GenSigSuprvResp" BU_SG_REL_ MSM_P_LS SG_ 2154971136 DrvHCSeatSw1Act 1;
BA_REL_ "GenSigSuprvResp" BU_SG_REL_ HVSM_F_LS SG_ 2154971136 DrvHCSeatSw1Act 1;
BA_REL_ "GenSigSuprvResp" BU_SG_REL_ MSM_LS SG_ 2154971136 DrvHCSeatSw1Act 1;
BA_REL_ "GenSigSuprvResp" BU_SG_REL_ ICS_LS SG_ 2154962944 PassHCSMInd3 1;
BA_REL_ "GenSigSuprvResp" BU_SG_REL_ ECC_LS SG_ 2154962944 PassHCSMInd3 1;
BA_REL_ "GenSigSuprvResp" BU_SG_REL_ ICS_LS SG_ 2154962944 PassHCSMInd2 1;
BA_REL_ "GenSigSuprvResp" BU_SG_REL_ ECC_LS SG_ 2154962944 PassHCSMInd2 1;
BA_REL_ "GenSigSuprvResp" BU_SG_REL_ ICS_LS SG_ 2154962944 PassHCSMInd1 1;
BA_REL_ "GenSigSuprvResp" BU_SG_REL_ ECC_LS SG_ 2154962944 PassHCSMInd1 1;
BA_REL_ "GenSigSuprvResp" BU_SG_REL_ ICS_LS SG_ 2154962944 PassHCSMIndReq 1;
BA_REL_ "GenSigSuprvResp" BU_SG_REL_ ECC_LS SG_ 2154962944 PassHCSMIndReq 1;
BA_REL_ "GenSigSuprvResp" BU_SG_REL_ IPC_LS SG_ 2154962944 PassHCSLSeatLev5 1;
BA_REL_ "GenSigSuprvResp" BU_SG_REL_ ICS_LS SG_ 2154962944 PassHCSLSeatLev5 1;
BA_REL_ "GenSigSuprvResp" BU_SG_REL_ ECC_LS SG_ 2154962944 PassHCSLSeatLev5 1;
BA_REL_ "GenSigSuprvResp" BU_SG_REL_ IPC_LS SG_ 2154962944 PassHCSLSeatLev4 1;
BA_REL_ "GenSigSuprvResp" BU_SG_REL_ ICS_LS SG_ 2154962944 PassHCSLSeatLev4 1;
BA_REL_ "GenSigSuprvResp" BU_SG_REL_ ECC_LS SG_ 2154962944 PassHCSLSeatLev4 1;
BA_REL_ "GenSigSuprvResp" BU_SG_REL_ IPC_LS SG_ 2154962944 PassHCSLSeatLev3 1;
BA_REL_ "GenSigSuprvResp" BU_SG_REL_ ICS_LS SG_ 2154962944 PassHCSLSeatLev3 1;
BA_REL_ "GenSigSuprvResp" BU_SG_REL_ ECC_LS SG_ 2154962944 PassHCSLSeatLev3 1;
BA_REL_ "GenSigSuprvResp" BU_SG_REL_ IPC_LS SG_ 2154962944 PassHCSLSeatLev2 1;
BA_REL_ "GenSigSuprvResp" BU_SG_REL_ ICS_LS SG_ 2154962944 PassHCSLSeatLev2 1;
BA_REL_ "GenSigSuprvResp" BU_SG_REL_ ECC_LS SG_ 2154962944 PassHCSLSeatLev2 1;
BA_REL_ "GenSigSuprvResp" BU_SG_REL_ IPC_LS SG_ 2154962944 PassHCSLSeatLev1 1;
BA_REL_ "GenSigSuprvResp" BU_SG_REL_ ICS_LS SG_ 2154962944 PassHCSLSeatLev1 1;
BA_REL_ "GenSigSuprvResp" BU_SG_REL_ ECC_LS SG_ 2154962944 PassHCSLSeatLev1 1;
BA_REL_ "GenSigSuprvResp" BU_SG_REL_ IPC_LS SG_ 2154962944 PassHCSLIndReq 1;
BA_REL_ "GenSigSuprvResp" BU_SG_REL_ ICS_LS SG_ 2154962944 PassHCSLIndReq 1;
BA_REL_ "GenSigSuprvResp" BU_SG_REL_ ECC_LS SG_ 2154962944 PassHCSLIndReq 1;
BA_REL_ "GenSigSuprvResp" BU_SG_REL_ ICS_LS SG_ 2154962944 DrvHCSMInd1 1;
BA_REL_ "GenSigSuprvResp" BU_SG_REL_ ECC_LS SG_ 2154962944 DrvHCSMInd1 1;
BA_REL_ "GenSigSuprvResp" BU_SG_REL_ ICS_LS SG_ 2154962944 DrvHCSMIndReq 1;
BA_REL_ "GenSigSuprvResp" BU_SG_REL_ ECC_LS SG_ 2154962944 DrvHCSMIndReq 1;
BA_REL_ "GenSigSuprvResp" BU_SG_REL_ ICS_LS SG_ 2154962944 DrvHCSMInd3 1;
BA_REL_ "GenSigSuprvResp" BU_SG_REL_ ECC_LS SG_ 2154962944 DrvHCSMInd3 1;
BA_REL_ "GenSigSuprvResp" BU_SG_REL_ ICS_LS SG_ 2154962944 DrvHCSMInd2 1;
BA_REL_ "GenSigSuprvResp" BU_SG_REL_ ECC_LS SG_ 2154962944 DrvHCSMInd2 1;
BA_REL_ "GenSigSuprvResp" BU_SG_REL_ IPC_LS SG_ 2154962944 DrvHCSLSeatLev5 1;
BA_REL_ "GenSigSuprvResp" BU_SG_REL_ ICS_LS SG_ 2154962944 DrvHCSLSeatLev5 1;
BA_REL_ "GenSigSuprvResp" BU_SG_REL_ ECC_LS SG_ 2154962944 DrvHCSLSeatLev5 1;
BA_REL_ "GenSigSuprvResp" BU_SG_REL_ IPC_LS SG_ 2154962944 DrvHCSLSeatLev4 1;
BA_REL_ "GenSigSuprvResp" BU_SG_REL_ ICS_LS SG_ 2154962944 DrvHCSLSeatLev4 1;
BA_REL_ "GenSigSuprvResp" BU_SG_REL_ ECC_LS SG_ 2154962944 DrvHCSLSeatLev4 1;
BA_REL_ "GenSigSuprvResp" BU_SG_REL_ IPC_LS SG_ 2154962944 DrvHCSLSeatLev3 1;
BA_REL_ "GenSigSuprvResp" BU_SG_REL_ ICS_LS SG_ 2154962944 DrvHCSLSeatLev3 1;
BA_REL_ "GenSigSuprvResp" BU_SG_REL_ ECC_LS SG_ 2154962944 DrvHCSLSeatLev3 1;
BA_REL_ "GenSigSuprvResp" BU_SG_REL_ IPC_LS SG_ 2154962944 DrvHCSLSeatLev2 1;
BA_REL_ "GenSigSuprvResp" BU_SG_REL_ ICS_LS SG_ 2154962944 DrvHCSLSeatLev2 1;
BA_REL_ "GenSigSuprvResp" BU_SG_REL_ ECC_LS SG_ 2154962944 DrvHCSLSeatLev2 1;
BA_REL_ "GenSigSuprvResp" BU_SG_REL_ IPC_LS SG_ 2154962944 DrvHCSLSeatLev1 1;
BA_REL_ "GenSigSuprvResp" BU_SG_REL_ ICS_LS SG_ 2154962944 DrvHCSLSeatLev1 1;
BA_REL_ "GenSigSuprvResp" BU_SG_REL_ ECC_LS SG_ 2154962944 DrvHCSLSeatLev1 1;
BA_REL_ "GenSigSuprvResp" BU_SG_REL_ IPC_LS SG_ 2154962944 DrvHCSLIndReq 1;
BA_REL_ "GenSigSuprvResp" BU_SG_REL_ ICS_LS SG_ 2154962944 DrvHCSLIndReq 1;
BA_REL_ "GenSigSuprvResp" BU_SG_REL_ ECC_LS SG_ 2154962944 DrvHCSLIndReq 1;
BA_REL_ "GenSigSuprvResp" BU_SG_REL_ CSM_LS SG_ 2154987520 WrlsChrgSysChrgStat 1;
BA_REL_ "GenSigSuprvResp" BU_SG_REL_ RadioHead_LS SG_ 2154987520 WrlsChrgSysChrgStat 1;
BA_REL_ "GenSigSuprvResp" BU_SG_REL_ V2V_LS SG_ 2154987520 HdSt 1;
BA_REL_ "GenSigSuprvResp" BU_SG_REL_ VPM_LS SG_ 2154987520 HdSt 1;
BA_REL_ "GenSigSuprvResp" BU_SG_REL_ ISRVM_LS SG_ 2154840064 CmpsZnNvrSet 1;
BA_REL_ "GenSigSuprvResp" BU_SG_REL_ ISRVM_LS SG_ 2154840064 CmpsSatrtd 1;
BA_REL_ "GenSigSuprvResp" BU_SG_REL_ ISRVM_LS SG_ 2154840064 CmpsDecZone 1;
BA_REL_ "GenSigSuprvResp" BU_SG_REL_ ISRVM_LS SG_ 2154840064 CmpsOctHdingDataSrc 1;
BA_REL_ "GenSigSuprvResp" BU_SG_REL_ ISRVM_LS SG_ 2154840064 CmpsOctHding 1;
BA_REL_ "GenSigSuprvResp" BU_SG_REL_ ISRVM_LS SG_ 2154840064 CmpsModManCalInPrc 1;
BA_REL_ "GenSigSuprvResp" BU_SG_REL_ ISRVM_LS SG_ 2154840064 CmpsModFltPrs 1;
BA_REL_ "GenSigSuprvResp" BU_SG_REL_ ISRVM_LS SG_ 2154840064 CmpsCrHding 1;
BA_REL_ "GenSigSuprvResp" BU_SG_REL_ BSM_LS SG_ 2154643456 HtrCoreInltClntTmpCalc 1;
BA_REL_ "GenSigSuprvResp" BU_SG_REL_ VICM_LS SG_ 2154643456 HtrCoreInltClntTmpCalc 1;
BA_REL_ "GenSigSuprvResp" BU_SG_REL_ BSM_LS SG_ 2154643456 CCClntCrcFlwRtReq 1;
BA_REL_ "GenSigSuprvResp" BU_SG_REL_ VICM_LS SG_ 2154643456 CCClntCrcFlwRtReq 1;
VAL_ 2156789760 FrPedDetCsStReq 3 "Alert and Brake" 2 "Alert" 1 "Off" 0 "No Action" ;
VAL_ 2156789760 SurdVwLightgCsSetReq 7 "Unused and Reserved 5" 6 "Unused and Reserved 4" 5 "Unused and Reserved 3" 4 "Unused and Reserved 2" 3 "Unused and Reserved 1" 2 "ON" 1 "OFF" 0 "No Action" ;
VAL_ 2156789760 SmrtHgBmAstCstSetReq 7 "Unused and Reserved 5" 6 "Unused and Reserved 4" 5 "Unused and Reserved 3" 4 "Unused and Reserved 2" 3 "Unused and Reserved 1" 2 "Adaptive High Beam" 1 "Auto High Beam" 0 "No Action" ;
VAL_ 2156789760 TimeDispFormat 1 "24 hour mode" 0 "12 hour mode" ;
VAL_ 2156789760 CldrMth 12 "December" 11 "November" 10 "October" 9 "September" 8 "August" 7 "July" 6 "June" 5 "May" 4 "April" 3 "March" 2 "February" 1 "January" 0 "Unknown" ;
VAL_ 2155020288 ChVolRq2 0 "Normal" 1 "Loud" ;
VAL_ 2155020288 LngSelExt 41 "ZA English" 40 "AU English" 39 "Macedonian" 38 "Latvian" 37 "Estonian" 36 "Lithuanian" 35 "Serbian" 34 "Uzbek" 33 "Cantonese" 32 "NA Spanish" 31 "NA French" 30 "Ukrainian" 29 "Croatian" 28 "Slovenian" 27 "Romanian" 26 "Bulgarian" 25 "Thai" 24 "Brazilian Portuguese" 23 "Russian" 22 "Slovak" 21 "Czech" 20 "Hungarian" 19 "UK English" 18 "Traditional Chinese" 17 "Korean" 16 "Turkish" 15 "Polish" 14 "Standard Chinese" 13 "Arabic" 12 "Japanese" 11 "Greek" 10 "Danish" 9 "Finnish" 8 "Norwegian" 7 "Portuguese" 6 "Dutch" 5 "Spanish" 4 "French" 3 "Swedish" 2 "Italian" 1 "German" 0 "NA English" ;
VAL_ 2150432768 CbnHtrWrmUpIO 1 "true" 0 "false" ;
VAL_ 2150432768 EngManfldAirTempCrtdV 1 "Invalid" 0 "Valid" ;
VAL_ 2150432768 GrdBrkgAct 1 "true" 0 "false" ;
VAL_ 2150432768 FuelFltLifRstPerf 1 "true" 0 "false" ;
VAL_ 2150432768 EngShtdwnPndgIO 1 "true" 0 "false" ;
VAL_ 2150432768 GenFldDutCycV 1 "Invalid" 0 "Valid" ;
VAL_ 2150432768 TransOilTempSensPres 1 "true" 0 "false" ;
VAL_ 2150432768 TrnsNEmsRltMalfActv 1 "true" 0 "false" ;
VAL_ 2150432768 TrnEmsMlfAtv 1 "true" 0 "false" ;
VAL_ 2150432768 TrnsThrmlMngmntStat 2 "Driver Intervention Requested" 1 "Countermeasures Active" 0 "Normal" ;
VAL_ 2150432768 PTHiElecLdReqd 1 "true" 0 "false" ;
VAL_ 2155298816 EngAirFltMonDrvrReq 3 "Reset" 2 "Disable" 1 "Enable" 0 "No Action" ;
VAL_ 2155298816 TrPrsMntrTrLdRstRqstd 0 "Unknown" 1 "Light Load" 2 "Best Economy Load" 3 "Max Load" ;
VAL_ 2155298816 TrPrsSnsProgEvntRqd 1 "true" 0 "false" ;
VAL_ 2158878720 ODDLC_WrpArnd 1 "true" 0 "false" ;
VAL_ 2158878720 ODDLC_ReqType 0 "Subscribe: FU sends DynData back and then on change) " 1 "Unsubscribe: cancel previous Subscribe" ;
VAL_ 2158878720 ODDLC_ReqDir 1 "true" 0 "false" ;
VAL_ 2158878720 ODDLC_DspMID 128 "Reserved" 64 "Reserved" 32 "OTIM" 16 "RearDisplayTwo" 8 "RearDisplayOne" 4 "AuxIP" 2 "CenterStack" 1 "IPC" ;
VAL_ 2158878720 ODDLC_BckgndFlag 1 "Background response" 0 "Immediate response required" ;
VAL_ 2158870528 ODDLA_WrpArnd 1 "true" 0 "false" ;
VAL_ 2158870528 ODDLA_ReqType 0 "Subscribe: FU sends DynData back and then on change) " 1 "Unsubscribe: cancel previous Subscribe" ;
VAL_ 2158870528 ODDLA_ReqDir 1 "true" 0 "false" ;
VAL_ 2158870528 ODDLA_DspMID 128 "Reserved" 64 "Reserved" 32 "OTIM" 16 "RearDisplayTwo" 8 "RearDisplayOne" 4 "AuxIP" 2 "CenterStack" 1 "IPC" ;
VAL_ 2158870528 ODDLA_BckgndFlag 1 "Background response" 0 "Immediate response required" ;
VAL_ 2154692608 LgclAVChnl 0 "None" 1 "Unused and Reserved 1" 2 "Unused and Reserved 2" 3 "Asynchronous Message" 4 "Incoming Call" 5 "Phone" 6 "Synchronous Message" 7 "Speech Recognition" 8 "Emergency Phone Call" 9 "Short Mix Alert Message" 10 "Unused and Reserved 3" 11 "Unused and Reserved 4" 12 "Onstar Initiated Call" ;
VAL_ 2154692608 ASSAudSrcStatCode 5 "Producing Audio" 4 "Producing Silence" 3 "Reserved" 2 "Audio Not Available" 1 "Audio Available" 0 "Device Present" ;
VAL_ 2154692608 ASSAudSrcChType 4 "Mono Emergency" 3 "Mixed" 2 "Stereo" 1 "Mono" 0 "No Action" ;
VAL_ 2154692608 ASSAudSrcType 28 "Phone" 24 "Sat. Digital Audio Receiver System" 20 "Digital Audio Broadcast" 16 "Remote CD Changer" 12 "Remote Digital Video Disk" 8 "Auxiliary Device" 1 "Television Tuner" ;
VAL_ 2154627072 LgclAVChnl_368 0 "None" 1 "Unused and Reserved 1" 2 "Unused and Reserved 2" 3 "Asynchronous Message" 4 "Incoming Call" 5 "Phone" 6 "Synchronous Message" 7 "Speech Recognition" 8 "Emergency Phone Call" 9 "Short Mix Alert Message" 10 "Unused and Reserved 3" 11 "Unused and Reserved 4" 12 "Onstar Initiated Call" ;
VAL_ 2154627072 AudMstrSrcTyp 28 "Phone" 24 "Sat. Digital Audio Receiver System" 20 "Digital Audio Broadcast" 16 "Remote CD Changer" 12 "Remote Digital Video Disk" 8 "Auxiliary Device" 1 "Television Tuner" 0 "Audio Supervisor" ;
VAL_ 2154627072 AudMstrChnnlTyp 3 "Mixed" 2 "Stereo" 1 "Mono" 0 "No Channel" ;
VAL_ 2154627072 AudMstrArbCom 4 "Connection Complete" 3 "Disconnect" 2 "Connect" 1 "Do Not Connect" 0 "No Action" ;
VAL_ 2151112704 FrPasSeatbltRemOccSt 1 "Occupied" 0 "Empty" ;
VAL_ 2151112704 FrPasSeatResCtrlOccStV 1 "Invalid" 0 "Valid" ;
VAL_ 2151112704 FrPasSeatResCtrlOccSt 2 "Occupied" 1 "Empty" 0 "Unknown" ;
VAL_ 2151112704 FrPsSeatOccSnsOpMd 3 "SystemInitMod" 2 "BarrierMod" 1 "ZeroSetCheckMod" 0 "FieldMod" ;
VAL_ 2151112704 FrPsSeatOccFltSt 2 "Fault Present - Vehicle Mismatch" 1 "Fault Present" 0 "No Faults Present" ;
VAL_ 2151112704 FrntPassClass 7 "Large Adult" 6 "Small Adult" 5 "Large Child" 4 "Small Child" 3 "Child Seat Unknown" 2 "Child Seat Forward" 1 "Child Seat Rearward" 0 "Classification Not Applicable" ;
VAL_ 2153938944 RmtRflshMdReqtd 1 "true" 0 "false" ;
VAL_ 2158862336 ODIAOT_DspMID 128 "Reserved" 64 "Reserved" 32 "OTIM" 16 "RearDisplayTwo" 8 "RearDisplayOne" 4 "AuxIP" 2 "CenterStack" 1 "IPC" ;
VAL_ 2158862336 ODIAOT_DaTy 21 "Bitmap" 20 "DecimalShort" 19 "HoursOfDay" 18 "Character" 17 "Fuel Consumption Inverted" 16 "Fuel Consumption" 15 "Pressure" 14 "Temperature" 13 "Volume" 12 "DistanceShort" 11 "DistanceLong" 10 "BitmapId" 9 "TextId" 8 "Pictogram" 7 "List " 6 "Date" 5 "Time " 4 "Decimal" 3 "EnumerationValue" 2 "Integer" 1 "String" 0 "Speed" ;
VAL_ 2150662144 EnvIdRspSt3 3 "Environment_id_request" 2 "Incorrect_immo_id" 1 "Info_valid" 0 "No_info" ;
VAL_ 2150653952 EnvIdRspSt2 3 "Environment_id_request" 2 "Incorrect_immo_id" 1 "Info_valid" 0 "No_info" ;
VAL_ 2150850560 PsSbltAtcV 1 "Invalid" 0 "Valid" ;
VAL_ 2150850560 PsSbltAtc 1 "true" 0 "false" ;
VAL_ 2150850560 DrSbltAtcV 1 "Invalid" 0 "Valid" ;
VAL_ 2150850560 DrSbltAtc 1 "true" 0 "false" ;
VAL_ 2154659840 StrgClmnLckVisNot 1 "true" 0 "false" ;
VAL_ 2154659840 UnlockRtryPshIndOn 1 "true" 0 "false" ;
VAL_ 2154659840 UnlckRtryRotIndOn 1 "true" 0 "false" ;
VAL_ 2154659840 ClmSysFlrIndOn 1 "true" 0 "false" ;
VAL_ 2154659840 StrngClmnLckTT 2 "Flashing Indication" 1 "Continous Indication" 0 "No indication" ;
VAL_ 2154659840 ClmnLckStatV 1 "Invalid" 0 "Valid" ;
VAL_ 2154659840 ClmnLckStat 2 "Locked unsuccessful" 1 "Unlocked" 0 "Locked" 3 "Unlocked unsuccessful" ;
VAL_ 2154938368 FobProgMdStat 2 "Complete" 1 "Active" 0 "Inactive" ;
VAL_ 2155266048 RRHCSeatSw3Act 1 "true" 0 "false" ;
VAL_ 2155266048 RRHCSeatSw2Act 1 "true" 0 "false" ;
VAL_ 2155266048 RRHCSeatSw1Act 1 "true" 0 "false" ;
VAL_ 2155266048 RLHCSeatSw3Act 1 "true" 0 "false" ;
VAL_ 2155266048 RLHCSeatSw2Act 1 "true" 0 "false" ;
VAL_ 2155266048 RLHCSeatSw1Act 1 "true" 0 "false" ;
VAL_ 2155249664 RRHCSMInd3 1 "true" 0 "false" ;
VAL_ 2155249664 RRHCSMInd2 1 "true" 0 "false" ;
VAL_ 2155249664 RRHCSMInd1 1 "true" 0 "false" ;
VAL_ 2155249664 RRHCSMIndReq 3 "Flash Rate #2 Indication" 2 "Flash Rate #1 Indication" 1 "Continuous Indication" 0 "Off" ;
VAL_ 2155249664 RRHCSLSeatLev5 1 "true" 0 "false" ;
VAL_ 2155249664 RRHCSLSeatLev4 1 "true" 0 "false" ;
VAL_ 2155249664 RRHCSLSeatLev3 1 "true" 0 "false" ;
VAL_ 2155249664 RRHCSLSeatLev2 1 "true" 0 "false" ;
VAL_ 2155249664 RRHCSLSeatLev1 1 "true" 0 "false" ;
VAL_ 2155249664 RRHCSLIndReq 3 "Flash Rate #2 Indication" 2 "Flash Rate #1 Indication" 1 "Continuous Indication" 0 "Off" ;
VAL_ 2155249664 RLHCSMInd3 1 "true" 0 "false" ;
VAL_ 2155249664 RLHCSMInd2 1 "true" 0 "false" ;
VAL_ 2155249664 RLHCSMInd1 1 "true" 0 "false" ;
VAL_ 2155249664 RLHCSMIndReq 3 "Flash Rate #2 Indication" 2 "Flash Rate #1 Indication" 1 "Continuous Indication" 0 "Off" ;
VAL_ 2155249664 RLHCSLSeatLev5 1 "true" 0 "false" ;
VAL_ 2155249664 RLHCSLSeatLev4 1 "true" 0 "false" ;
VAL_ 2155249664 RLHCSLSeatLev3 1 "true" 0 "false" ;
VAL_ 2155249664 RLHCSLSeatLev2 1 "true" 0 "false" ;
VAL_ 2155249664 RLHCSLSeatLev1 1 "true" 0 "false" ;
VAL_ 2155249664 RLHCSLIndReq 3 "Flash Rate #2 Indication" 2 "Flash Rate #1 Indication" 1 "Continuous Indication" 0 "Off" ;
VAL_ 2155184128 SmPhRmFunCstCurStVal 7 "Unused and Reserved 5" 6 "Unused and Reserved 4" 5 "Unused and Reserved 3" 4 "Unused and Reserved 2" 3 "Unused and Reserved 1" 2 "On" 1 "Off" 0 "No Action" ;
VAL_ 2155184128 SmPhRmFunCstStAval 1 "true" 0 "false" ;
VAL_ 2155184128 RrStRmndrIO 1 "true" 0 "false" ;
VAL_ 2155184128 RrStRmndrCstCurrSetVal 2 "On" 1 "Off" 0 "No Action" ;
VAL_ 2155184128 RrStRmndrCstSetAvail 1 "true" 0 "false" ;
VAL_ 2155184128 IdlRecmndToClEngIO 1 "true" 0 "false" ;
VAL_ 2155184128 TrnsShftLvrLckStat 0 "Locked" 1 "Unlocked" ;
VAL_ 2155184128 CrsSpdLmtrSwStat 9 "Between Ranges" 8 "Short to Power" 7 "Open/Short to Ground" 6 "Cancel" 5 "Cruise On/Off" 4 "SL/SW On/Off/GAP" 3 "Set" 2 "Resume" 1 "No Activation" 0 "Indeterminate" ;
VAL_ 2155184128 CrsCntrlSwStCanSwAct 1 "true" 0 "false" ;
VAL_ 2155184128 CrsCntrlSwStSwDataIntgty 3 "Illegal Range" 2 "Failure Detected" 1 "Data Invalid" 0 "Data Valid" ;
VAL_ 2155184128 CrsCntrlSwStSpdInSwAct 1 "true" 0 "false" ;
VAL_ 2155184128 CrsCntrlSwStSpDcSwAct 1 "true" 0 "false" ;
VAL_ 2155184128 CrsCntrlSwStSetSwAct 1 "true" 0 "false" ;
VAL_ 2155184128 CrsCntrlSwStResSwAct 1 "true" 0 "false" ;
VAL_ 2155184128 CrsCntrlSwStOnSwAct 1 "true" 0 "false" ;
VAL_ 2155184128 CrsCntAtv 1 "true" 0 "false" ;
VAL_ 2155167744 ClsEngCmprtmtToStrtVehIO 1 "true" 0 "false" ;
VAL_ 2155167744 PrsCltchPrsStrtAgnIO 1 "true" 0 "false" ;
VAL_ 2155167744 PrsStrtAgnIO 1 "true" 0 "false" ;
VAL_ 2155167744 AutoShtdwnDsblIO 1 "true" 0 "false" ;
VAL_ 2155167744 ShftToNtrlIO 1 "true" 0 "false" ;
VAL_ 2155167744 AppPrkBrkIO 1 "true" 0 "false" ;
VAL_ 2155167744 NRmtDtctdRstrtAllwd 1 "true" 0 "false" ;
VAL_ 2155167744 NRmtDtdPsCluRstIO 1 "true" 0 "false" ;
VAL_ 2155167744 SecPwrMdPshBtnAtv 1 "true" 0 "false" ;
VAL_ 2155167744 TSLgMdPwrCtOWAtv 1 "true" 0 "false" ;
VAL_ 2155167744 PrsBtnAgnTTrnEngOffIO 1 "true" 0 "false" ;
VAL_ 2155167744 NRmtDtdPsBrkRstIO 1 "true" 0 "false" ;
VAL_ 2155167744 NoReDetInOn 1 "true" 0 "false" ;
VAL_ 2155167744 ApplyCltPdlIO 1 "true" 0 "false" ;
VAL_ 2155167744 VehMovState 4 "Invalid" 3 "Reverse" 2 "Forward" 1 "Neutral" 0 "Parked" ;
VAL_ 2155167744 TrStLgMdAtv 1 "true" 0 "false" ;
VAL_ 2155167744 TransModInactIO 1 "true" 0 "false" ;
VAL_ 2155167744 TransModActIO 1 "true" 0 "false" ;
VAL_ 2155167744 ApplyBrkPdlIO 1 "true" 0 "false" ;
VAL_ 2155167744 Ky_IdDevPr 1 "true" 0 "false" ;
VAL_ 2155167744 KylsStrtUseTxPckIO 1 "true" 0 "false" ;
VAL_ 2155167744 ShftPrkIO 1 "true" 0 "false" ;
VAL_ 2154921984 RFRmtCntFobNm 5 "Remote Control Fob #5" 4 "Remote Control Fob #4" 3 "Remote Control Fob #3" 2 "Remote Control Fob #2" 1 "Remote Control Fob #1" 0 "No Fob" ;
VAL_ 2154921984 RFRmtCntrlFobFnc 31 "Charge Termination" 30 "Pwr Top Control Start Motion Contrl" 29 "Pwr Top Control Stop Motion Control" 28 "Comfort Close 2" 27 "Comfort Open 2" 26 "Connectivity Request" 25 "Comfort Close" 24 "Comfort Open" 23 "Right Sliding Dr Stop Motion Contrl" 22 "Left Sliding Dr Stop Motion Control" 21 "Pwr Rr Closure Start Motion Control" 20 "Pwr Rr Closure Stop Motion Control" 19 "All Door Double Lock" 18 "Pwr Rr Closure Stop While Opening" 17 "Pwr Rr Closure Stop While Closing" 16 "Power Rear Closure Open Control" 15 "Power Rear Closure Close Control" 14 "Locator Alarm Control" 13 "Fob Programmed" 12 "Engine Stop" 11 "Engine Run" 10 "Power Top Control" 9 "Power Window Control" 8 "Fuel Door Control" 7 "Panic Alarm Control" 6 "Right Sliding Door Control" 5 "Left Sliding Door Control" 4 "Rear Closure Control" 3 "All Door Unlock" 2 "Driver Door Unlock" 1 "Lock" 0 "No Activation" ;
VAL_ 2154921984 RFRmtCntFobBatLw 1 "true" 0 "false" ;
VAL_ 2154921984 FobPogLimRchdIndOn 1 "true" 0 "false" ;
VAL_ 2151317504 PrkAstRrSysStat 3 "Failed" 2 "Inhibited" 1 "Enabled" 0 "Disabled" ;
VAL_ 2151317504 PARrRgn4ObjStat 15 "Zone 15" 14 "Zone 14" 13 "Zone 13" 12 "Zone 12" 11 "Zone 11" 10 "Zone 10" 9 "Zone 9" 8 "Zone 8" 7 "Zone 7" 6 "Zone 6" 5 "Zone 5" 4 "Zone 4" 3 "Zone 3" 2 "Zone 2" 1 "Zone 1" 0 "No Object" ;
VAL_ 2151317504 PARrRgn3ObjStat 15 "Zone 15" 14 "Zone 14" 13 "Zone 13" 12 "Zone 12" 11 "Zone 11" 10 "Zone 10" 9 "Zone 9" 8 "Zone 8" 7 "Zone 7" 6 "Zone 6" 5 "Zone 5" 4 "Zone 4" 3 "Zone 3" 2 "Zone 2" 1 "Zone 1" 0 "No Object" ;
VAL_ 2151317504 PARrRgn2ObjStat 15 "Zone 15" 14 "Zone 14" 13 "Zone 13" 12 "Zone 12" 11 "Zone 11" 10 "Zone 10" 9 "Zone 9" 8 "Zone 8" 7 "Zone 7" 6 "Zone 6" 5 "Zone 5" 4 "Zone 4" 3 "Zone 3" 2 "Zone 2" 1 "Zone 1" 0 "No Object" ;
VAL_ 2151317504 PARrRgn1ObjStat 15 "Zone 15" 14 "Zone 14" 13 "Zone 13" 12 "Zone 12" 11 "Zone 11" 10 "Zone 10" 9 "Zone 9" 8 "Zone 8" 7 "Zone 7" 6 "Zone 6" 5 "Zone 5" 4 "Zone 4" 3 "Zone 3" 2 "Zone 2" 1 "Zone 1" 0 "No Object" ;
VAL_ 2151301120 PrkAsstRrOffIO 1 "true" 0 "false" ;
VAL_ 2151301120 PrkAstAdvSysAct 1 "true" 0 "false" ;
VAL_ 2151301120 PrkAstFrSysStat 3 "Failed" 2 "Inhibited" 1 "Enabled" 0 "Disabled" ;
VAL_ 2151301120 PAFrtRgn4ObjStat 15 "Zone 15" 14 "Zone 14" 13 "Zone 13" 12 "Zone 12" 11 "Zone 11" 10 "Zone 10" 9 "Zone 9" 8 "Zone 8" 7 "Zone 7" 6 "Zone 6" 5 "Zone 5" 4 "Zone 4" 3 "Zone 3" 2 "Zone 2" 1 "Zone 1" 0 "No Object" ;
VAL_ 2151301120 PAFrtRgn3ObjStat 15 "Zone 15" 14 "Zone 14" 13 "Zone 13" 12 "Zone 12" 11 "Zone 11" 10 "Zone 10" 9 "Zone 9" 8 "Zone 8" 7 "Zone 7" 6 "Zone 6" 5 "Zone 5" 4 "Zone 4" 3 "Zone 3" 2 "Zone 2" 1 "Zone 1" 0 "No Object" ;
VAL_ 2151301120 PAFrtRgn2ObjStat 15 "Zone 15" 14 "Zone 14" 13 "Zone 13" 12 "Zone 12" 11 "Zone 11" 10 "Zone 10" 9 "Zone 9" 8 "Zone 8" 7 "Zone 7" 6 "Zone 6" 5 "Zone 5" 4 "Zone 4" 3 "Zone 3" 2 "Zone 2" 1 "Zone 1" 0 "No Object" ;
VAL_ 2151301120 PAFrtRgn1ObjStat 15 "Zone 15" 14 "Zone 14" 13 "Zone 13" 12 "Zone 12" 11 "Zone 11" 10 "Zone 10" 9 "Zone 9" 8 "Zone 8" 7 "Zone 7" 6 "Zone 6" 5 "Zone 5" 4 "Zone 4" 3 "Zone 3" 2 "Zone 2" 1 "Zone 1" 0 "No Object" ;
VAL_ 2153922560 HtrVlvRqstdPstn 0 "No Request" 1 "Engine Bypass" 2 "Engine Link" 3 "Hold Current Position" ;
VAL_ 2153922560 ClntHtrElecPwrRatV 1 "Invalid" 0 "Valid" ;
VAL_ 2153922560 ClmtCtrlHtrEngRunRq 1 "Engine Run Requested" 0 "No Action" ;
VAL_ 2153922560 ClimCtrlVoltBstModReq 1 "true" 0 "false" ;
VAL_ 2153807872 PsvStrtStrngClmnLckTT 2 "Flashing Indication" 1 "Continous Indication" 0 "No indication" ;
VAL_ 2153807872 ClmSysAuxFlrIndOn 1 "true" 0 "false" ;
VAL_ 2153807872 PsDoorOpenSwActV 1 "Invalid" 0 "Valid" ;
VAL_ 2153807872 PsDoorOpenSwAct 1 "true" 0 "false" ;
VAL_ 2153807872 DrDoorOpenSwActV 1 "Invalid" 0 "Valid" ;
VAL_ 2153807872 DrDoorOpenSwAct 1 "true" 0 "false" ;
VAL_ 2150703104 AudSysVNoisCompPres 1 "true" 0 "false" ;
VAL_ 2150703104 AudSysSurSndSysPres 1 "true" 0 "false" ;
VAL_ 2150703104 AudSysDigSigProcPres 1 "true" 0 "false" ;
VAL_ 2151399424 VhlFlRngLwIO 1 "true" 0 "false" ;
VAL_ 2151399424 WshFldLw 1 "true" 0 "false" ;
VAL_ 2151956480 ClstrHMIRdy 1 "true" 0 "false" ;
VAL_ 2151956480 ClstrHMIAnmSt 7 "Unused and Reserved 3" 6 "Unused and Reserved 2" 5 "Unused and Reserved 1" 4 "Shutdown Play" 3 "Start Play" 2 "Welcome Play" 1 "Ready" 0 "Uninitialized" ;
VAL_ 2151940096 EstIntHorzDshSrfTmpM 0 "Don't Use Data" 1 "Use Data" ;
VAL_ 2151940096 EstIntRfSrfcTmpV 1 "Invalid" 0 "Valid" ;
VAL_ 2151940096 EstBulkIntAirTmpV 1 "Invalid" 0 "Valid" ;
VAL_ 2151940096 A2ERRAlrmReq 2 "Cancel Alarm" 1 "Set Alarm" 0 "No Action" ;
VAL_ 2151923712 HLOCCstCurrSetVal 3 "On Open Only" 2 "On" 1 "Off" 0 "No Action" ;
VAL_ 2151923712 HLOCCstSetAvail 1 "true" 0 "false" ;
VAL_ 2151923712 HLOCCA_Res4Avail 1 "true" 0 "false" ;
VAL_ 2151923712 HLOCCA_Res3Avail 1 "true" 0 "false" ;
VAL_ 2151923712 HLOCCA_Res2Avail 1 "true" 0 "false" ;
VAL_ 2151923712 HLOCCA_Res1Avail 1 "true" 0 "false" ;
VAL_ 2151923712 HLOCCA_OnOpnOnlyAvail 1 "true" 0 "false" ;
VAL_ 2151923712 HLOCCA_OnAvail 1 "true" 0 "false" ;
VAL_ 2151923712 HLOCCA_OffAvail 1 "true" 0 "false" ;
VAL_ 2151923712 A1ERRAlrmReq 2 "Cancel Alarm" 1 "Set Alarm" 0 "No Action" ;
VAL_ 2150645760 EnvIdRspSt1 3 "Environment_id_request" 2 "Incorrect_immo_id" 1 "Info_valid" 0 "No_info" ;
VAL_ 2152464384 RtLnDepWrnSt 3 "Service Alignment" 2 "Right Lane Alert" 1 "Right Lane Ready to Assist" 0 "Right Lane Not Ready to Assist" ;
VAL_ 2152464384 LftLnDepWrnSt 3 "Service Alignment" 2 "Left Lane Alert" 1 "Left Lane Ready to Assist" 0 "Left Lane Not Ready to Assist" ;
VAL_ 2152464384 TnDrvLDWOffUnbIO 1 "true" 0 "false" ;
VAL_ 2152464384 SrvcLnKpAstSysIO 1 "true" 0 "false" ;
VAL_ 2152464384 HndsOffStrWhlDtIO 1 "true" 0 "false" ;
VAL_ 2152464384 LnKpAstDisbldIO 1 "true" 0 "false" ;
VAL_ 2152464384 LKAIC_AdbWngLn 0 "Off" 1 "Left Front Speaker" 2 "Right Front Speaker" ;
VAL_ 2152464384 LKAIC_Ind2 1 "true" 0 "false" ;
VAL_ 2152464384 LKAIC_Ind1 1 "true" 0 "false" ;
VAL_ 2152464384 LKAIC_IndReq 0 "Off" 1 "Continuous Indication" 2 "Flash Rate #1 Indication" ;
VAL_ 2152464384 SrvcLaneDepWrnSysIO 1 "true" 0 "false" ;
VAL_ 2152464384 LDWIC_LnDepWAWLn 2 "Right Front Speaker" 1 "Left Front Speaker" 0 "Off" ;
VAL_ 2152464384 LDWIC_Ind2 1 "true" 0 "false" ;
VAL_ 2152464384 LDWIC_Ind1 1 "true" 0 "false" ;
VAL_ 2152464384 LDWIC_IndReq 2 "Flash Rate #1 Indication" 1 "Continuous Indication" 0 "Off" ;
VAL_ 2152464384 LaneDepWrnDisbldIO 1 "true" 0 "false" ;
VAL_ 2154971136 PassHCSeatSw3Act 1 "true" 0 "false" ;
VAL_ 2154971136 PassHCSeatSw2Act 1 "true" 0 "false" ;
VAL_ 2154971136 PassHCSeatSw1Act 1 "true" 0 "false" ;
VAL_ 2154971136 DrvHCSeatSw3Act 1 "true" 0 "false" ;
VAL_ 2154971136 DrvHCSeatSw2Act 1 "true" 0 "false" ;
VAL_ 2154971136 DrvHCSeatSw1Act 1 "true" 0 "false" ;
VAL_ 2154962944 PassHCSMInd3 1 "true" 0 "false" ;
VAL_ 2154962944 PassHCSMInd2 1 "true" 0 "false" ;
VAL_ 2154962944 PassHCSMInd1 1 "true" 0 "false" ;
VAL_ 2154962944 PassHCSMIndReq 3 "Flash Rate #2 Indication" 2 "Flash Rate #1 Indication" 1 "Continuous Indication" 0 "Off" ;
VAL_ 2154962944 PassHCSLSeatLev5 1 "true" 0 "false" ;
VAL_ 2154962944 PassHCSLSeatLev4 1 "true" 0 "false" ;
VAL_ 2154962944 PassHCSLSeatLev3 1 "true" 0 "false" ;
VAL_ 2154962944 PassHCSLSeatLev2 1 "true" 0 "false" ;
VAL_ 2154962944 PassHCSLSeatLev1 1 "true" 0 "false" ;
VAL_ 2154962944 PassHCSLIndReq 3 "Flash Rate #2 Indication" 2 "Flash Rate #1 Indication" 1 "Continuous Indication" 0 "Off" ;
VAL_ 2154962944 DrvHCSMInd1 1 "true" 0 "false" ;
VAL_ 2154962944 DrvHCSMIndReq 3 "Flash Rate #2 Indication" 2 "Flash Rate #1 Indication" 1 "Continuous Indication" 0 "Off" ;
VAL_ 2154962944 DrvHCSMInd3 1 "true" 0 "false" ;
VAL_ 2154962944 DrvHCSMInd2 1 "true" 0 "false" ;
VAL_ 2154962944 DrvHCSLSeatLev5 1 "true" 0 "false" ;
VAL_ 2154962944 DrvHCSLSeatLev4 1 "true" 0 "false" ;
VAL_ 2154962944 DrvHCSLSeatLev3 1 "true" 0 "false" ;
VAL_ 2154962944 DrvHCSLSeatLev2 1 "true" 0 "false" ;
VAL_ 2154962944 DrvHCSLSeatLev1 1 "true" 0 "false" ;
VAL_ 2154962944 DrvHCSLIndReq 3 "Flash Rate #2 Indication" 2 "Flash Rate #1 Indication" 1 "Continuous Indication" 0 "Off" ;
VAL_ 2156232704 ACSAlarm9 2 "Expired" 1 "Active" 0 "Inactive" ;
VAL_ 2156232704 ACSAlarm8 2 "Expired" 1 "Active" 0 "Inactive" ;
VAL_ 2156232704 ACSAlarm7 2 "Expired" 1 "Active" 0 "Inactive" ;
VAL_ 2156232704 ACSAlarm6 2 "Expired" 1 "Active" 0 "Inactive" ;
VAL_ 2156232704 ACSAlarm5 2 "Expired" 1 "Active" 0 "Inactive" ;
VAL_ 2156232704 ACSAlarm4 2 "Expired" 1 "Active" 0 "Inactive" ;
VAL_ 2156232704 ACSAlarm3 2 "Expired" 1 "Active" 0 "Inactive" ;
VAL_ 2156232704 ACSAlarm2 2 "Expired" 1 "Active" 0 "Inactive" ;
VAL_ 2156232704 ACSAlarm15 2 "Expired" 1 "Active" 0 "Inactive" ;
VAL_ 2156232704 ACSAlarm14 2 "Expired" 1 "Active" 0 "Inactive" ;
VAL_ 2156232704 ACSAlarm13 2 "Expired" 1 "Active" 0 "Inactive" ;
VAL_ 2156232704 ACSAlarm12 2 "Expired" 1 "Active" 0 "Inactive" ;
VAL_ 2156232704 ACSAlarm11 2 "Expired" 1 "Active" 0 "Inactive" ;
VAL_ 2156232704 ACSAlarm10 2 "Expired" 1 "Active" 0 "Inactive" ;
VAL_ 2156232704 ACSAlarm1 2 "Expired" 1 "Active" 0 "Inactive" ;
VAL_ 2156232704 ACSAlarm0 2 "Expired" 1 "Active" 0 "Inactive" ;
VAL_ 2154987520 WrlsChrgSysChrgStat 7 "Unused and Reserved 2" 6 "Unused and Reserved 1" 5 "WCS Overtemp Shutdown" 4 "Foreign Object Detected" 0 "WCS Not Present" 1 "Charging Inactive" 2 "Charging Active" 3 "Charging Complete" ;
VAL_ 2154987520 HdStV 1 "Invalid" 0 "Valid" ;
VAL_ 2154987520 HdSt 2 "Open" 1 "Ajar" 0 "Closed" ;
VAL_ 2154840064 CmpsZnNvrSet 1 "true" 0 "false" ;
VAL_ 2154840064 CmpsSatrtd 1 "true" 0 "false" ;
VAL_ 2154840064 CmpsDecZone 15 "Zone 15" 14 "Zone 14" 13 "Zone 13" 12 "Zone 12" 11 "Zone 11" 10 "Zone 10" 9 "Zone 9" 8 "Zone 8" 7 "Zone 7" 6 "Zone 6" 5 "Zone 5" 4 "Zone 4" 3 "Zone 3" 2 "Zone 2" 1 "Zone 1" 0 "Unknown" ;
VAL_ 2154840064 CmpsOctHdingDataSrc 1 "Calculated Value" 0 "Stored Value" ;
VAL_ 2154840064 CmpsOctHding 7 "NW (North West)" 6 "W (West)" 5 "SW (South West)" 4 "S (South)" 3 "SE (South East)" 2 "E (East)" 1 "NE (North East)" 0 "N (North)" ;
VAL_ 2154840064 CmpsModManCalInPrc 1 "true" 0 "false" ;
VAL_ 2154840064 CmpsModFltPrs 1 "true" 0 "false" ;
VAL_ 2154676224 CmpsModSlfTstReq 1 "Initiate Self Test" 0 "No Action" ;
VAL_ 2154676224 CmpsModManCalReq 1 "Calibrate Sensor" 0 "No Action" ;
VAL_ 2154676224 CmpsDecZonSetReq 1 "Set New Zone" 0 "No Request" ;
VAL_ 2154676224 CmpsDecZonCmndVal 15 "Zone 15" 14 "Zone 14" 13 "Zone 13" 12 "Zone 12" 11 "Zone 11" 10 "Zone 10" 9 "Zone 9" 8 "Zone 8" 7 "Zone 7" 6 "Zone 6" 5 "Zone 5" 4 "Zone 4" 3 "Zone 3" 2 "Zone 2" 1 "Zone 1" 0 "Unknown" ;
VAL_ 2154643456 HtrCoreInltClntTmpCalcV 1 "Invalid" 0 "Valid" ;
VAL_ 2154643456 AuxHtrAtv 1 "true" 0 "false" ;
SIG_GROUP_ 2156789760 TmofDay 1 : TOD_SecofMin TOD_MinofHr TOD_HrofDay;
SIG_GROUP_ 2158878720 ODIDynDataLstRq_CntrStck 1 : ODDLC_SubIdReqM ODDLC_WrpArnd ODDLC_ReqType ODDLC_ReqDir ODDLC_NmEntries ODDLC_Idx ODDLC_FUCID ODDLC_DspMID ODDLC_DataId ODDLC_BckgndFlag;
SIG_GROUP_ 2158870528 ODIDynDataLstRq_AxIP 1 : ODDLA_SubIdReqM ODDLA_WrpArnd ODDLA_ReqType ODDLA_ReqDir ODDLA_NmEntries ODDLA_Idx ODDLA_FUCID ODDLA_DspMID ODDLA_DataId ODDLA_BckgndFlag;
SIG_GROUP_ 2154692608 AudSrcStat 1 : ASSAudSrcStatCode ASSAudSrcChType ASSAudSrcType;
SIG_GROUP_ 2158862336 ODIActn_OTIM 1 : ODIAOT_FUCID ODIAOT_DspMID ODIAOT_DaTy ODIAOT_ActnVal ODIAOT_ActnID;
SIG_GROUP_ 2155249664 RRHCSModeIndCtrl 1 : RRHCSMInd3 RRHCSMInd2 RRHCSMInd1 RRHCSMIndReq;
SIG_GROUP_ 2155249664 RRHCSeatLevIndCtrl 1 : RRHCSLSeatLev5 RRHCSLSeatLev4 RRHCSLSeatLev3 RRHCSLSeatLev2 RRHCSLSeatLev1 RRHCSLIndReq;
SIG_GROUP_ 2155249664 RLHCSModeIndCtrl 1 : RLHCSMInd3 RLHCSMInd2 RLHCSMInd1 RLHCSMIndReq;
SIG_GROUP_ 2155249664 RLHCSeatLevIndCtrl 1 : RLHCSLSeatLev5 RLHCSLSeatLev4 RLHCSLSeatLev3 RLHCSLSeatLev2 RLHCSLSeatLev1 RLHCSLIndReq;
SIG_GROUP_ 2155184128 CrsCntrlSwStat 1 : CrsCntrlSwStCanSwAct CrsCntrlSwStSwDataIntgty CrsCntrlSwStSpdInSwAct CrsCntrlSwStSpDcSwAct CrsCntrlSwStSetSwAct CrsCntrlSwStResSwAct CrsCntrlSwStOnSwAct;
SIG_GROUP_ 2154921984 RFAFnc 1 : RFRmtCntFobNm RFRmtCntrlFobFnc RFRmtCntFobBatLw;
SIG_GROUP_ 2151940096 Alrm2ExtRngReq 1 : A2ERRAlrmTime A2ERRAlrmReq;
SIG_GROUP_ 2151923712 HLOCCstAvail 1 : HLOCCA_Res4Avail HLOCCA_Res3Avail HLOCCA_Res2Avail HLOCCA_Res1Avail HLOCCA_OnOpnOnlyAvail HLOCCA_OnAvail HLOCCA_OffAvail;
SIG_GROUP_ 2151923712 Alrm1ExtRngReq 1 : A1ERRAlrmTime A1ERRAlrmReq;
SIG_GROUP_ 2152464384 LnKpAstIndCntrl 1 : LKAIC_AdbWngLn LKAIC_Ind2 LKAIC_Ind1 LKAIC_IndReq;
SIG_GROUP_ 2152464384 LaneDepWrnIndCntrl 1 : LDWIC_LnDepWAWLn LDWIC_Ind2 LDWIC_Ind1 LDWIC_IndReq;
SIG_GROUP_ 2154962944 PassHCSModeIndCtrl 1 : PassHCSMInd3 PassHCSMInd2 PassHCSMInd1 PassHCSMIndReq;
SIG_GROUP_ 2154962944 PassHCSeatLevIndCtrl 1 : PassHCSLSeatLev5 PassHCSLSeatLev4 PassHCSLSeatLev3 PassHCSLSeatLev2 PassHCSLSeatLev1 PassHCSLIndReq;
SIG_GROUP_ 2154962944 DrvHCSModeIndCtrl 1 : DrvHCSMInd1 DrvHCSMIndReq DrvHCSMInd3 DrvHCSMInd2;
SIG_GROUP_ 2154962944 DrvHCSLevIndCtrl 1 : DrvHCSLSeatLev5 DrvHCSLSeatLev4 DrvHCSLSeatLev3 DrvHCSLSeatLev2 DrvHCSLSeatLev1 DrvHCSLIndReq;
SIG_GROUP_ 2156232704 AlrmClkStat 1 : ACSAlarm9 ACSAlarm8 ACSAlarm7 ACSAlarm6 ACSAlarm5 ACSAlarm4 ACSAlarm3 ACSAlarm2 ACSAlarm15 ACSAlarm14 ACSAlarm13 ACSAlarm12 ACSAlarm11 ACSAlarm10 ACSAlarm1 ACSAlarm0;
